VERSION ""

NS_ :

BS_:

BU_: EMS EAS

BO_ 2348941054 TC1: 8 Vector__XXX
 SG_ TrnsShftSlctorDisplayModeSwitch : 54|2@1+ (1,0) [0|3] "" Vector__XXX
 SG_ TransMode4 : 46|2@1+ (1,0) [0|3] "" Vector__XXX
 SG_ TransMode3 : 44|2@1+ (1,0) [0|3] "" Vector__XXX
 SG_ TransMode2 : 42|2@1+ (1,0) [0|3] "" Vector__XXX
 SG_ TransMode1 : 40|2@1+ (1,0) [0|3] "" Vector__XXX
 SG_ DisengageDiffLockRqCentralRear : 36|2@1+ (1,0) [0|3] "" Vector__XXX
 SG_ DisengageDiffLockRqCentralFront : 34|2@1+ (1,0) [0|3] "" Vector__XXX
 SG_ DisengageDiffLockRqCentral : 32|2@1+ (1,0) [0|3] "" Vector__XXX
 SG_ DisengageDiffLockRqRearAxle2 : 30|2@1+ (1,0) [0|3] "" Vector__XXX
 SG_ DisengageDiffLockRqRearAxle1 : 28|2@1+ (1,0) [0|3] "" Vector__XXX
 SG_ DisengageDiffLockRqFrontAxle2 : 26|2@1+ (1,0) [0|3] "" Vector__XXX
 SG_ DisengageDiffLockRqFrontAxle1 : 24|2@1+ (1,0) [0|3] "" Vector__XXX
 SG_ TransRqedGear : 16|8@1+ (1,-125) [-125|125] "" Vector__XXX
 SG_ RqedPercentClutchSlip : 8|8@1+ (0.4,0) [0|100] "%" Vector__XXX
 SG_ DisengageDrivelineRq : 4|2@1+ (1,0) [0|3] "" Vector__XXX
 SG_ TorqueConverterLockupDisableRq : 2|2@1+ (1,0) [0|3] "" Vector__XXX
 SG_ TransGearShiftInhibitRq : 0|2@1+ (1,0) [0|3] "" Vector__XXX

BO_ 2566839806 TC: 8 Vector__XXX
 SG_ EngTurboOilLevelSwitch : 30|2@1+ (1,0) [0|3] "" Vector__XXX
 SG_ EngTurbo1Speed : 8|16@1+ (4,0) [0|257020] "rpm" Vector__XXX
 SG_ EngTurboLubeOilPress1 : 0|8@1+ (4,0) [0|1000] "kPa" Vector__XXX

BO_ 2633911806 TAVG: 8 Vector__XXX
 SG_ EngTotalAverageFuelEconomy : 16|16@1+ (0.00195313,0) [0|125.5] "km/L" Vector__XXX
 SG_ EngTotalAverageFuelRate : 0|16@1+ (0.05,0) [0|3212.75] "L/h" Vector__XXX

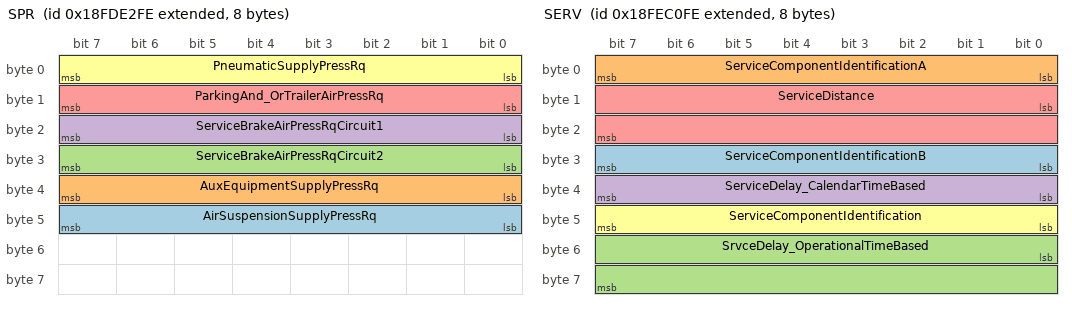
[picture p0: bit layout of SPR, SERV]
BO_ 2566775550 SPR: 8 Vector__XXX
 SG_ AirSuspensionSupplyPressRq : 40|8@1+ (8,0) [0|2000] "kPa" Vector__XXX
 SG_ AuxEquipmentSupplyPressRq : 32|8@1+ (8,0) [0|2000] "kPa" Vector__XXX
 SG_ ServiceBrakeAirPressRqCircuit2 : 24|8@1+ (8,0) [0|2000] "kPa" Vector__XXX
 SG_ ServiceBrakeAirPressRqCircuit1 : 16|8@1+ (8,0) [0|2000] "kPa" Vector__XXX
 SG_ ParkingAnd_OrTrailerAirPressRq : 8|8@1+ (8,0) [0|2000] "kPa" Vector__XXX
 SG_ PneumaticSupplyPressRq : 0|8@1+ (8,0) [0|2000] "kPa" Vector__XXX

BO_ 2566819838 SP2: 8 Vector__XXX
 SG_ EngExtlShutdownAirSupplyPress : 0|16@1+ (0.5,0) [0|32127.5] "kPa" Vector__XXX

BO_ 2566839038 SOFT: 8 Vector__XXX
 SG_ NmbrOfSftwrIdentificationFields : 0|8@1+ (1,0) [0|250] "steps" Vector__XXX

BO_ 2566841598 SHUTDOW: 8 Vector__XXX
 SG_ EngOverspeedTest : 54|2@1+ (1,0) [0|3] "" Vector__XXX
 SG_ EngAirShutoffCmdStatus : 52|2@1+ (1,0) [0|3] "" Vector__XXX
 SG_ EngAlarmOutputCmdStatus : 50|2@1+ (1,0) [0|3] "" Vector__XXX
 SG_ EngAlarmAcknowledge : 48|2@1+ (1,0) [0|3] "" Vector__XXX
 SG_ EngProtectionSystemConfig : 46|2@1+ (1,0) [0|3] "" Vector__XXX
 SG_ EngProtectionSystemTimerState : 38|2@1+ (1,0) [0|3] "" Vector__XXX
 SG_ EngPrtectionSystemTimerOverride : 36|2@1+ (1,0) [0|3] "" Vector__XXX
 SG_ EngPrtctnSystmApprchingShutdown : 34|2@1+ (1,0) [0|3] "" Vector__XXX
 SG_ EngPrtctionSystemHasShutdownEng : 32|2@1+ (1,0) [0|3] "" Vector__XXX
 SG_ EngWaitToStartLamp : 24|2@1+ (1,0) [0|3] "" Vector__XXX
 SG_ RefrigerantHighPressSwitch : 20|2@1+ (1,0) [0|3] "" Vector__XXX
 SG_ RefrigerantLowPressSwitch : 18|2@1+ (1,0) [0|3] "" Vector__XXX
 SG_ A_CHighPressFanSwitch : 16|2@1+ (1,0) [0|3] "" Vector__XXX
 SG_ EngIdleShutdownTimerFunction : 14|2@1+ (1,0) [0|3] "" Vector__XXX
 SG_ EngIdleShutdownTimerState : 6|2@1+ (1,0) [0|3] "" Vector__XXX
 SG_ EngIdleShutdownTimerOverride : 4|2@1+ (1,0) [0|3] "" Vector__XXX
 SG_ EngIdleShutdownDriverAlertMode : 2|2@1+ (1,0) [0|3] "" Vector__XXX
 SG_ EngIdleShutdownHasShutdownEng : 0|2@1+ (1,0) [0|3] "" Vector__XXX

BO_ 2566832382 SERV: 8 Vector__XXX
 SG_ ServiceComponentIdentificationB : 24|8@1+ (1,0) [0|250] "ID" Vector__XXX
 SG_ ServiceComponentIdentificationA : 0|8@1+ (1,0) [0|250] "ID" Vector__XXX
 SG_ SrvceDelay_OperationalTimeBased : 48|16@1+ (1,-31873) [-31873|32128] "hr" Vector__XXX
 SG_ ServiceDelay_CalendarTimeBased : 32|8@1+ (1,-125) [-125|125] "weeks" Vector__XXX
 SG_ ServiceDistance : 8|16@1+ (5,-159365) [-159365|160640] "km" Vector__XXX
 SG_ ServiceComponentIdentification : 40|8@1+ (1,0) [0|250] "ID" Vector__XXX

BO_ 2633928446 S2: 8 Vector__XXX
 SG_ TimeSinceLastService : 8|16@1+ (1,-31873) [-31873|32128] "hr" Vector__XXX
 SG_ ServiceComponentIdentification : 0|8@1+ (1,0) [0|250] "ID" Vector__XXX

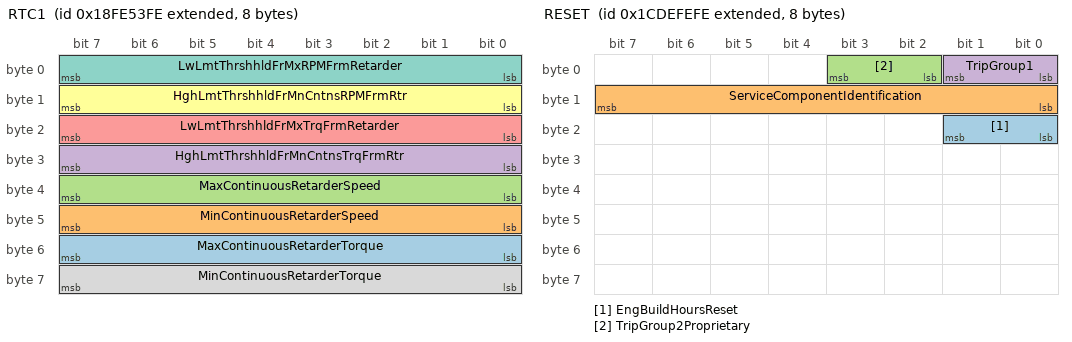
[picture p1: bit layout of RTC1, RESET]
BO_ 2566804478 RTC1: 8 Vector__XXX
 SG_ MaxContinuousRetarderTorque : 48|8@1+ (1,-125) [-125|125] "%" Vector__XXX
 SG_ MinContinuousRetarderSpeed : 40|8@1+ (32,0) [0|8000] "rpm" Vector__XXX
 SG_ MaxContinuousRetarderSpeed : 32|8@1+ (32,0) [0|8000] "rpm" Vector__XXX
 SG_ HghLmtThrshhldFrMnCntnsTrqFrmRtr : 24|8@1+ (1,-125) [-125|125] "%" Vector__XXX
 SG_ LwLmtThrshhldFrMxTrqFrmRetarder : 16|8@1+ (1,-125) [-125|125] "%" Vector__XXX
 SG_ HghLmtThrshhldFrMnCntnsRPMFrmRtr : 8|8@1+ (32,0) [0|8000] "rpm" Vector__XXX
 SG_ LwLmtThrshhldFrMxRPMFrmRetarder : 0|8@1+ (32,0) [0|8000] "rpm" Vector__XXX
 SG_ MinContinuousRetarderTorque : 56|8@1+ (1,-125) [-125|125] "%" Vector__XXX

BO_ 2566847486 RF: 8 Vector__XXX
 SG_ HydRetarderOilTemp : 8|8@1+ (1,-40) [-40|210] "deg" Vector__XXX
 SG_ HydRetarderPress : 0|8@1+ (16,0) [0|4000] "kPa" Vector__XXX

BO_ 2631859966 RESET: 8 Vector__XXX
 SG_ EngBuildHoursReset : 16|2@1+ (1,0) [0|3] "" Vector__XXX
 SG_ ServiceComponentIdentification : 8|8@1+ (1,0) [0|250] "ID" Vector__XXX
 SG_ TripGroup2Proprietary : 2|2@1+ (1,0) [0|3] "" Vector__XXX
 SG_ TripGroup1 : 0|2@1+ (1,0) [0|3] "" Vector__XXX

BO_ 2566840830 RC: 19 Vector__XXX
 SG_ PercentTorqueAtPeakTorquePoint5 : 144|8@1+ (1,-125) [-125|125] "%" Vector__XXX
 SG_ ReferenceRetarderTorque : 128|16@1+ (1,0) [0|64255] "Nm" Vector__XXX
 SG_ RetarderSpeedAtPeakTorquePoint5 : 112|16@1+ (0.125,0) [0|8031.875] "rpm" Vector__XXX
 SG_ PercentTorqueAtPoint4 : 104|8@1+ (1,-125) [-125|125] "%" Vector__XXX
 SG_ RetarderSpeedAtPoint4 : 88|16@1+ (0.125,0) [0|8031.875] "rpm" Vector__XXX
 SG_ PercentTorqueAtPoint3 : 80|8@1+ (1,-125) [-125|125] "%" Vector__XXX
 SG_ RetarderSpeedAtPoint3 : 64|16@1+ (0.125,0) [0|8031.875] "rpm" Vector__XXX
 SG_ PercentTorqueAtMaxSpeedPoint2 : 56|8@1+ (1,-125) [-125|125] "%" Vector__XXX
 SG_ MaxRetarderSpeedPoint2 : 40|16@1+ (0.125,0) [0|8031.875] "rpm" Vector__XXX
 SG_ PercentTorqueAtIdlePoint1 : 32|8@1+ (1,-125) [-125|125] "%" Vector__XXX
 SG_ RetarderSpeedAtIdlePoint1 : 16|16@1+ (0.125,0) [0|8031.875] "rpm" Vector__XXX
 SG_ RetarderCtrlMethod : 8|8@1+ (1,0) [0|250] "steps" Vector__XXX
 SG_ RetarderLocation : 4|4@1+ (1,0) [0|15] "" Vector__XXX
 SG_ RetarderType : 0|4@1+ (1,0) [0|15] "" Vector__XXX

BO_ 2633930238 RBI: 8 Vector__XXX
 SG_ EngOperationTimeSinceRebuild : 0|32@1+ (1,0) [0|4211081215] "s" Vector__XXX

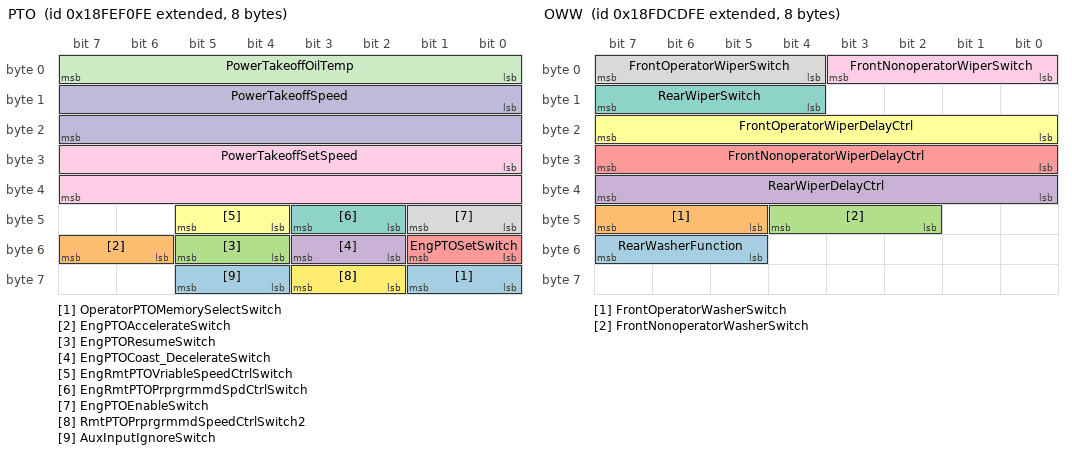
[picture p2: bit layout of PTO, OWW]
BO_ 2566844670 PTO: 8 Vector__XXX
 SG_ OperatorPTOMemorySelectSwitch : 56|2@1+ (1,0) [0|3] "" Vector__XXX
 SG_ EngPTOAccelerateSwitch : 54|2@1+ (1,0) [0|3] "" Vector__XXX
 SG_ EngPTOResumeSwitch : 52|2@1+ (1,0) [0|3] "" Vector__XXX
 SG_ EngPTOCoast_DecelerateSwitch : 50|2@1+ (1,0) [0|3] "" Vector__XXX
 SG_ EngPTOSetSwitch : 48|2@1+ (1,0) [0|3] "" Vector__XXX
 SG_ EngRmtPTOVriableSpeedCtrlSwitch : 44|2@1+ (1,0) [0|3] "" Vector__XXX
 SG_ EngRmtPTOPrprgrmmdSpdCtrlSwitch : 42|2@1+ (1,0) [0|3] "" Vector__XXX
 SG_ EngPTOEnableSwitch : 40|2@1+ (1,0) [0|3] "" Vector__XXX
 SG_ PowerTakeoffSetSpeed : 24|16@1+ (0.125,0) [0|8031.875] "rpm" Vector__XXX
 SG_ PowerTakeoffSpeed : 8|16@1+ (0.125,0) [0|8031.875] "rpm" Vector__XXX
 SG_ PowerTakeoffOilTemp : 0|8@1+ (1,-40) [-40|210] "deg" Vector__XXX
 SG_ RmtPTOPrprgrmmdSpeedCtrlSwitch2 : 58|2@1+ (1,0) [0|3] "" Vector__XXX
 SG_ AuxInputIgnoreSwitch : 60|2@1+ (1,0) [0|3] "" Vector__XXX

BO_ 2566770174 OWW: 8 Vector__XXX
 SG_ RearWasherFunction : 53|3@1+ (1,0) [0|7] "" Vector__XXX
 SG_ FrontOperatorWasherSwitch : 45|3@1+ (1,0) [0|7] "" Vector__XXX
 SG_ FrontNonoperatorWasherSwitch : 42|3@1+ (1,0) [0|7] "" Vector__XXX
 SG_ RearWiperDelayCtrl : 32|8@1+ (0.4,0) [0|100] "%" Vector__XXX
 SG_ FrontNonoperatorWiperDelayCtrl : 24|8@1+ (0.4,0) [0|100] "%" Vector__XXX
 SG_ FrontOperatorWiperDelayCtrl : 16|8@1+ (0.4,0) [0|100] "%" Vector__XXX
 SG_ RearWiperSwitch : 12|4@1+ (1,0) [0|15] "" Vector__XXX
 SG_ FrontOperatorWiperSwitch : 4|4@1+ (1,0) [0|15] "" Vector__XXX
 SG_ FrontNonoperatorWiperSwitch : 0|4@1+ (1,0) [0|15] "" Vector__XXX

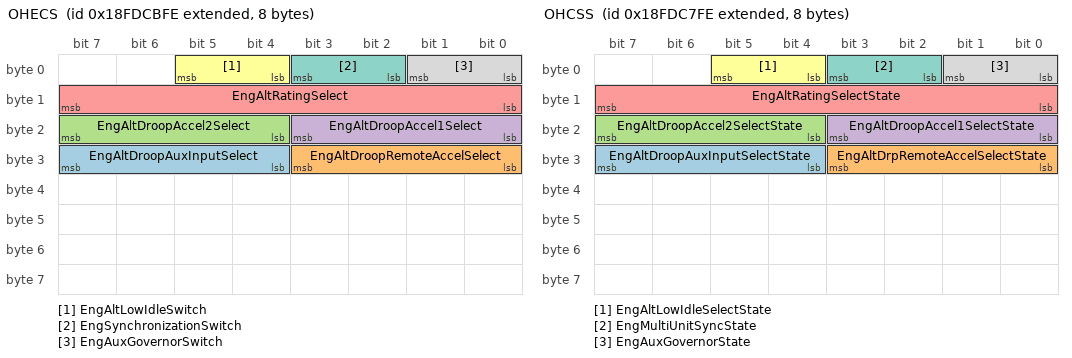
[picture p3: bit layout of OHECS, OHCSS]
BO_ 2566769662 OHECS: 8 Vector__XXX
 SG_ EngAltDroopAuxInputSelect : 28|4@1+ (1,0) [0|15] "" Vector__XXX
 SG_ EngAltDroopRemoteAccelSelect : 24|4@1+ (1,0) [0|15] "" Vector__XXX
 SG_ EngAltDroopAccel2Select : 20|4@1+ (1,0) [0|15] "" Vector__XXX
 SG_ EngAltDroopAccel1Select : 16|4@1+ (1,0) [0|15] "" Vector__XXX
 SG_ EngAltRatingSelect : 8|8@1+ (1,0) [0|255] "" Vector__XXX
 SG_ EngAltLowIdleSwitch : 4|2@1+ (1,0) [0|3] "" Vector__XXX
 SG_ EngSynchronizationSwitch : 2|2@1+ (1,0) [0|3] "" Vector__XXX
 SG_ EngAuxGovernorSwitch : 0|2@1+ (1,0) [0|3] "" Vector__XXX

BO_ 2566768638 OHCSS: 8 Vector__XXX
 SG_ EngAltDroopAuxInputSelectState : 28|4@1+ (1,0) [0|15] "" Vector__XXX
 SG_ EngAltDrpRemoteAccelSelectState : 24|4@1+ (1,0) [0|15] "" Vector__XXX
 SG_ EngAltDroopAccel2SelectState : 20|4@1+ (1,0) [0|15] "" Vector__XXX
 SG_ EngAltDroopAccel1SelectState : 16|4@1+ (1,0) [0|15] "" Vector__XXX
 SG_ EngAltRatingSelectState : 8|8@1+ (1,0) [0|255] "" Vector__XXX
 SG_ EngAltLowIdleSelectState : 4|2@1+ (1,0) [0|3] "" Vector__XXX
 SG_ EngMultiUnitSyncState : 2|2@1+ (1,0) [0|3] "" Vector__XXX
 SG_ EngAuxGovernorState : 0|2@1+ (1,0) [0|3] "" Vector__XXX

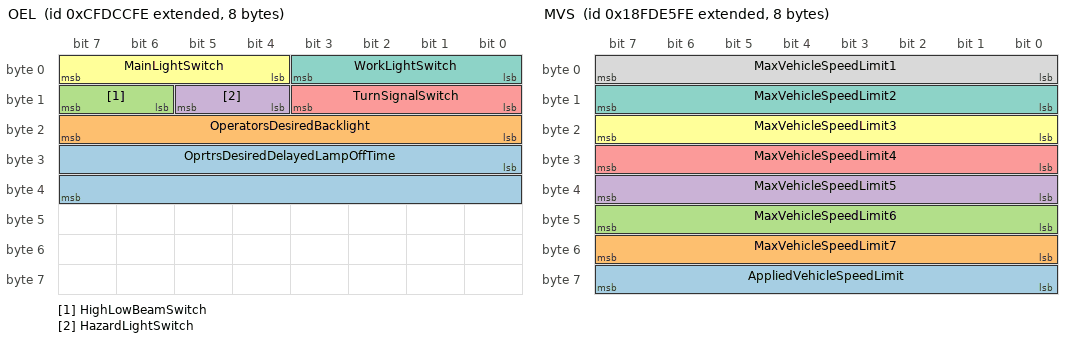
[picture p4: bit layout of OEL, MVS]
BO_ 2365443326 OEL: 8 Vector__XXX
 SG_ OprtrsDesiredDelayedLampOffTime : 24|16@1+ (1,0) [0|64255] "s" Vector__XXX
 SG_ OperatorsDesiredBacklight : 16|8@1+ (0.4,0) [0|100] "%" Vector__XXX
 SG_ HighLowBeamSwitch : 14|2@1+ (1,0) [0|3] "" Vector__XXX
 SG_ HazardLightSwitch : 12|2@1+ (1,0) [0|3] "" Vector__XXX
 SG_ TurnSignalSwitch : 8|4@1+ (1,0) [0|15] "" Vector__XXX
 SG_ MainLightSwitch : 4|4@1+ (1,0) [0|15] "" Vector__XXX
 SG_ WorkLightSwitch : 0|4@1+ (1,0) [0|15] "" Vector__XXX

BO_ 2566776318 MVS: 8 Vector__XXX
 SG_ AppliedVehicleSpeedLimit : 56|8@1+ (1,0) [0|250] "km/h" Vector__XXX
 SG_ MaxVehicleSpeedLimit7 : 48|8@1+ (1,0) [0|250] "km/h" Vector__XXX
 SG_ MaxVehicleSpeedLimit6 : 40|8@1+ (1,0) [0|250] "km/h" Vector__XXX
 SG_ MaxVehicleSpeedLimit5 : 32|8@1+ (1,0) [0|250] "km/h" Vector__XXX
 SG_ MaxVehicleSpeedLimit4 : 24|8@1+ (1,0) [0|250] "km/h" Vector__XXX
 SG_ MaxVehicleSpeedLimit3 : 16|8@1+ (1,0) [0|250] "km/h" Vector__XXX
 SG_ MaxVehicleSpeedLimit2 : 8|8@1+ (1,0) [0|250] "km/h" Vector__XXX
 SG_ MaxVehicleSpeedLimit1 : 0|8@1+ (1,0) [0|250] "km/h" Vector__XXX

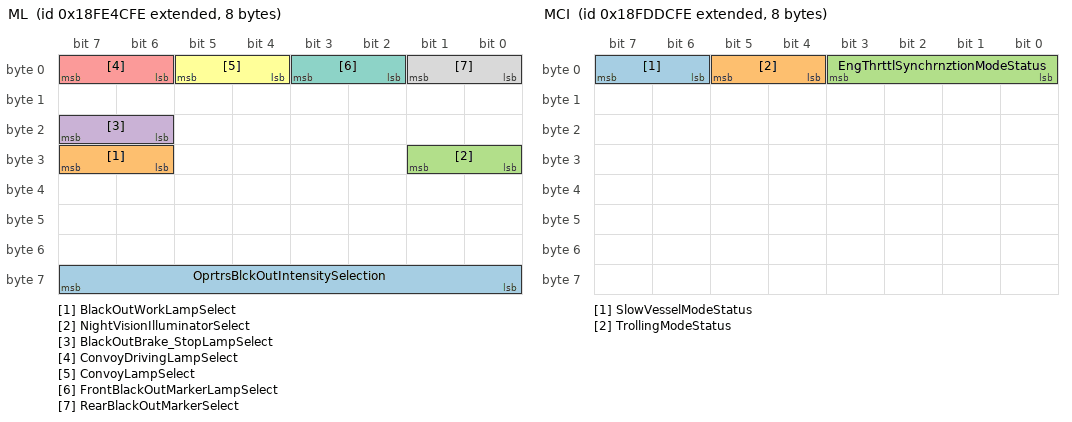
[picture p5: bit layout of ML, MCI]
BO_ 2566802686 ML: 8 Vector__XXX
 SG_ OprtrsBlckOutIntensitySelection : 56|8@1+ (0.4,0) [0|100] "%" Vector__XXX
 SG_ BlackOutWorkLampSelect : 30|2@1+ (1,0) [0|3] "" Vector__XXX
 SG_ NightVisionIlluminatorSelect : 24|2@1+ (1,0) [0|3] "" Vector__XXX
 SG_ BlackOutBrake_StopLampSelect : 22|2@1+ (1,0) [0|3] "" Vector__XXX
 SG_ ConvoyDrivingLampSelect : 6|2@1+ (1,0) [0|3] "" Vector__XXX
 SG_ ConvoyLampSelect : 4|2@1+ (1,0) [0|3] "" Vector__XXX
 SG_ FrontBlackOutMarkerLampSelect : 2|2@1+ (1,0) [0|3] "" Vector__XXX
 SG_ RearBlackOutMarkerSelect : 0|2@1+ (1,0) [0|3] "" Vector__XXX

BO_ 2566774014 MCI: 8 Vector__XXX
 SG_ SlowVesselModeStatus : 6|2@1+ (1,0) [0|3] "" Vector__XXX
 SG_ TrollingModeStatus : 4|2@1+ (1,0) [0|3] "" Vector__XXX
 SG_ EngThrttlSynchrnztionModeStatus : 0|4@1+ (1,0) [0|15] "" Vector__XXX

BO_ 2566823166 MBT3: 8 Vector__XXX
 SG_ EngMainBearing11Temp : 32|16@1+ (0.03125,-273) [-273|1735] "deg" Vector__XXX
 SG_ EngMainBearing10Temp : 16|16@1+ (0.03125,-273) [-273|1735] "deg" Vector__XXX
 SG_ EngMainBearing9Temp : 0|16@1+ (0.03125,-273) [-273|1735] "deg" Vector__XXX

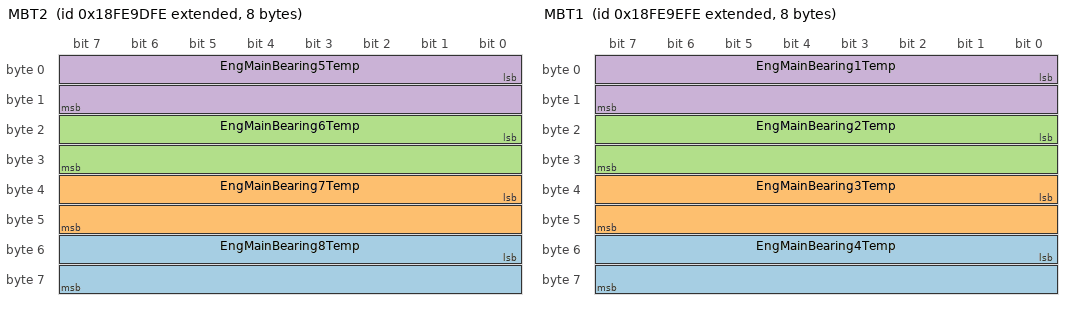
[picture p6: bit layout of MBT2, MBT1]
BO_ 2566823422 MBT2: 8 Vector__XXX
 SG_ EngMainBearing8Temp : 48|16@1+ (0.03125,-273) [-273|1735] "deg" Vector__XXX
 SG_ EngMainBearing7Temp : 32|16@1+ (0.03125,-273) [-273|1735] "deg" Vector__XXX
 SG_ EngMainBearing6Temp : 16|16@1+ (0.03125,-273) [-273|1735] "deg" Vector__XXX
 SG_ EngMainBearing5Temp : 0|16@1+ (0.03125,-273) [-273|1735] "deg" Vector__XXX

BO_ 2566823678 MBT1: 8 Vector__XXX
 SG_ EngMainBearing4Temp : 48|16@1+ (0.03125,-273) [-273|1735] "deg" Vector__XXX
 SG_ EngMainBearing3Temp : 32|16@1+ (0.03125,-273) [-273|1735] "deg" Vector__XXX
 SG_ EngMainBearing2Temp : 16|16@1+ (0.03125,-273) [-273|1735] "deg" Vector__XXX
 SG_ EngMainBearing1Temp : 0|16@1+ (0.03125,-273) [-273|1735] "deg" Vector__XXX

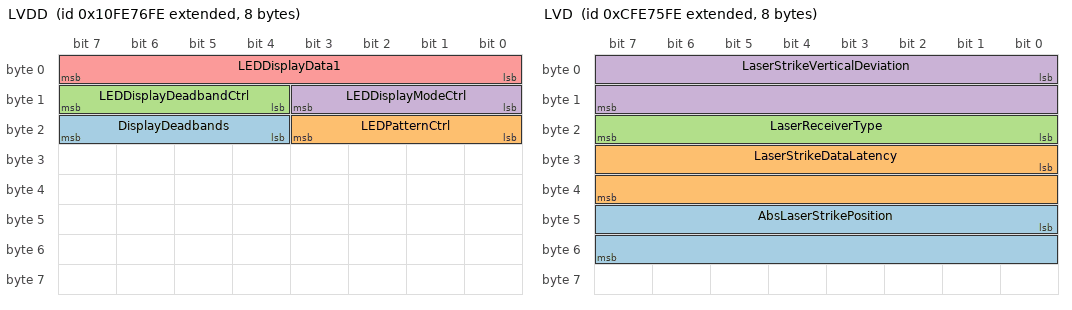
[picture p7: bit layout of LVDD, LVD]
BO_ 2432595710 LVDD: 8 Vector__XXX
 SG_ DisplayDeadbands : 20|4@1+ (1,0) [0|15] "" Vector__XXX
 SG_ LEDPatternCtrl : 16|4@1+ (1,0) [0|15] "" Vector__XXX
 SG_ LEDDisplayDeadbandCtrl : 12|4@1+ (1,0) [0|15] "" Vector__XXX
 SG_ LEDDisplayModeCtrl : 8|4@1+ (1,0) [0|15] "" Vector__XXX
 SG_ LEDDisplayData1 : 0|8@1+ (1,0) [0|255] "" Vector__XXX

BO_ 2365486590 LVD: 8 Vector__XXX
 SG_ AbsLaserStrikePosition : 40|16@1+ (0.1,0) [0|6425.5] "mm" Vector__XXX
 SG_ LaserStrikeDataLatency : 24|16@1+ (51.2,0) [0|3.289856] "s" Vector__XXX
 SG_ LaserReceiverType : 16|8@1+ (1,0) [0|250] "" Vector__XXX
 SG_ LaserStrikeVerticalDeviation : 0|16@1+ (0.1,-2800) [-2800|3225.5] "mm" Vector__XXX

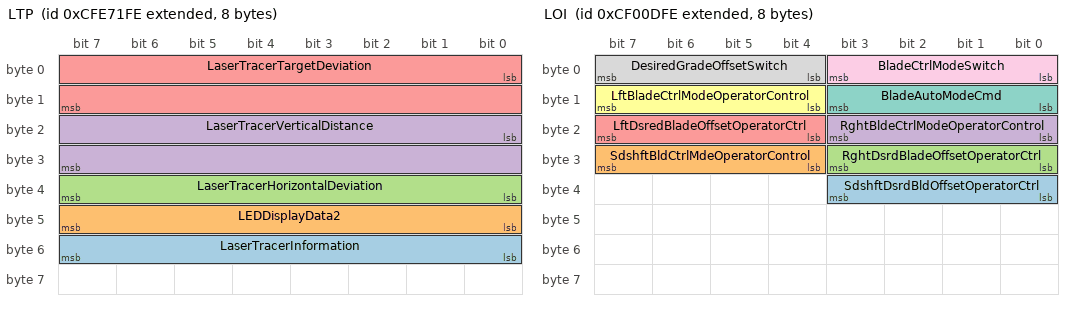
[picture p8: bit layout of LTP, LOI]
BO_ 2365485566 LTP: 8 Vector__XXX
 SG_ LaserTracerInformation : 48|8@1+ (1,0) [0|255] "" Vector__XXX
 SG_ LEDDisplayData2 : 40|8@1+ (1,0) [0|255] "" Vector__XXX
 SG_ LaserTracerHorizontalDeviation : 32|8@1+ (1,0) [0|250] "%" Vector__XXX
 SG_ LaserTracerVerticalDistance : 16|16@1+ (0.1,0) [0|6425.5] "mm" Vector__XXX
 SG_ LaserTracerTargetDeviation : 0|16@1+ (0.1,-2800) [-2800|3225.5] "mm" Vector__XXX

BO_ 2633939454 LTFI: 22 Vector__XXX
 SG_ TripDriveFuelEconomy : 160|16@1+ (0.00195313,0) [0|125.5] "km/L" Vector__XXX
 SG_ TripCruiseFuelUsed : 128|32@1+ (0.5,0) [0|2105540607.5] "kg" Vector__XXX
 SG_ TripVehicleIdleFuelUsed : 96|32@1+ (0.5,0) [0|2105540607.5] "kg" Vector__XXX
 SG_ TripPTONonmovingFuelUsed : 64|32@1+ (0.5,0) [0|2105540607.5] "kg" Vector__XXX
 SG_ TripPTOMovingFuelUsed : 32|32@1+ (0.5,0) [0|2105540607.5] "kg" Vector__XXX
 SG_ TripDriveFuelUsed : 0|32@1+ (0.5,0) [0|2105540607.5] "kg" Vector__XXX

BO_ 2365486334 LSP: 8 Vector__XXX
 SG_ BldHeightSetPointHighResolution : 16|32@1+ (0.1,-209.7152) [-209.7152|211.3929215] "m" Vector__XXX
 SG_ ModifySetPoint : 0|16@1+ (0.1,-2800) [-2800|3225.5] "mm" Vector__XXX

BO_ 2364542462 LOI: 8 Vector__XXX
 SG_ SdshftDsrdBldOffsetOperatorCtrl : 32|4@1+ (1,0) [0|15] "" Vector__XXX
 SG_ SdshftBldCtrlMdeOperatorControl : 28|4@1+ (1,0) [0|15] "" Vector__XXX
 SG_ RghtDsrdBladeOffsetOperatorCtrl : 24|4@1+ (1,0) [0|15] "" Vector__XXX
 SG_ RghtBldeCtrlModeOperatorControl : 16|4@1+ (1,0) [0|15] "" Vector__XXX
 SG_ LftDsredBladeOffsetOperatorCtrl : 20|4@1+ (1,0) [0|15] "" Vector__XXX
 SG_ LftBladeCtrlModeOperatorControl : 12|4@1+ (1,0) [0|15] "" Vector__XXX
 SG_ BladeAutoModeCmd : 8|4@1+ (1,0) [0|15] "" Vector__XXX
 SG_ DesiredGradeOffsetSwitch : 4|4@1+ (1,0) [0|15] "" Vector__XXX
 SG_ BladeCtrlModeSwitch : 0|4@1+ (1,0) [0|15] "" Vector__XXX

BO_ 2365486078 LMP: 8 Vector__XXX
 SG_ MastPos : 0|16@1+ (0.1,-2800) [-2800|3225.5] "mm" Vector__XXX

BO_ 2633937918 LFI: 8 Vector__XXX
 SG_ TripAverageFuelRate : 32|16@1+ (0.05,0) [0|3212.75] "kg/h" Vector__XXX
 SG_ TotalEngPTOFuelUsed : 0|32@1+ (0.5,0) [0|2105540607.5] "kg" Vector__XXX

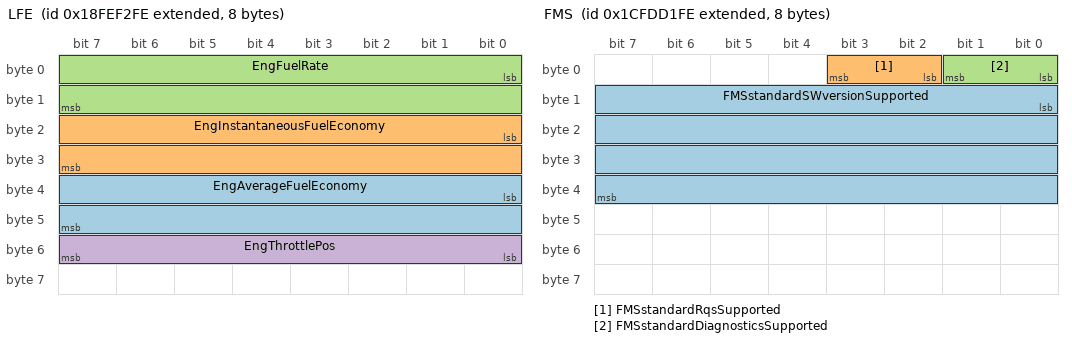
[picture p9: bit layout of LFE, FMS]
BO_ 2566845182 LFE: 8 Vector__XXX
 SG_ EngAverageFuelEconomy : 32|16@1+ (0.001953125,0) [0|125.5] "km/L" Vector__XXX
 SG_ EngInstantaneousFuelEconomy : 16|16@1+ (0.001953125,0) [0|125.5] "km/L" Vector__XXX
 SG_ EngFuelRate : 0|16@1+ (0.05,0) [0|3212.75] "L/h" Vector__XXX
 SG_ EngThrottlePos : 48|8@1+ (0.4,0) [0|100] "%" Vector__XXX

BO_ 2566842878 LFC: 8 Vector__XXX
 SG_ EngTotalFuelUsed : 32|32@1+ (0.5,0) [0|2105540607.5] "L" Vector__XXX
 SG_ EngTripFuel : 0|32@1+ (0.5,0) [0|2105540607.5] "L" Vector__XXX

BO_ 2633883646 FWD: 8 Vector__XXX
 SG_ FrontWheelDriveActuatorStatus : 0|2@1+ (1,0) [0|3] "" Vector__XXX

BO_ 2633880062 FMS: 8 Vector__XXX
 SG_ FMSstandardSWversionSupported : 8|32@1+ (1,0) [0|255] "" Vector__XXX
 SG_ FMSstandardRqsSupported : 2|2@1+ (1,0) [0|3] "" Vector__XXX
 SG_ FMSstandardDiagnosticsSupported : 0|2@1+ (1,0) [0|3] "" Vector__XXX

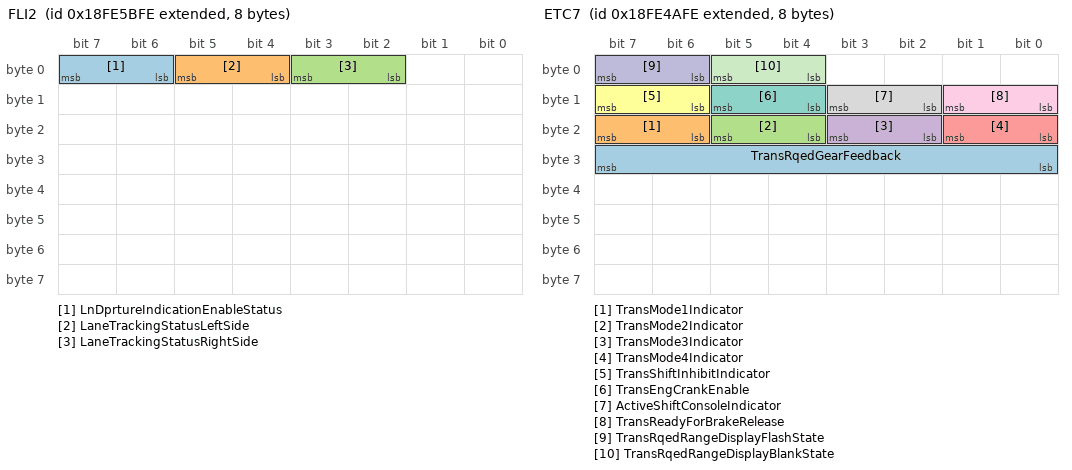
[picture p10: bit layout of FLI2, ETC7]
BO_ 2566806526 FLI2: 8 Vector__XXX
 SG_ LnDprtureIndicationEnableStatus : 6|2@1+ (1,0) [0|3] "" Vector__XXX
 SG_ LaneTrackingStatusLeftSide : 4|2@1+ (1,0) [0|3] "" Vector__XXX
 SG_ LaneTrackingStatusRightSide : 2|2@1+ (1,0) [0|3] "" Vector__XXX

BO_ 2431649790 FLI1: 8 Vector__XXX
 SG_ LaneDepartureImminentLeftSide : 6|2@1+ (1,0) [0|3] "" Vector__XXX
 SG_ LaneDepartureImminentRightSide : 4|2@1+ (1,0) [0|3] "" Vector__XXX

BO_ 2633929214 FL: 8 Vector__XXX
 SG_ EngFuelLeakage2 : 2|2@1+ (1,0) [0|3] "" Vector__XXX
 SG_ EngFuelLeakage1 : 0|2@1+ (1,0) [0|3] "" Vector__XXX

BO_ 2566831614 FD: 8 Vector__XXX
 SG_ FanSpeed : 16|16@1+ (0.125,0) [0|8031.875] "rpm" Vector__XXX
 SG_ FanDriveState : 8|4@1+ (1,0) [0|15] "" Vector__XXX
 SG_ EstPercentFanSpeed : 0|8@1+ (0.4,0) [0|100] "%" Vector__XXX

BO_ 2566820094 ETH: 33 Vector__XXX
 SG_ EngTorqueLimit6AxleInput : 248|16@1+ (2,0) [0|128510] "Nm" Vector__XXX
 SG_ EngTorqueLimit5Switch : 232|16@1+ (1,0) [0|64255] "Nm" Vector__XXX
 SG_ EngTorqueLimit4Trans : 216|16@1+ (1,0) [0|64255] "Nm" Vector__XXX
 SG_ EngTorqueLimit3Trans : 200|16@1+ (1,0) [0|64255] "Nm" Vector__XXX
 SG_ TransGearRatio3 : 184|16@1+ (0.01,0) [0|642.55] "" Vector__XXX
 SG_ EngTorqueLimit2Trans : 168|16@1+ (1,0) [0|64255] "Nm" Vector__XXX
 SG_ TransGearRatio2 : 152|16@1+ (0.01,0) [0|642.55] "" Vector__XXX
 SG_ EngTorqueLimit1Trans : 136|16@1+ (1,0) [0|64255] "Nm" Vector__XXX
 SG_ TransGearRatio1 : 120|16@1+ (0.01,0) [0|642.55] "" Vector__XXX
 SG_ EngTorqueLimitFeature : 114|3@1+ (1,0) [0|7] "" Vector__XXX
 SG_ TorqueLimitingFeatureStatus : 112|2@1+ (1,0) [0|3] "" Vector__XXX
 SG_ CalibRecordDurationTime : 80|32@1+ (0.05,0) [0|210554060.75] "hr" Vector__XXX
 SG_ CalibRecordStartYear : 72|8@1+ (1,1985) [1985|2235] "years" Vector__XXX
 SG_ CalibRecordStartDay : 64|8@1+ (0.25,0) [0|62.5] "days" Vector__XXX
 SG_ CalibRecordStartMonth : 56|8@1+ (1,0) [0|250] "months" Vector__XXX
 SG_ EngPeakTorque2 : 40|16@1+ (1,0) [0|64255] "Nm" Vector__XXX
 SG_ EngPeakTorque1 : 24|16@1+ (1,0) [0|64255] "Nm" Vector__XXX
 SG_ EngPower : 8|16@1+ (0.5,0) [0|32127.5] "kW" Vector__XXX
 SG_ NumberOfEngTorqueHistoryRecords : 0|8@1+ (1,0) [0|250] "records" Vector__XXX

BO_ 2364542206 ETC8: 8 Vector__XXX
 SG_ TransTorqueConverterRatio : 0|16@1+ (0.001,0) [0|64.255] "" Vector__XXX

BO_ 2566802174 ETC7: 8 Vector__XXX
 SG_ TransRqedGearFeedback : 24|8@1+ (1,-125) [-125|125] "" Vector__XXX
 SG_ TransMode1Indicator : 22|2@1+ (1,0) [0|3] "" Vector__XXX
 SG_ TransMode2Indicator : 20|2@1+ (1,0) [0|3] "" Vector__XXX
 SG_ TransMode3Indicator : 18|2@1+ (1,0) [0|3] "" Vector__XXX
 SG_ TransMode4Indicator : 16|2@1+ (1,0) [0|3] "" Vector__XXX
 SG_ TransShiftInhibitIndicator : 14|2@1+ (1,0) [0|3] "" Vector__XXX
 SG_ TransEngCrankEnable : 12|2@1+ (1,0) [0|3] "" Vector__XXX
 SG_ ActiveShiftConsoleIndicator : 10|2@1+ (1,0) [0|3] "" Vector__XXX
 SG_ TransReadyForBrakeRelease : 8|2@1+ (1,0) [0|3] "" Vector__XXX
 SG_ TransRqedRangeDisplayFlashState : 6|2@1+ (1,0) [0|3] "" Vector__XXX
 SG_ TransRqedRangeDisplayBlankState : 4|2@1+ (1,0) [0|3] "" Vector__XXX

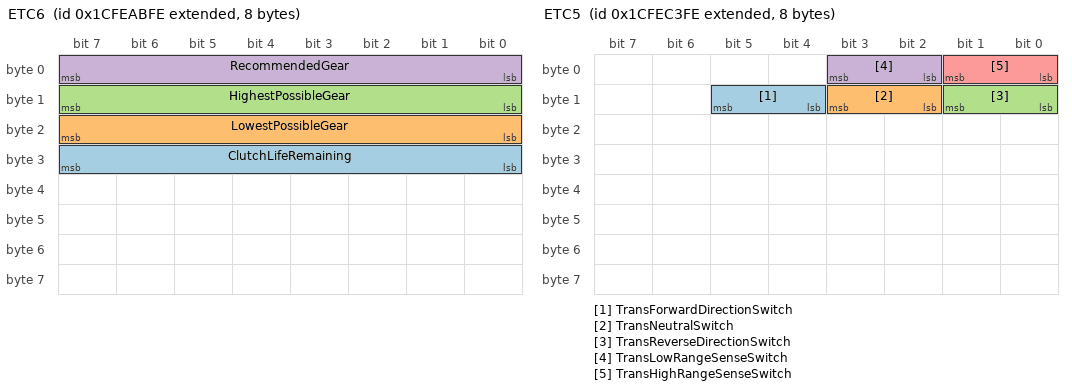
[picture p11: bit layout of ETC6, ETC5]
BO_ 2633935870 ETC6: 8 Vector__XXX
 SG_ ClutchLifeRemaining : 24|8@1+ (0.4,0) [0|100] "%" Vector__XXX
 SG_ LowestPossibleGear : 16|8@1+ (1,-125) [-125|125] "" Vector__XXX
 SG_ HighestPossibleGear : 8|8@1+ (1,-125) [-125|125] "" Vector__XXX
 SG_ RecommendedGear : 0|8@1+ (1,-125) [-125|125] "" Vector__XXX

BO_ 2633942014 ETC5: 8 Vector__XXX
 SG_ TransForwardDirectionSwitch : 12|2@1+ (1,0) [0|3] "" Vector__XXX
 SG_ TransNeutralSwitch : 10|2@1+ (1,0) [0|3] "" Vector__XXX
 SG_ TransReverseDirectionSwitch : 8|2@1+ (1,0) [0|3] "" Vector__XXX
 SG_ TransLowRangeSenseSwitch : 2|2@1+ (1,0) [0|3] "" Vector__XXX
 SG_ TransHighRangeSenseSwitch : 0|2@1+ (1,0) [0|3] "" Vector__XXX

BO_ 2633942526 ETC4: 8 Vector__XXX
 SG_ TransSynchronizerBrakeValue : 8|8@1+ (0.4,0) [0|100] "%" Vector__XXX
 SG_ TransSynchronizerClutchValue : 0|8@1+ (0.4,0) [0|100] "%" Vector__XXX

BO_ 2633943038 ETC3: 8 Vector__XXX
 SG_ TransInertiaBrakeActuator : 46|2@1+ (1,0) [0|3] "" Vector__XXX
 SG_ TransDefuelActuator : 44|2@1+ (1,0) [0|3] "" Vector__XXX
 SG_ TransLockupClutchActuator : 42|2@1+ (1,0) [0|3] "" Vector__XXX
 SG_ TransClutchActuator : 40|2@1+ (1,0) [0|3] "" Vector__XXX
 SG_ TransSplitterIndirectActuator : 38|2@1+ (1,0) [0|3] "" Vector__XXX
 SG_ TransSplitterDirectActuator : 36|2@1+ (1,0) [0|3] "" Vector__XXX
 SG_ TransRangeLowActuator : 34|2@1+ (1,0) [0|3] "" Vector__XXX
 SG_ TransRangeHighActuator : 32|2@1+ (1,0) [0|3] "" Vector__XXX
 SG_ TransShiftFingerGearActuator2 : 30|2@1+ (1,0) [0|3] "" Vector__XXX
 SG_ TransShiftFingerRailActuator2 : 28|2@1+ (1,0) [0|3] "" Vector__XXX
 SG_ TransShiftFingerGearActuator1 : 26|2@1+ (1,0) [0|3] "" Vector__XXX
 SG_ TransShiftFingerRailActuator1 : 24|2@1+ (1,0) [0|3] "" Vector__XXX
 SG_ TrnsShftFngrCenterRailIndicator : 20|2@1+ (1,0) [0|3] "" Vector__XXX
 SG_ TrnsShftFngrEngagementIndicator : 18|2@1+ (1,0) [0|3] "" Vector__XXX
 SG_ TrnsShiftFingerNeutralIndicator : 16|2@1+ (1,0) [0|3] "" Vector__XXX
 SG_ TransShiftFingerRailPos : 8|8@1+ (0.4,0) [0|100] "%" Vector__XXX
 SG_ TransShiftFingerGearPos : 0|8@1+ (0.4,0) [0|100] "%" Vector__XXX

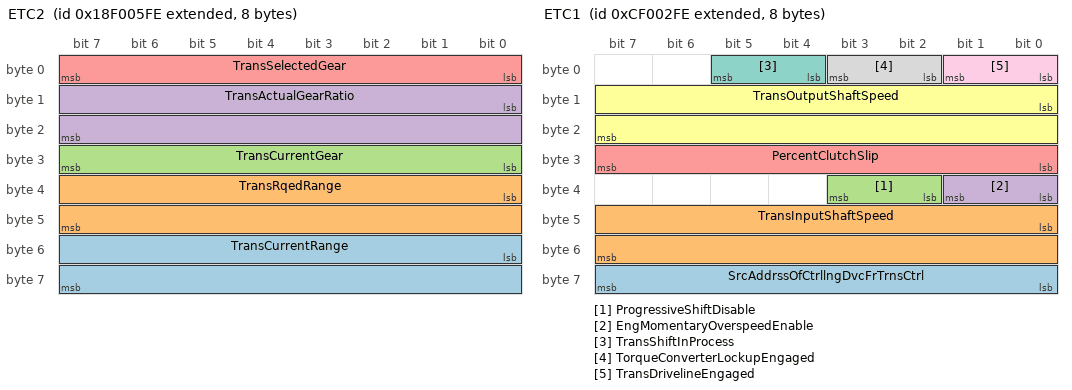
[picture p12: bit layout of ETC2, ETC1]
BO_ 2565867006 ETC2: 8 Vector__XXX
 SG_ TransCurrentRange : 48|16@1+ (1,0) [0|255] "" Vector__XXX
 SG_ TransRqedRange : 32|16@1+ (1,0) [0|255] "" Vector__XXX
 SG_ TransCurrentGear : 24|8@1+ (1,-125) [-125|125] "" Vector__XXX
 SG_ TransActualGearRatio : 8|16@1+ (0.001,0) [0|64.255] "" Vector__XXX
 SG_ TransSelectedGear : 0|8@1+ (1,-125) [-125|125] "" Vector__XXX

BO_ 2364539646 ETC1: 8 Vector__XXX
 SG_ SrcAddrssOfCtrllngDvcFrTrnsCtrl : 56|8@1+ (1,0) [0|255] "" Vector__XXX
 SG_ TransInputShaftSpeed : 40|16@1+ (0.125,0) [0|8031.875] "rpm" Vector__XXX
 SG_ ProgressiveShiftDisable : 34|2@1+ (1,0) [0|3] "" Vector__XXX
 SG_ EngMomentaryOverspeedEnable : 32|2@1+ (1,0) [0|3] "" Vector__XXX
 SG_ PercentClutchSlip : 24|8@1+ (0.4,0) [0|100] "%" Vector__XXX
 SG_ TransOutputShaftSpeed : 8|16@1+ (0.125,0) [0|8031.875] "rpm" Vector__XXX
 SG_ TransShiftInProcess : 4|2@1+ (1,0) [0|3] "" Vector__XXX
 SG_ TorqueConverterLockupEngaged : 2|2@1+ (1,0) [0|3] "" Vector__XXX
 SG_ TransDrivelineEngaged : 0|2@1+ (1,0) [0|3] "" Vector__XXX

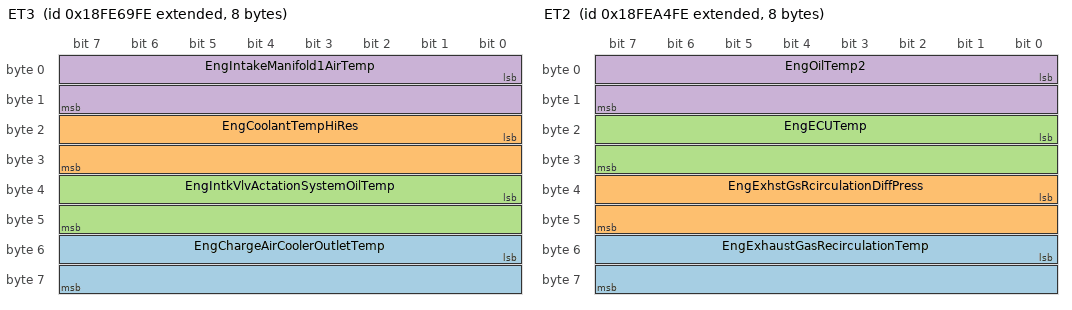
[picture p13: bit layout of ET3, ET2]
BO_ 2566810110 ET3: 8 Vector__XXX
 SG_ EngChargeAirCoolerOutletTemp : 48|16@1+ (0.03125,-273) [-273|1735] "deg" Vector__XXX
 SG_ EngCoolantTempHiRes : 16|16@1+ (0.03125,-273) [-273|1735] "deg" Vector__XXX
 SG_ EngIntkVlvActationSystemOilTemp : 32|16@1+ (0.03125,-273) [-273|1735] "deg" Vector__XXX
 SG_ EngIntakeManifold1AirTemp : 0|16@1+ (0.03125,-273) [-273|1735] "deg" Vector__XXX

BO_ 2566825214 ET2: 8 Vector__XXX
 SG_ EngExhaustGasRecirculationTemp : 48|16@1+ (0.03125,-273) [-273|1735] "deg" Vector__XXX
 SG_ EngExhstGsRcirculationDiffPress : 32|16@1+ (0.0078125,-250) [-250|251.99] "kPa" Vector__XXX
 SG_ EngECUTemp : 16|16@1+ (0.03125,-273) [-273|1735] "deg" Vector__XXX
 SG_ EngOilTemp2 : 0|16@1+ (0.03125,-273) [-273|1735] "deg" Vector__XXX

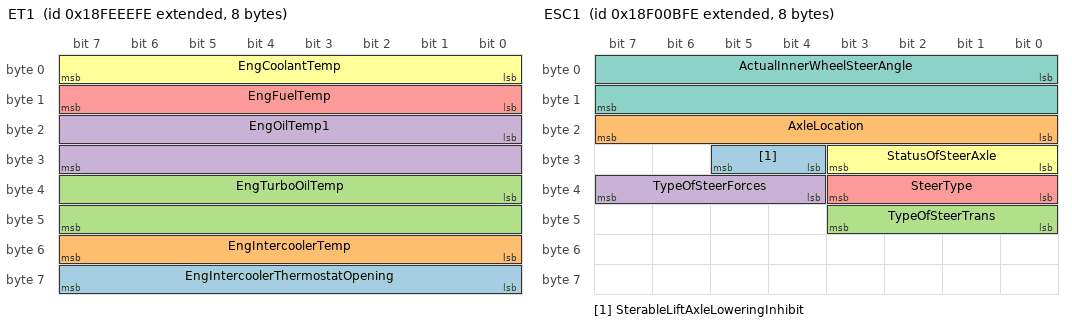
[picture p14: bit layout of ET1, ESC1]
BO_ 2566844158 ET1: 8 Vector__XXX
 SG_ EngIntercoolerThermostatOpening : 56|8@1+ (0.4,0) [0|100] "%" Vector__XXX
 SG_ EngIntercoolerTemp : 48|8@1+ (1,-40) [-40|210] "deg" Vector__XXX
 SG_ EngTurboOilTemp : 32|16@1+ (0.03125,-273) [-273|1735] "deg" Vector__XXX
 SG_ EngOilTemp1 : 16|16@1+ (0.03125,-273) [-273|1735] "deg" Vector__XXX
 SG_ EngFuelTemp : 8|8@1+ (1,-40) [-40|210] "deg" Vector__XXX
 SG_ EngCoolantTemp : 0|8@1+ (1,-40) [-40|210] "deg" Vector__XXX

BO_ 2566785022 ET: 8 Vector__XXX
 SG_ EngExhstExhstGsTempLeftManifold : 16|16@1+ (0.03125,-273) [-273|1735] "deg" Vector__XXX
 SG_ EngExhstExhstGsTmpRightManifold : 0|16@1+ (0.03125,-273) [-273|1735] "deg" Vector__XXX

BO_ 2565868542 ESC1: 8 Vector__XXX
 SG_ SterableLiftAxleLoweringInhibit : 28|2@1+ (1,0) [0|3] "" Vector__XXX
 SG_ AxleLocation : 16|8@1+ (1,0) [0|255] "" Vector__XXX
 SG_ TypeOfSteerTrans : 40|4@1+ (1,0) [0|15] "" Vector__XXX
 SG_ TypeOfSteerForces : 36|4@1+ (1,0) [0|15] "" Vector__XXX
 SG_ SteerType : 32|4@1+ (1,0) [0|15] "" Vector__XXX
 SG_ StatusOfSteerAxle : 24|4@1+ (1,0) [0|15] "" Vector__XXX
 SG_ ActualInnerWheelSteerAngle : 0|16@1+ (0.00390625,-125) [-125|125] "deg" Vector__XXX

BO_ 2633941758 ERC2: 8 Vector__XXX
 SG_ TransOutputRetarder : 0|2@1+ (1,0) [0|3] "" Vector__XXX

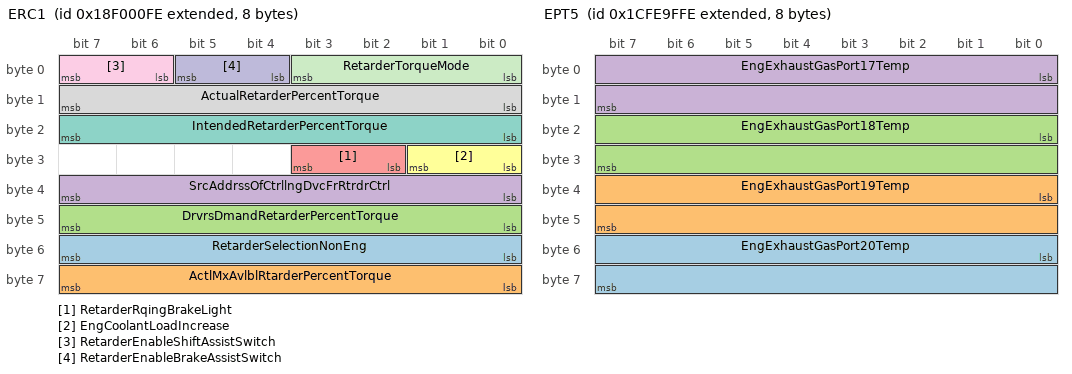
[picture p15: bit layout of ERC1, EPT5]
BO_ 2565865726 ERC1: 8 Vector__XXX
 SG_ RetarderSelectionNonEng : 48|8@1+ (0.4,0) [0|100] "%" Vector__XXX
 SG_ ActlMxAvlblRtarderPercentTorque : 56|8@1+ (1,-125) [-125|125] "%" Vector__XXX
 SG_ DrvrsDmandRetarderPercentTorque : 40|8@1+ (1,-125) [-125|125] "%" Vector__XXX
 SG_ SrcAddrssOfCtrllngDvcFrRtrdrCtrl : 32|8@1+ (1,0) [0|255] "" Vector__XXX
 SG_ RetarderRqingBrakeLight : 26|2@1+ (1,0) [0|3] "" Vector__XXX
 SG_ EngCoolantLoadIncrease : 24|2@1+ (1,0) [0|3] "" Vector__XXX
 SG_ IntendedRetarderPercentTorque : 16|8@1+ (1,-125) [-125|125] "%" Vector__XXX
 SG_ ActualRetarderPercentTorque : 8|8@1+ (1,-125) [-125|125] "%" Vector__XXX
 SG_ RetarderEnableShiftAssistSwitch : 6|2@1+ (1,0) [0|3] "" Vector__XXX
 SG_ RetarderEnableBrakeAssistSwitch : 4|2@1+ (1,0) [0|3] "" Vector__XXX
 SG_ RetarderTorqueMode : 0|4@1+ (1,0) [0|15] "" Vector__XXX

BO_ 2633932798 EPT5: 8 Vector__XXX
 SG_ EngExhaustGasPort20Temp : 48|16@1+ (0.03125,-273) [-273|1735] "deg" Vector__XXX
 SG_ EngExhaustGasPort19Temp : 32|16@1+ (0.03125,-273) [-273|1735] "deg" Vector__XXX
 SG_ EngExhaustGasPort18Temp : 16|16@1+ (0.03125,-273) [-273|1735] "deg" Vector__XXX
 SG_ EngExhaustGasPort17Temp : 0|16@1+ (0.03125,-273) [-273|1735] "deg" Vector__XXX

BO_ 2566824190 EPT4: 8 Vector__XXX
 SG_ EngExhaustGasPort16Temp : 48|16@1+ (0.03125,-273) [-273|1735] "deg" Vector__XXX
 SG_ EngExhaustGasPort15Temp : 32|16@1+ (0.03125,-273) [-273|1735] "deg" Vector__XXX
 SG_ EngExhaustGasPort14Temp : 16|16@1+ (0.03125,-273) [-273|1735] "deg" Vector__XXX
 SG_ EngExhaustGasPort13Temp : 0|16@1+ (0.03125,-273) [-273|1735] "deg" Vector__XXX

BO_ 2633933310 EPT3: 8 Vector__XXX
 SG_ EngExhaustGasPort12Temp : 48|16@1+ (0.03125,-273) [-273|1735] "deg" Vector__XXX
 SG_ EngExhaustGasPort11Temp : 32|16@1+ (0.03125,-273) [-273|1735] "deg" Vector__XXX
 SG_ EngExhaustGasPort10Temp : 16|16@1+ (0.03125,-273) [-273|1735] "deg" Vector__XXX
 SG_ EngExhaustGasPort9Temp : 0|16@1+ (0.03125,-273) [-273|1735] "deg" Vector__XXX

BO_ 2633933566 EPT2: 8 Vector__XXX
 SG_ EngExhaustGasPort8Temp : 48|16@1+ (0.03125,-273) [-273|1735] "deg" Vector__XXX
 SG_ EngExhaustGasPort7Temp : 32|16@1+ (0.03125,-273) [-273|1735] "deg" Vector__XXX
 SG_ EngExhaustGasPort6Temp : 16|16@1+ (0.03125,-273) [-273|1735] "deg" Vector__XXX
 SG_ EngExhaustGasPort5Temp : 0|16@1+ (0.03125,-273) [-273|1735] "deg" Vector__XXX

BO_ 2633933822 EPT1: 8 Vector__XXX
 SG_ EngExhaustGasPort4Temp : 48|16@1+ (0.03125,-273) [-273|1735] "deg" Vector__XXX
 SG_ EngExhaustGasPort3Temp : 32|16@1+ (0.03125,-273) [-273|1735] "deg" Vector__XXX
 SG_ EngExhaustGasPort2Temp : 16|16@1+ (0.03125,-273) [-273|1735] "deg" Vector__XXX
 SG_ EngExhaustGasPort1Temp : 0|16@1+ (0.03125,-273) [-273|1735] "deg" Vector__XXX

BO_ 2566776062 EPD: 8 Vector__XXX
 SG_ PayloadPercentage : 0|8@1+ (1,0) [0|250] "%" Vector__XXX

BO_ 2566771454 EP: 8 Vector__XXX
 SG_ DataMemoryUsage : 16|8@1+ (0.4,0) [0|100] "%" Vector__XXX
 SG_ KeepAliveBatteryConsumption : 0|16@1+ (1,0) [0|64255] "mAhr" Vector__XXX

BO_ 2566775806 EOAC: 8 Vector__XXX
 SG_ TravelVelocityCtrlPos : 0|8@1+ (1,-125) [-125|125] "%" Vector__XXX

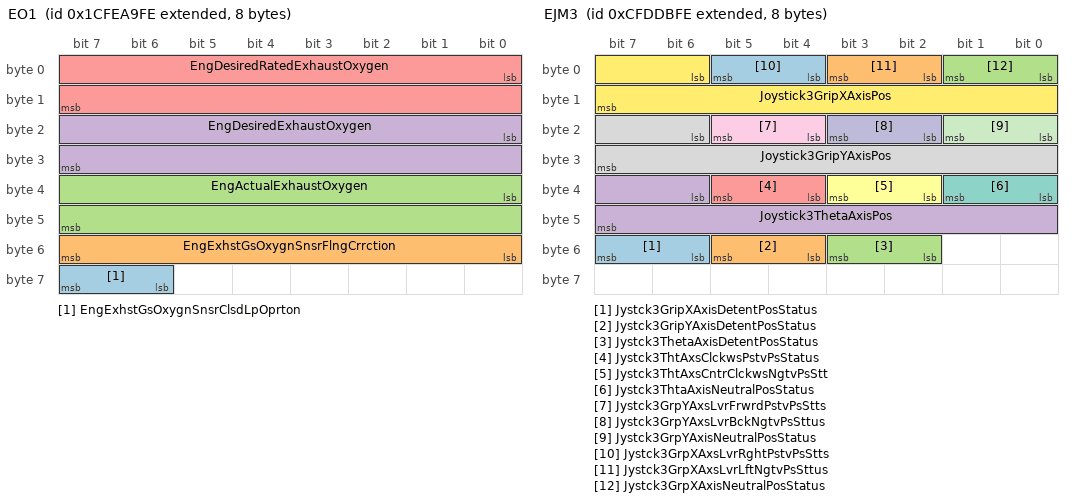
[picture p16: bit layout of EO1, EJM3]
BO_ 2633935358 EO1: 8 Vector__XXX
 SG_ EngExhstGsOxygnSnsrClsdLpOprton : 62|2@1+ (1,0) [0|3] "" Vector__XXX
 SG_ EngExhstGsOxygnSnsrFlngCrrction : 48|8@1+ (1,-125) [-125|125] "%" Vector__XXX
 SG_ EngActualExhaustOxygen : 32|16@1+ (0.0025,0) [0|160.6375] "%" Vector__XXX
 SG_ EngDesiredExhaustOxygen : 16|16@1+ (0.0025,0) [0|160.6375] "%" Vector__XXX
 SG_ EngDesiredRatedExhaustOxygen : 0|16@1+ (0.0025,0) [0|160.6375] "%" Vector__XXX

BO_ 2365447166 EJM3: 8 Vector__XXX
 SG_ Jystck3GripXAxisDetentPosStatus : 54|2@1+ (1,0) [0|3] "" Vector__XXX
 SG_ Jystck3GripYAxisDetentPosStatus : 52|2@1+ (1,0) [0|3] "" Vector__XXX
 SG_ Jystck3ThetaAxisDetentPosStatus : 50|2@1+ (1,0) [0|3] "" Vector__XXX
 SG_ Joystick3ThetaAxisPos : 38|10@1+ (0.1,0) [0|102] "%" Vector__XXX
 SG_ Jystck3ThtAxsClckwsPstvPsStatus : 36|2@1+ (1,0) [0|3] "" Vector__XXX
 SG_ Jystck3ThtAxsCntrClckwsNgtvPsStt : 34|2@1+ (1,0) [0|3] "" Vector__XXX
 SG_ Jystck3ThtaAxisNeutralPosStatus : 32|2@1+ (1,0) [0|3] "" Vector__XXX
 SG_ Joystick3GripYAxisPos : 22|10@1+ (0.1,0) [0|102] "%" Vector__XXX
 SG_ Jystck3GrpYAxsLvrFrwrdPstvPsStts : 20|2@1+ (1,0) [0|3] "" Vector__XXX
 SG_ Jystck3GrpYAxsLvrBckNgtvPsSttus : 18|2@1+ (1,0) [0|3] "" Vector__XXX
 SG_ Jystck3GrpYAxisNeutralPosStatus : 16|2@1+ (1,0) [0|3] "" Vector__XXX
 SG_ Joystick3GripXAxisPos : 6|10@1+ (0.1,0) [0|102] "%" Vector__XXX
 SG_ Jystck3GrpXAxsLvrRghtPstvPsStts : 4|2@1+ (1,0) [0|3] "" Vector__XXX
 SG_ Jystck3GrpXAxsLvrLftNgtvPsSttus : 2|2@1+ (1,0) [0|3] "" Vector__XXX
 SG_ Jystck3GrpXAxisNeutralPosStatus : 0|2@1+ (1,0) [0|3] "" Vector__XXX

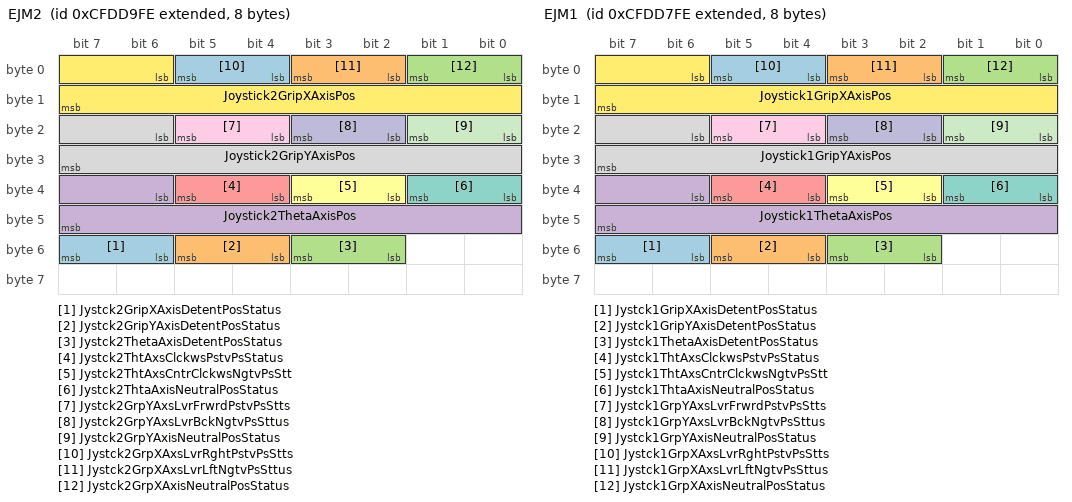
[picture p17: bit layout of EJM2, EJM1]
BO_ 2365446654 EJM2: 8 Vector__XXX
 SG_ Jystck2GripXAxisDetentPosStatus : 54|2@1+ (1,0) [0|3] "" Vector__XXX
 SG_ Jystck2GripYAxisDetentPosStatus : 52|2@1+ (1,0) [0|3] "" Vector__XXX
 SG_ Jystck2ThetaAxisDetentPosStatus : 50|2@1+ (1,0) [0|3] "" Vector__XXX
 SG_ Joystick2ThetaAxisPos : 38|10@1+ (0.1,0) [0|102] "%" Vector__XXX
 SG_ Jystck2ThtAxsClckwsPstvPsStatus : 36|2@1+ (1,0) [0|3] "" Vector__XXX
 SG_ Jystck2ThtAxsCntrClckwsNgtvPsStt : 34|2@1+ (1,0) [0|3] "" Vector__XXX
 SG_ Jystck2ThtaAxisNeutralPosStatus : 32|2@1+ (1,0) [0|3] "" Vector__XXX
 SG_ Joystick2GripYAxisPos : 22|10@1+ (0.1,0) [0|102] "%" Vector__XXX
 SG_ Jystck2GrpYAxsLvrFrwrdPstvPsStts : 20|2@1+ (1,0) [0|3] "" Vector__XXX
 SG_ Jystck2GrpYAxsLvrBckNgtvPsSttus : 18|2@1+ (1,0) [0|3] "" Vector__XXX
 SG_ Jystck2GrpYAxisNeutralPosStatus : 16|2@1+ (1,0) [0|3] "" Vector__XXX
 SG_ Joystick2GripXAxisPos : 6|10@1+ (0.1,0) [0|102] "%" Vector__XXX
 SG_ Jystck2GrpXAxsLvrRghtPstvPsStts : 4|2@1+ (1,0) [0|3] "" Vector__XXX
 SG_ Jystck2GrpXAxsLvrLftNgtvPsSttus : 2|2@1+ (1,0) [0|3] "" Vector__XXX
 SG_ Jystck2GrpXAxisNeutralPosStatus : 0|2@1+ (1,0) [0|3] "" Vector__XXX

BO_ 2365446142 EJM1: 8 Vector__XXX
 SG_ Jystck1GripXAxisDetentPosStatus : 54|2@1+ (1,0) [0|3] "" Vector__XXX
 SG_ Jystck1GripYAxisDetentPosStatus : 52|2@1+ (1,0) [0|3] "" Vector__XXX
 SG_ Jystck1ThetaAxisDetentPosStatus : 50|2@1+ (1,0) [0|3] "" Vector__XXX
 SG_ Joystick1ThetaAxisPos : 38|10@1+ (0.1,0) [0|102] "%" Vector__XXX
 SG_ Jystck1ThtAxsClckwsPstvPsStatus : 36|2@1+ (1,0) [0|3] "" Vector__XXX
 SG_ Jystck1ThtAxsCntrClckwsNgtvPsStt : 34|2@1+ (1,0) [0|3] "" Vector__XXX
 SG_ Jystck1ThtaAxisNeutralPosStatus : 32|2@1+ (1,0) [0|3] "" Vector__XXX
 SG_ Joystick1GripYAxisPos : 22|10@1+ (0.1,0) [0|102] "%" Vector__XXX
 SG_ Jystck1GrpYAxsLvrFrwrdPstvPsStts : 20|2@1+ (1,0) [0|3] "" Vector__XXX
 SG_ Jystck1GrpYAxsLvrBckNgtvPsSttus : 18|2@1+ (1,0) [0|3] "" Vector__XXX
 SG_ Jystck1GrpYAxisNeutralPosStatus : 16|2@1+ (1,0) [0|3] "" Vector__XXX
 SG_ Joystick1GripXAxisPos : 6|10@1+ (0.1,0) [0|102] "%" Vector__XXX
 SG_ Jystck1GrpXAxsLvrRghtPstvPsStts : 4|2@1+ (1,0) [0|3] "" Vector__XXX
 SG_ Jystck1GrpXAxsLvrLftNgtvPsSttus : 2|2@1+ (1,0) [0|3] "" Vector__XXX
 SG_ Jystck1GrpXAxisNeutralPosStatus : 0|2@1+ (1,0) [0|3] "" Vector__XXX

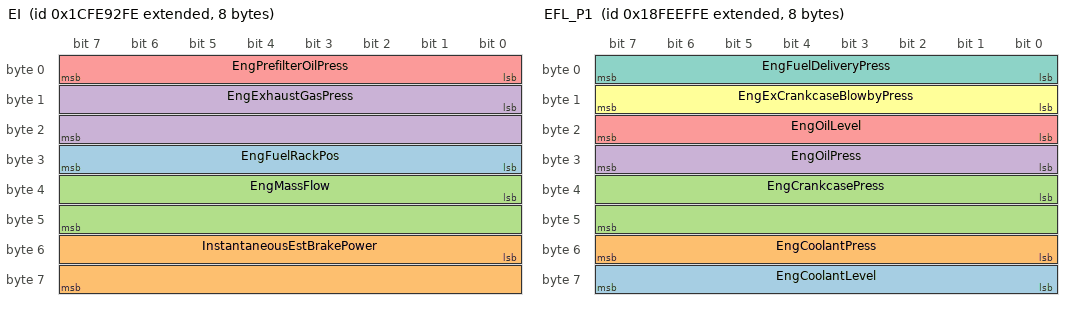
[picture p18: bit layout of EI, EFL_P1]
BO_ 2633929470 EI: 8 Vector__XXX
 SG_ EngFuelRackPos : 24|8@1+ (0.4,0) [0|100] "%" Vector__XXX
 SG_ InstantaneousEstBrakePower : 48|16@1+ (0.5,0) [0|32127.5] "kW" Vector__XXX
 SG_ EngMassFlow : 32|16@1+ (0.05,0) [0|3212.75] "kg/h" Vector__XXX
 SG_ EngExhaustGasPress : 8|16@1+ (0.0078125,-250) [-250|251.99] "kPa" Vector__XXX
 SG_ EngPrefilterOilPress : 0|8@1+ (4,0) [0|1000] "kPa" Vector__XXX

BO_ 2633937406 EH: 8 Vector__XXX
 SG_ TotalECURunTime : 32|32@1+ (0.05,0) [0|210554060.75] "hr" Vector__XXX
 SG_ TotalECUDistance : 0|32@1+ (0.125,0) [0|526385151.9] "km" Vector__XXX

BO_ 2364541694 EGF1: 8 Vector__XXX
 SG_ EngInletAirMassFlowRate : 16|16@1+ (0.05,0) [0|3212.75] "kg/h" Vector__XXX
 SG_ EngExhstGsRcrcltionMassFlowRate : 0|16@1+ (0.05,0) [0|3212.75] "kg/h" Vector__XXX

BO_ 2566810366 EFS: 8 Vector__XXX
 SG_ EngFuelFilterSucSideDiffPress : 16|8@1+ (2,0) [0|500] "kPa" Vector__XXX
 SG_ EngFuelSupplyPumpInletPress : 8|8@1+ (2,0) [0|500] "kPa" Vector__XXX
 SG_ EngOilLevelRemoteReservoir : 0|8@1+ (0.4,0) [0|100] "%" Vector__XXX

BO_ 2566767102 EFL_P3: 8 Vector__XXX
 SG_ EngExhstGsRcrculationInletPress : 16|8@1+ (2,0) [0|500] "kPa" Vector__XXX
 SG_ EngIntkVlvActtionSystemOilPress : 0|16@1+ (0.00390625,0) [0|251] "Mpa" Vector__XXX

BO_ 2566839294 EFL_P2: 8 Vector__XXX
 SG_ EngInjectorMeteringRail2Press : 48|16@1+ (0.00390625,0) [0|251] "MPa" Vector__XXX
 SG_ EngInjectorTimingRail1Press : 32|16@1+ (0.00390625,0) [0|251] "Mpa" Vector__XXX
 SG_ EngInjectorMeteringRail1Press : 16|16@1+ (0.00390625,0) [0|251] "MPa" Vector__XXX
 SG_ EngInjectionCtrlPress : 0|16@1+ (0.00390625,0) [0|251] "MPa" Vector__XXX

BO_ 2566844414 EFL_P1: 8 Vector__XXX
 SG_ EngCoolantLevel : 56|8@1+ (0.4,0) [0|100] "%" Vector__XXX
 SG_ EngCoolantPress : 48|8@1+ (2,0) [0|500] "kPa" Vector__XXX
 SG_ EngCrankcasePress : 32|16@1+ (0.0078125,-250) [-250|251.99] "kPa" Vector__XXX
 SG_ EngOilPress : 24|8@1+ (4,0) [0|1000] "kPa" Vector__XXX
 SG_ EngOilLevel : 16|8@1+ (0.4,0) [0|100] "%" Vector__XXX
 SG_ EngExCrankcaseBlowbyPress : 8|8@1+ (0.05,0) [0|12.5] "kPa" Vector__XXX
 SG_ EngFuelDeliveryPress : 0|8@1+ (4,0) [0|1000] "kPa" Vector__XXX

BO_ 2633929726 EES: 8 Vector__XXX
 SG_ TurningGearEngaged : 18|2@1+ (1,0) [0|3] "" Vector__XXX
 SG_ SafetyWireStatus : 16|2@1+ (1,0) [0|3] "" Vector__XXX
 SG_ ElectricalLoad : 0|16@1+ (0.5,0) [0|32127.5] "kW" Vector__XXX

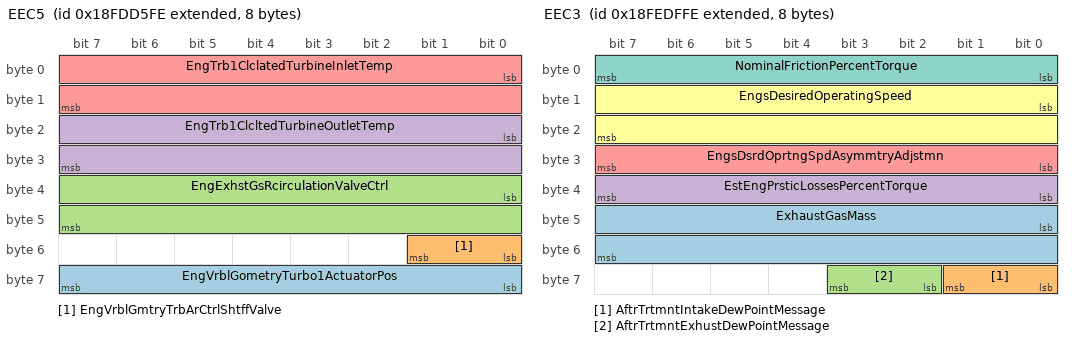
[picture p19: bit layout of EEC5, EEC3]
BO_ 2566772222 EEC5: 8 Vector__XXX
 SG_ EngVrblGometryTurbo1ActuatorPos : 56|8@1+ (0.4,0) [0|100] "%" Vector__XXX
 SG_ EngVrblGmtryTrbArCtrlShtffValve : 48|2@1+ (1,0) [0|3] "" Vector__XXX
 SG_ EngExhstGsRcirculationValveCtrl : 32|16@1+ (0.0025,0) [0|160.6375] "%" Vector__XXX
 SG_ EngTrb1ClcltedTurbineOutletTemp : 16|16@1+ (0.03125,-273) [-273|1735] "deg" Vector__XXX
 SG_ EngTrb1ClclatedTurbineInletTemp : 0|16@1+ (0.03125,-273) [-273|1735] "deg" Vector__XXX

BO_ 2633940734 EEC4: 8 Vector__XXX
 SG_ EngRatedSpeed : 16|16@1+ (0.125,0) [0|8031.875] "rpm" Vector__XXX
 SG_ EngRatedPower : 0|16@1+ (0.5,0) [0|32127.5] "kW" Vector__XXX

BO_ 2566840318 EEC3: 8 Vector__XXX
 SG_ ExhaustGasMass : 40|16@1+ (2,0) [0|128510] "kg" Vector__XXX
 SG_ AftrTrtmntIntakeDewPointMessage : 56|2@1+ (1,0) [0|3] "" Vector__XXX
 SG_ AftrTrtmntExhustDewPointMessage : 58|2@1+ (1,0) [0|3] "" Vector__XXX
 SG_ EstEngPrsticLossesPercentTorque : 32|8@1+ (1,-125) [-125|125] "%" Vector__XXX
 SG_ EngsDsrdOprtngSpdAsymmtryAdjstmn : 24|8@1+ (1,0) [0|250] "" Vector__XXX
 SG_ EngsDesiredOperatingSpeed : 8|16@1+ (0.125,0) [0|8031.875] "rpm" Vector__XXX
 SG_ NominalFrictionPercentTorque : 0|8@1+ (1,-125) [-125|125] "%" Vector__XXX

CM_ BO_ 2348941054 "Transmission Control 1";
CM_ SG_ 2348941054 TrnsShftSlctorDisplayModeSwitch "Status of the operator’s switch used to ‘toggle’ through multiple display modes of a shift selector display.";
CM_ SG_ 2348941054 TransMode4 "Indicates whether transmission mode 4 is enabled.";
CM_ SG_ 2348941054 TransMode3 "Indicates whether transmission mode 3 is enabled.";
CM_ SG_ 2348941054 TransMode2 "Indicates whether transmission mode 2 is enabled.";
CM_ SG_ 2348941054 TransMode1 "Indicates whether transmission mode 1 is enabled.";
CM_ SG_ 2348941054 DisengageDiffLockRqCentralRear "Command signal used to disengage the various differential locks, e.";
CM_ SG_ 2348941054 DisengageDiffLockRqCentralFront "Command signal used to disengage the various differential locks, e.";
CM_ SG_ 2348941054 DisengageDiffLockRqCentral "Command signal used to disengage the various differential locks, e.";
CM_ SG_ 2348941054 DisengageDiffLockRqRearAxle2 "Command signal used to disengage the various differential locks, e.";
CM_ SG_ 2348941054 DisengageDiffLockRqRearAxle1 "Command signal used to disengage the various differential locks, e.";
CM_ SG_ 2348941054 DisengageDiffLockRqFrontAxle2 "Command signal used to disengage the various differential locks, e.";
CM_ SG_ 2348941054 DisengageDiffLockRqFrontAxle1 "Command signal used to disengage the various differential locks, e.";
CM_ SG_ 2348941054 TransRqedGear "Gear requested by the operator, ABS, or engine.";
CM_ SG_ 2348941054 RqedPercentClutchSlip "Parameter which represents the percent clutch slip requested by a device.";
CM_ SG_ 2348941054 DisengageDrivelineRq "Command signal used to simply disengage the driveline, e.";
CM_ SG_ 2348941054 TorqueConverterLockupDisableRq "Command signal to prevent torque converter lockup, which may cause problems in certain circumstances for ASR.";
CM_ SG_ 2348941054 TransGearShiftInhibitRq "Command signal to inhibit gear shifts.";
CM_ BO_ 2566839806 "Turbocharger";
CM_ SG_ 2566839806 EngTurbo1Speed "Rotational velocity of rotor in the turbocharger.";
CM_ SG_ 2566839806 EngTurboLubeOilPress1 "Gage pressure of oil in turbocharger lubrication system.";
CM_ BO_ 2633911806 "Total Averaged Information";
CM_ BO_ 2566775550 "Supply Pressure Demand";
CM_ SG_ 2566775550 AirSuspensionSupplyPressRq "Command signal to influence the pneumatic pressure in the circuit for the electronically controlled air suspension system.";
CM_ SG_ 2566775550 AuxEquipmentSupplyPressRq "Command signal to influence the pneumatic pressure in the auxiliary circuit.";
CM_ SG_ 2566775550 ServiceBrakeAirPressRqCircuit2 "Command signal to influence the pneumatic pressure in the service brake circuit or reservoir #2.";
CM_ SG_ 2566775550 ServiceBrakeAirPressRqCircuit1 "Command signal to influence the pneumatic pressure in the service brake circuit or reservoir #1.";
CM_ SG_ 2566775550 ParkingAnd_OrTrailerAirPressRq "Command signal to influence the pneumatic pressure in the circuit or reservoir for the parking brake and/or the trailer supply.";
CM_ SG_ 2566775550 PneumaticSupplyPressRq "Command signal to influence the pneumatic pressure in the main reservoir.";
CM_ BO_ 2566819838 "Supply Pressure 2";
CM_ SG_ 2566819838 EngExtlShutdownAirSupplyPress "Pressure of the air used to shut off the fuel supply to the engine.";
CM_ BO_ 2566839038 "Software Identification";
CM_ SG_ 2566839038 NmbrOfSftwrIdentificationFields "Number of software identification designators represented in the software identification parameter group.";
CM_ BO_ 2566841598 "Shutdown";
CM_ SG_ 2566841598 EngOverspeedTest "The engine overspeed test signal as measured by the reporting ECM.";
CM_ SG_ 2566841598 EngAirShutoffCmdStatus "State signal which indicates when the Air Shutoff driver output is being driven.";
CM_ SG_ 2566841598 EngAlarmOutputCmdStatus "State signal which indicates when the Alarm driver output is being driven.";
CM_ SG_ 2566841598 EngAlarmAcknowledge "The Engine Alarm Acknowledge Input signal as measured by the reporting ECM.";
CM_ SG_ 2566841598 EngProtectionSystemConfig "Parameter which indicates the configuration of the engine shutdown system.";
CM_ SG_ 2566841598 EngProtectionSystemTimerState "Status signal which indicates the current mode of the engine protection system timer system.";
CM_ SG_ 2566841598 EngPrtectionSystemTimerOverride "Status signal which indicates the status of the override feature of the engine protection system timer.";
CM_ SG_ 2566841598 EngPrtctnSystmApprchingShutdown "Status signal which indicates that engine shutdown is imminent.";
CM_ SG_ 2566841598 EngPrtctionSystemHasShutdownEng "Status signal which indicates whether or not the engine protection system has shutdown the engine.";
CM_ SG_ 2566841598 RefrigerantHighPressSwitch "Switch signal which indicates the position of the high pressure switch in the coolant circuit of an air conditioning system.";
CM_ SG_ 2566841598 RefrigerantLowPressSwitch "Switch signal which indicates the position of the low pressure switch in the coolant circuit of an air conditioning system.";
CM_ SG_ 2566841598 EngIdleShutdownTimerFunction "Parameter which indicates the configuration of the idle shutdown timer system.";
CM_ SG_ 2566841598 EngIdleShutdownTimerState "Status signal which indicates the current mode of operation of the idle shutdown timer system.";
CM_ SG_ 2566841598 EngIdleShutdownTimerOverride "Status signal which indicates the status of the override feature of the idle shutdown timer system.";
CM_ SG_ 2566841598 EngIdleShutdownDriverAlertMode "Status signal which indicates the status of the driver alert mode of the idle shutdown timer system.";
CM_ SG_ 2566841598 EngIdleShutdownHasShutdownEng "Status signal which identifies whether or not the engine has been shutdown by the idle shutdown timer system.";
CM_ BO_ 2566832382 "Service Information";
CM_ SG_ 2566832382 ServiceComponentIdentificationB "Identification of component needing service.";
CM_ SG_ 2566832382 ServiceComponentIdentificationA "Identification of component needing service.";
CM_ SG_ 2566832382 SrvceDelay_OperationalTimeBased "The time in vehicle operational time until the next vehicle service inspection is required.";
CM_ SG_ 2566832382 ServiceDelay_CalendarTimeBased "The time in weeks until the next vehicle service inspection is required.";
CM_ SG_ 2566832382 ServiceDistance "The distance which can be traveled by the vehicle before the next service inspection is required.";
CM_ SG_ 2566832382 ServiceComponentIdentification "Identification of component needing service.";
CM_ BO_ 2633928446 "Service 2";
CM_ SG_ 2633928446 TimeSinceLastService "The vehicle operation time since the last service was performed.";
CM_ SG_ 2633928446 ServiceComponentIdentification "Identification of component needing service.";
CM_ BO_ 2566804478 "Retarder Continuous Torque & Speed Limit";
CM_ SG_ 2566804478 MaxContinuousRetarderTorque "Applied limit for maximum continuous retarder torque.";
CM_ SG_ 2566804478 HghLmtThrshhldFrMnCntnsTrqFrmRtr "Maximum allowable value for minimum continuous retarder torque.";
CM_ SG_ 2566804478 LwLmtThrshhldFrMxTrqFrmRetarder "Minimum allowable value for maximum continuous retarder torque.";
CM_ BO_ 2566847486 "Retarder fluids";
CM_ SG_ 2566847486 HydRetarderOilTemp "Temperature of oil found in a hydraulic retarder.";
CM_ SG_ 2566847486 HydRetarderPress "Gage pressure of oil in hydraulic retarder system.";
CM_ BO_ 2631859966 "Reset";
CM_ SG_ 2631859966 EngBuildHoursReset "Command signal used to reset the engine rebuild hours.";
CM_ SG_ 2631859966 ServiceComponentIdentification "Identification of component needing service.";
CM_ SG_ 2631859966 TripGroup2Proprietary "Command signal used to reset proprietary parameters associated with a trip but not defined within this document.";
CM_ SG_ 2631859966 TripGroup1 "Command signal used to reset the PGNs and parameters as defined in Table SPN988_A.";
CM_ BO_ 2566840830 "Retarder Configuration";
CM_ SG_ 2566840830 ReferenceRetarderTorque "This parameter is the 100% reference value for all defined indicated retarder torque parameters.";
CM_ SG_ 2566840830 RetarderSpeedAtPoint4 "Retarder speed of point 4 of the engine retarder torque map.";
CM_ SG_ 2566840830 RetarderSpeedAtPoint3 "Retarder speed of point 3 of the engine retarder torque map.";
CM_ SG_ 2566840830 PercentTorqueAtMaxSpeedPoint2 "The torque limit that indicates the available retarder torque which can be provided by the retarder at its maximum speed.";
CM_ SG_ 2566840830 MaxRetarderSpeedPoint2 "Maximum speed of retarder (Please reference PGN 65249).";
CM_ SG_ 2566840830 PercentTorqueAtIdlePoint1 "The torque limit that indicates the available retarder torque which can be provided by the retarder at idle speed.";
CM_ SG_ 2566840830 RetarderCtrlMethod "This parameter identifies the number of steps used by the retarder.";
CM_ SG_ 2566840830 RetarderType "A vehicle retarder is a supplementary device to the wheel brakes for the driver to better control the vehicle.";
CM_ BO_ 2633930238 "Rebuild Information";
CM_ SG_ 2633930238 EngOperationTimeSinceRebuild "The time in engine operation since the last engine rebuild.";
CM_ BO_ 2566844670 "Power Takeoff Information";
CM_ SG_ 2566844670 OperatorPTOMemorySelectSwitch "Measured state of the operator PTO memory select switch.";
CM_ SG_ 2566844670 EngPTOAccelerateSwitch "Switch signal of the PTO control activator which indicates that the activator is in the position \"accelerate\".";
CM_ SG_ 2566844670 EngPTOResumeSwitch "Switch signal of the PTO control activator which indicates that the activator is in the position \"resume\".";
CM_ SG_ 2566844670 EngPTOCoast_DecelerateSwitch "Switch signal of the PTO control activator which indicates that the activator is in the position \"coast/decelerate\".";
CM_ SG_ 2566844670 EngPTOSetSwitch "Switch signal of the PTO control activator which indicates that the activator is in the position \"set\".";
CM_ SG_ 2566844670 EngRmtPTOVriableSpeedCtrlSwitch "Switch signal which indicates that the remote PTO toggle switch is in the enabled (ON) position.";
CM_ SG_ 2566844670 EngRmtPTOPrprgrmmdSpdCtrlSwitch "Switch signal which indicates that the remote PTO toggle switch is in the enabled (ON) position.";
CM_ SG_ 2566844670 PowerTakeoffSetSpeed "Rotational velocity selected by operator for device used to transmit engine power to auxiliary equipment.";
CM_ SG_ 2566844670 PowerTakeoffSpeed "Rotational velocity of device used to transmit engine power to auxiliary equipment.";
CM_ SG_ 2566844670 PowerTakeoffOilTemp "Temperature of lubricant in device used to transmit engine power to auxiliary equipment.";
CM_ SG_ 2566844670 RmtPTOPrprgrmmdSpeedCtrlSwitch2 "Switch signal which indicates that the remote PTO toggle switch #2 is in the enabled (ON) position.";
CM_ SG_ 2566844670 AuxInputIgnoreSwitch "Switch signal which overrides other switch input's ability to kick out of an engine's operating condition.";
CM_ BO_ 2566770174 "Operator Wiper and Washer Controls Message";
CM_ SG_ 2566770174 RearWasherFunction "State of operation selected by operator switch for the rear washer.";
CM_ SG_ 2566770174 FrontOperatorWasherSwitch "State of operation selected by operator switch for the washer in front of the operator position.";
CM_ SG_ 2566770174 FrontNonoperatorWasherSwitch "State of operation selected by operator switch for the front washer not in front of the operator position.";
CM_ SG_ 2566770174 RearWiperDelayCtrl "Time between cycles of the rear wiper (i.";
CM_ SG_ 2566770174 FrontNonoperatorWiperDelayCtrl "Time between cycles of the front non-operator side wiper (i.";
CM_ SG_ 2566770174 FrontOperatorWiperDelayCtrl "Time between cycles of the front operator side wiper (i.";
CM_ SG_ 2566770174 RearWiperSwitch "State of operation selected by operator switch for the rear wiper.";
CM_ SG_ 2566770174 FrontOperatorWiperSwitch "State of operation selected by operator switch for the Wiper in front of the operator position.";
CM_ SG_ 2566770174 FrontNonoperatorWiperSwitch "State of operation selected by operator switch for the front wiper not in front of the operator position.";
CM_ BO_ 2566769662 "Off-Highway Engine Control Selection";
CM_ SG_ 2566769662 EngAltRatingSelect "In some off-highway applications it may be desirable to have multiple engine ratings available for selection by the operator.";
CM_ SG_ 2566769662 EngAltLowIdleSwitch "Operator switch which selects between two low idle speeds, default and alternate.";
CM_ SG_ 2566769662 EngSynchronizationSwitch "This is the On/Off operation of the Multiple Unit Synchronization functionality.";
CM_ SG_ 2566769662 EngAuxGovernorSwitch "This is the On/Off operation of the Auxiliary Governor feature switch.";
CM_ BO_ 2566768638 "Off-Highway Engine Control Selection States";
CM_ SG_ 2566768638 EngAltRatingSelectState "In some off-highway applications it may be desirable to have multiple engine ratings available for selection by the operator.";
CM_ SG_ 2566768638 EngAltLowIdleSelectState "In many applications, it is desirable that an alternate low idle speed setting be made available via switch input.";
CM_ SG_ 2566768638 EngMultiUnitSyncState "This feature is widely used in Industry to operate multiple engines from a single command source.";
CM_ SG_ 2566768638 EngAuxGovernorState "This is the Engine Auxiliary Governor feature.";
CM_ BO_ 2365443326 "Operators External Light Controls Message";
CM_ SG_ 2365443326 OprtrsDesiredDelayedLampOffTime "A 16 bit parameter to be associated with Delayed Off position (1000 binary) of the Main Light Switch.";
CM_ SG_ 2365443326 OperatorsDesiredBacklight "A 8 bit parameter to indicate the level of back lighting the operator has selected for displays.";
CM_ SG_ 2365443326 HighLowBeamSwitch "A 2 bit parameter to indicate the selected position of the operator's high/low beam select switch.";
CM_ SG_ 2365443326 HazardLightSwitch "A 2 bit parameter to indicate the selected position of the operator's hazard light switch.";
CM_ SG_ 2365443326 TurnSignalSwitch "A 4 bit parameter to indicate the selected position of the operator's turn signal switch.";
CM_ SG_ 2365443326 MainLightSwitch "A 4 bit parameter to indicate the selected position of the operator's main light switch.";
CM_ SG_ 2365443326 WorkLightSwitch "A 4 bit parameter to indicate the selected position of the operator's work light switch.";
CM_ BO_ 2566776318 "Maximum Vehicle Speed Limit Status";
CM_ SG_ 2566776318 AppliedVehicleSpeedLimit "The vehicle speed limit in effect.";
CM_ SG_ 2566776318 MaxVehicleSpeedLimit1 "The lowest Maximum Vehicle Speed Limit.";
CM_ BO_ 2566802686 "Military Lighting Command";
CM_ SG_ 2566802686 OprtrsBlckOutIntensitySelection "Operators Selection of lamp intensity in black out mode.";
CM_ BO_ 2566774014 "Marine Control Information";
CM_ SG_ 2566774014 SlowVesselModeStatus "The status of the Slow Vessel Mode.";
CM_ SG_ 2566774014 TrollingModeStatus "The status of the Trolling Mode.";
CM_ SG_ 2566774014 EngThrttlSynchrnztionModeStatus "The status of the Throttle Synchronization Mode.";
CM_ BO_ 2566823166 "Main Bearing Temperature 3";
CM_ SG_ 2566823166 EngMainBearing11Temp "Temperature of the main bearing which supports the crankshaft of the engine.";
CM_ SG_ 2566823166 EngMainBearing10Temp "Temperature of the main bearing which supports the crankshaft of the engine.";
CM_ SG_ 2566823166 EngMainBearing9Temp "Temperature of the main bearing which supports the crankshaft of the engine.";
CM_ BO_ 2566823422 "Main Bearing Temperature 2";
CM_ SG_ 2566823422 EngMainBearing8Temp "Temperature of the main bearing which supports the crankshaft of the engine.";
CM_ SG_ 2566823422 EngMainBearing7Temp "Temperature of the main bearing which supports the crankshaft of the engine.";
CM_ SG_ 2566823422 EngMainBearing6Temp "Temperature of the main bearing which supports the crankshaft of the engine.";
CM_ SG_ 2566823422 EngMainBearing5Temp "Temperature of the main bearing which supports the crankshaft of the engine.";
CM_ BO_ 2566823678 "Main Bearing Temperature 1";
CM_ SG_ 2566823678 EngMainBearing4Temp "Temperature of the main bearing which supports the crankshaft of the engine.";
CM_ SG_ 2566823678 EngMainBearing3Temp "Temperature of the main bearing which supports the crankshaft of the engine.";
CM_ SG_ 2566823678 EngMainBearing2Temp "Temperature of the main bearing which supports the crankshaft of the engine.";
CM_ SG_ 2566823678 EngMainBearing1Temp "Temperature of the main bearing which supports the crankshaft of the engine.";
CM_ BO_ 2432595710 "Laser Leveling System Vertical Position Display Data";
CM_ SG_ 2432595710 DisplayDeadbands "Sets Display Deadbands mode.";
CM_ SG_ 2432595710 LEDPatternCtrl "Sets LED Pattern control mode on laser leveling systems.";
CM_ SG_ 2432595710 LEDDisplayDeadbandCtrl "This parameter informs the system what the selected Display deadband will be.";
CM_ SG_ 2432595710 LEDDisplayModeCtrl "This parameter informs the system what the selected Display mode will be.";
CM_ SG_ 2432595710 LEDDisplayData1 "Informs display devices how to display the current vertical position.";
CM_ BO_ 2365486590 "Laser Leveling System Vertical Deviation";
CM_ SG_ 2365486590 AbsLaserStrikePosition "Laser Strike location on the survey type laser receiver.";
CM_ SG_ 2365486590 LaserStrikeDataLatency "Time from laser strike to CAN message transmission.";
CM_ SG_ 2365486590 LaserReceiverType "Identifies which type of Laser Receiver transmitted the message.";
CM_ SG_ 2365486590 LaserStrikeVerticalDeviation "The calculated distance from the laser strike position to the current land leveling system reference point.";
CM_ BO_ 2365485566 "Laser Tracer Position";
CM_ SG_ 2365485566 LaserTracerInformation "Provides the status of the laser tracer to the operator.";
CM_ SG_ 2365485566 LEDDisplayData2 "Informs display devices how to display the current position of the laser tracer.";
CM_ SG_ 2365485566 LaserTracerHorizontalDeviation "The calculated percent deviation between the target distance and the center of the laser tracer.";
CM_ SG_ 2365485566 LaserTracerVerticalDistance "The elevation of the laser tracer sensor in a laser leveling system.";
CM_ SG_ 2365485566 LaserTracerTargetDeviation "The calculated distance for the laser target to the current laser tracer reference point.";
CM_ BO_ 2633939454 "Trip Fuel Information (Liquid)";
CM_ SG_ 2633939454 TripCruiseFuelUsed "Total fuel consumed while the engine is in the cruise hold state since the last trip reset.";
CM_ BO_ 2365486334 "Modify Leveling System Control Set Point";
CM_ SG_ 2365486334 BldHeightSetPointHighResolution "High resolution for the laser guided blade set point.";
CM_ SG_ 2365486334 ModifySetPoint "Used to control and coordinate the set point for the leveling system.";
CM_ BO_ 2364542462 "Land Leveling System Operational Information";
CM_ SG_ 2364542462 SdshftDsrdBldOffsetOperatorCtrl "This parameter indicates the side-shift blade control mode operator control state the user has set for the land leveling system.";
CM_ SG_ 2364542462 SdshftBldCtrlMdeOperatorControl "This parameter indicates the side-shift blade control mode operator control state the user has set for the land leveling system.";
CM_ SG_ 2364542462 RghtDsrdBladeOffsetOperatorCtrl "This parameter indicates the right blade offset operator control state the user has set for the land leveling system.";
CM_ SG_ 2364542462 RghtBldeCtrlModeOperatorControl "This parameter indicates the right blade control mode operator control state the user has set for the land leveling system.";
CM_ SG_ 2364542462 LftDsredBladeOffsetOperatorCtrl "This parameter indicates the left blade offset operator control state the user has set for the land leveling system.";
CM_ SG_ 2364542462 LftBladeCtrlModeOperatorControl "This parameter indicates the left blade control mode operator control state the user has set for the land leveling system.";
CM_ SG_ 2364542462 DesiredGradeOffsetSwitch "This parameter indicates the grade offset switch state the user has set for the land leveling system.";
CM_ SG_ 2364542462 BladeCtrlModeSwitch "This parameter indicates the blade control mode switch state the user has set for the land leveling system.";
CM_ BO_ 2365486078 "Laser Receiver Mast Position";
CM_ SG_ 2365486078 MastPos "Used to monitor the position of the sensor attached to the land leveling mast.";
CM_ BO_ 2633937918 "Fuel Information (Liquid)";
CM_ SG_ 2633937918 TripAverageFuelRate "Average fuel rate, equal to trip fuel divided by trip time while the engine speed is above zero, since the last trip reset.";
CM_ SG_ 2633937918 TotalEngPTOFuelUsed "Total fuel used while the PTO or remote PTO is in the hold state and engine speed is above zero, over the life of the engine.";
CM_ BO_ 2566845182 "Fuel Economy (Liquid)";
CM_ SG_ 2566845182 EngAverageFuelEconomy "Average of instantaneous fuel economy for that segment of vehicle operation of interest.";
CM_ SG_ 2566845182 EngInstantaneousFuelEconomy "Current fuel economy at current vehicle velocity.";
CM_ SG_ 2566845182 EngFuelRate "Amount of fuel consumed by engine per unit of time.";
CM_ SG_ 2566845182 EngThrottlePos "The position of the valve used to regulate the supply of a fluid, usually air or fuel/air mixture, to an engine.";
CM_ BO_ 2566842878 "Fuel Consumption (Liquid)";
CM_ SG_ 2566842878 EngTotalFuelUsed "Accumulated amount of fuel used during vehicle operation.";
CM_ SG_ 2566842878 EngTripFuel "Fuel consumed during all or part of a journey.";
CM_ BO_ 2633883646 "Front Wheel Drive Status";
CM_ SG_ 2633883646 FrontWheelDriveActuatorStatus "Feedback on the front wheel drive actuator.";
CM_ BO_ 2633880062 "FMS-standard Interface Identity/Capabilities";
CM_ SG_ 2633880062 FMSstandardSWversionSupported "Information that identifies which issue level of the FMS-standard document the software included in the FMS gateway supports.";
CM_ BO_ 2566806526 "Forward Lane Image";
CM_ SG_ 2566806526 LnDprtureIndicationEnableStatus "Indicates whether lane departure indication is active.";
CM_ SG_ 2566806526 LaneTrackingStatusLeftSide "Indicates whether the left side is tracking lane.";
CM_ SG_ 2566806526 LaneTrackingStatusRightSide "Indicates whether right side is tracking lane.";
CM_ BO_ 2431649790 "Forward Lane Image urgent msg";
CM_ SG_ 2431649790 LaneDepartureImminentLeftSide "Indicates departure imminent on left side of lane.";
CM_ SG_ 2431649790 LaneDepartureImminentRightSide "Indicates departure imminent on right side of lane.";
CM_ BO_ 2633929214 "Fuel Leakage";
CM_ SG_ 2633929214 EngFuelLeakage2 "Status signal which indicates fuel leakage in the fuel rail of the engine.";
CM_ SG_ 2633929214 EngFuelLeakage1 "Status signal which indicates fuel leakage in the fuel rail of the engine.";
CM_ BO_ 2566831614 "Fan Drive";
CM_ SG_ 2566831614 FanSpeed "The speed of the fan associated with engine coolant system.";
CM_ SG_ 2566831614 FanDriveState "This parameter is used to indicate the current state or mode of operation by the fan drive.";
CM_ SG_ 2566831614 EstPercentFanSpeed "Estimated fan speed as a ratio of the fan drive (current speed) to the fully engaged fan drive (maximum fan speed).";
CM_ BO_ 2566820094 "Engine Torque History";
CM_ SG_ 2566820094 EngTorqueLimit6AxleInput "Limit applied to the engine output torque based on the maximum allowable axle input torque.";
CM_ SG_ 2566820094 EngTorqueLimit5Switch "Limit applied to the engine output torque based on activation of an ECU switch input.";
CM_ SG_ 2566820094 EngTorqueLimitFeature "Torque limit rating described in the current record.";
CM_ SG_ 2566820094 TorqueLimitingFeatureStatus "Status of an ECU feature which limits the torque output of the engine.";
CM_ SG_ 2566820094 CalibRecordDurationTime "Duration in hours for which the engine operated in the conditions captured in the current record.";
CM_ SG_ 2566820094 CalibRecordStartYear "Calendar year timestamp when an ECU record was established.";
CM_ SG_ 2566820094 CalibRecordStartDay "Calendar day timestamp when an ECU record was established.";
CM_ SG_ 2566820094 CalibRecordStartMonth "Calendar month timestamp when an ECU record was established.";
CM_ SG_ 2566820094 EngPeakTorque2 "Maximum torque output of the current ECU calibration when the engine operates on torque curve 2.";
CM_ SG_ 2566820094 EngPeakTorque1 "Maximum torque output of the current ECU calibration when the engine operates on torque curve 1.";
CM_ SG_ 2566820094 EngPower "Advertised engine power capability.";
CM_ SG_ 2566820094 NumberOfEngTorqueHistoryRecords "Number of torque history records contained in the engine torque history PGN.";
CM_ BO_ 2364542206 "Electronic Transmission Controller #8";
CM_ SG_ 2364542206 TransTorqueConverterRatio "Ratio of the transmissions torque converter output torque to torque converter input torque at current speed.";
CM_ BO_ 2566802174 "Electronic Transmission Controller 7";
CM_ SG_ 2566802174 TransShiftInhibitIndicator "State signal indicating a transmission request for the Shift Inhibit Indicator to be active or inactive.";
CM_ SG_ 2566802174 TransEngCrankEnable "State signal from the transmission indicating if the transmission’s status is such that engine cranking is allowed (i.";
CM_ BO_ 2633935870 "Electronic Transmission Controller 6";
CM_ SG_ 2633935870 ClutchLifeRemaining "Signal which indicates the actual clutch life remaining in percent.";
CM_ SG_ 2633935870 LowestPossibleGear "The transmission calculates this gear continuously.";
CM_ SG_ 2633935870 HighestPossibleGear "The transmission calculates this gear continuously.";
CM_ SG_ 2633935870 RecommendedGear "The transmission calculates this gear continuously.";
CM_ BO_ 2633942014 "Electronic Transmission Controller 5";
CM_ SG_ 2633942014 TransForwardDirectionSwitch "Identifies the status of the switch that indicates forward direction.";
CM_ SG_ 2633942014 TransNeutralSwitch "Identifies the status of the switch that indicates neutral.";
CM_ SG_ 2633942014 TransReverseDirectionSwitch "Identifies the status of the switch that indicates reverse direction.";
CM_ SG_ 2633942014 TransLowRangeSenseSwitch "Identifies the status of the switch that represents low range.";
CM_ SG_ 2633942014 TransHighRangeSenseSwitch "Identifies the status of the switch that represents high range.";
CM_ BO_ 2633942526 "Electronic Transmission Controller 4";
CM_ SG_ 2633942526 TransSynchronizerBrakeValue "The current modulated value for the air supply to the synchronizer brake.";
CM_ SG_ 2633942526 TransSynchronizerClutchValue "The current modulated value for the air supply to the synchronizer clutch.";
CM_ BO_ 2633943038 "Electronic Transmission Controller 3";
CM_ SG_ 2633943038 TransInertiaBrakeActuator "Identifies the status of the actuator that controls the inertia brake.";
CM_ SG_ 2633943038 TransDefuelActuator "Identifies the status of the actuator that controls the engine defuel mechanism.";
CM_ SG_ 2633943038 TransLockupClutchActuator "Identifies the status of the actuator that controls the lockup clutch.";
CM_ SG_ 2633943038 TransClutchActuator "Identifies the status of the actuator that controls the clutch.";
CM_ SG_ 2633943038 TransSplitterIndirectActuator "Identifies the status of the splitter indirect actuator in the auxiliary unit.";
CM_ SG_ 2633943038 TransSplitterDirectActuator "Identifies the status of the splitter direct actuator in the auxiliary unit.";
CM_ SG_ 2633943038 TransRangeLowActuator "Identifies the status of the range low actuator in the auxiliary unit.";
CM_ SG_ 2633943038 TransRangeHighActuator "Identifies the status of the range high actuator in the auxiliary unit.";
CM_ SG_ 2633943038 TransShiftFingerGearActuator2 "Identifies the status of the actuator that moves the shift finger identified as gear actuator #2.";
CM_ SG_ 2633943038 TransShiftFingerRailActuator2 "Identifies the status of the actuator that moves the shift finger identified as rail actuator #2.";
CM_ SG_ 2633943038 TransShiftFingerGearActuator1 "Identifies the status of the actuator that moves the shift finger identified as gear actuator #1.";
CM_ SG_ 2633943038 TransShiftFingerRailActuator1 "Identifies the status of the actuator that moves the shift finger identified as rail actuator #1.";
CM_ SG_ 2633943038 TrnsShftFngrCenterRailIndicator "Identifies the status of the shift finger in the center rail position.";
CM_ SG_ 2633943038 TrnsShftFngrEngagementIndicator "Identifies the status of the shift finger in the engagement position.";
CM_ SG_ 2633943038 TrnsShiftFingerNeutralIndicator "Indicates the status of the shift finger in the neutral position.";
CM_ SG_ 2633943038 TransShiftFingerRailPos "The current position of the shift finger in the rail direction.";
CM_ SG_ 2633943038 TransShiftFingerGearPos "The current position of the shift finger in the gear direction.";
CM_ BO_ 2565867006 "Electronic Transmission Controller 2";
CM_ SG_ 2565867006 TransCurrentRange "Range currently being commanded by the transmission control system.";
CM_ SG_ 2565867006 TransRqedRange "Range selected by the operator.";
CM_ SG_ 2565867006 TransActualGearRatio "Actual ratio of input shaft speed to output shaft speed.";
CM_ BO_ 2364539646 "Electronic Transmission Controller 1";
CM_ SG_ 2364539646 SrcAddrssOfCtrllngDvcFrTrnsCtrl "The source address of the SAE J1939 device currently controlling the transmission.";
CM_ SG_ 2364539646 TransInputShaftSpeed "Rotational velocity of the primary shaft transferring power into the transmission.";
CM_ SG_ 2364539646 ProgressiveShiftDisable "Command signal used to indicate that progressive shifting by the engine should be disallowed.";
CM_ SG_ 2364539646 PercentClutchSlip "Parameter which represents the ratio of input shaft speed to current engine speed (in percent).";
CM_ SG_ 2364539646 TransOutputShaftSpeed "Calculated speed of the transmission output shaft.";
CM_ SG_ 2364539646 TransShiftInProcess "Indicates that the transmission is in process of shifting from the current gear to the selected gear.";
CM_ SG_ 2364539646 TorqueConverterLockupEngaged "State signal which indicates whether the torque converter lockup is engaged.";
CM_ BO_ 2566810110 "Engine Temperature 3";
CM_ SG_ 2566810110 EngChargeAirCoolerOutletTemp "Temperature of combustion air after it exits from the Charge Air Cooler but before any mixing of Recirculated Exhaust Gas.";
CM_ SG_ 2566810110 EngCoolantTempHiRes "Temperature of liquid found in engine cooling system.";
CM_ SG_ 2566810110 EngIntkVlvActationSystemOilTemp "The temperature of the oil in the hydraulic system that powers the intake valve actuation system.";
CM_ SG_ 2566810110 EngIntakeManifold1AirTemp "Temperature of pre-combustion air found in intake manifold of engine air supply system.";
CM_ BO_ 2566825214 "Engine Temperature 2";
CM_ SG_ 2566825214 EngECUTemp "Temperature of the engine electronic control unit.";
CM_ SG_ 2566825214 EngOilTemp2 "Temperature of the engine lubricant.";
CM_ BO_ 2566844158 "Engine Temperature 1";
CM_ SG_ 2566844158 EngIntercoolerThermostatOpening "The current position of the thermostat used to regulate the temperature of the engine intercooler.";
CM_ SG_ 2566844158 EngIntercoolerTemp "Temperature of liquid found in the intercooler located after the turbocharger.";
CM_ SG_ 2566844158 EngTurboOilTemp "Temperature of the turbocharger lubricant.";
CM_ SG_ 2566844158 EngOilTemp1 "Temperature of the engine lubricant.";
CM_ SG_ 2566844158 EngFuelTemp "Temperature of fuel entering injectors.";
CM_ SG_ 2566844158 EngCoolantTemp "Temperature of liquid found in engine cooling system.";
CM_ BO_ 2566785022 "Exhaust Temperature";
CM_ SG_ 2566785022 EngExhstExhstGsTempLeftManifold "Temperature of combustion byproducts within the left engine exhaust manifold.";
CM_ SG_ 2566785022 EngExhstExhstGsTmpRightManifold "Temperature of combustion byproducts within the right engine exhaust manifold.";
CM_ BO_ 2565868542 "Electronic Steering Control";
CM_ SG_ 2565868542 SterableLiftAxleLoweringInhibit "A signal which indicates if lowering of lifted axle is allowed or inhibited.";
CM_ SG_ 2565868542 AxleLocation "To identify to which of several similar devices (such as tires or fuel tanks) the information applies.";
CM_ SG_ 2565868542 TypeOfSteerTrans "Type of Steering Transmission (Ref.";
CM_ SG_ 2565868542 TypeOfSteerForces "Type of Steering Forces (Ref.";
CM_ SG_ 2565868542 SteerType "Indicates the different types of steering systems (ref.";
CM_ SG_ 2565868542 ActualInnerWheelSteerAngle "Signal which indicates the actual inner wheel steering angle.";
CM_ BO_ 2633941758 "Electronic Retarder Controller 2";
CM_ SG_ 2633941758 TransOutputRetarder "Identifies the status of the transmission output retarder.";
CM_ BO_ 2565865726 "Electronic Retarder Controller 1";
CM_ SG_ 2565865726 ActlMxAvlblRtarderPercentTorque "This is the maximum amount of torque that the retarder can immediately deliver.";
CM_ SG_ 2565865726 SrcAddrssOfCtrllngDvcFrRtrdrCtrl "The source address of the SAE J1939 device currently controlling the retarder.";
CM_ SG_ 2565865726 EngCoolantLoadIncrease "Status of an event, external to the engine, that may increase the nominal temperature of the engine coolant liquid.";
CM_ SG_ 2565865726 IntendedRetarderPercentTorque "Braking torque of retarder that the retarder is currently trying to achieve.";
CM_ SG_ 2565865726 ActualRetarderPercentTorque "Actual braking torque of the retarder as a percent of retarder configuration reference torque SPN 556.";
CM_ SG_ 2565865726 RetarderEnableShiftAssistSwitch "Switch signal which indicates whether the operator wishes the retarder to be enabled for transmission shift assist.";
CM_ SG_ 2565865726 RetarderEnableBrakeAssistSwitch "Switch signal which indicates whether the operator wishes the retarder to be enabled for vehicle braking assist.";
CM_ SG_ 2565865726 RetarderTorqueMode "State signal which indicates which retarder torque mode is currently generating, limiting, or controlling the torque.";
CM_ BO_ 2633932798 "Exhaust Port Temperature 5";
CM_ SG_ 2633932798 EngExhaustGasPort20Temp "Temperature at the cylinder exhaust port of the engine.";
CM_ SG_ 2633932798 EngExhaustGasPort19Temp "Temperature at the cylinder exhaust port of the engine.";
CM_ SG_ 2633932798 EngExhaustGasPort18Temp "Temperature at the cylinder exhaust port of the engine.";
CM_ SG_ 2633932798 EngExhaustGasPort17Temp "Temperature at the cylinder exhaust port of the engine.";
CM_ BO_ 2566824190 "Exhaust Port Temperature 4";
CM_ SG_ 2566824190 EngExhaustGasPort16Temp "Temperature at the cylinder exhaust port of the engine.";
CM_ SG_ 2566824190 EngExhaustGasPort15Temp "Temperature at the cylinder exhaust port of the engine.";
CM_ SG_ 2566824190 EngExhaustGasPort14Temp "Temperature at the cylinder exhaust port of the engine.";
CM_ SG_ 2566824190 EngExhaustGasPort13Temp "Temperature at the cylinder exhaust port of the engine.";
CM_ BO_ 2633933310 "Exhaust Port Temperature 3";
CM_ SG_ 2633933310 EngExhaustGasPort12Temp "Temperature at the cylinder exhaust port of the engine.";
CM_ SG_ 2633933310 EngExhaustGasPort11Temp "Temperature at the cylinder exhaust port of the engine.";
CM_ SG_ 2633933310 EngExhaustGasPort10Temp "Temperature at the cylinder exhaust port of the engine.";
CM_ SG_ 2633933310 EngExhaustGasPort9Temp "Temperature at the cylinder exhaust port of the engine.";
CM_ BO_ 2633933566 "Exhaust Port Temperature 2";
CM_ SG_ 2633933566 EngExhaustGasPort8Temp "Temperature at the cylinder exhaust port of the engine.";
CM_ SG_ 2633933566 EngExhaustGasPort7Temp "Temperature at the cylinder exhaust port of the engine.";
CM_ SG_ 2633933566 EngExhaustGasPort6Temp "Temperature at the cylinder exhaust port of the engine.";
CM_ SG_ 2633933566 EngExhaustGasPort5Temp "Temperature at the cylinder exhaust port of the engine.";
CM_ BO_ 2633933822 "Exhaust Port Temperature 1";
CM_ SG_ 2633933822 EngExhaustGasPort4Temp "Temperature at the cylinder exhaust port of the engine.";
CM_ SG_ 2633933822 EngExhaustGasPort3Temp "Temperature at the cylinder exhaust port of the engine.";
CM_ SG_ 2633933822 EngExhaustGasPort2Temp "Temperature at the cylinder exhaust port of the engine.";
CM_ SG_ 2633933822 EngExhaustGasPort1Temp "Temperature at the cylinder exhaust port of the engine.";
CM_ BO_ 2566776062 "Equipment Performance Data";
CM_ SG_ 2566776062 PayloadPercentage "The current payload of the equipment, reported as a percentage of the equipment's rated payload limit.";
CM_ BO_ 2566771454 "ECU Performance";
CM_ SG_ 2566771454 DataMemoryUsage "The used storage capacity of the data buffer memory internal to an ECU, such as a data logger.";
CM_ SG_ 2566771454 KeepAliveBatteryConsumption "The capacity consumed from the direct battery connection since the key was last turned off.";
CM_ BO_ 2566775806 "Equipment Operation and Control";
CM_ BO_ 2633935358 "Exhaust Oxygen 1";
CM_ SG_ 2633935358 EngExhstGsOxygnSnsrClsdLpOprton "Indicates whether the engine is using the Exhaust Gas Oxygen sensor to control the air/fuel ratio.";
CM_ BO_ 2365447166 "Extended Joystick Message 3";
CM_ SG_ 2365447166 Jystck3GripXAxisDetentPosStatus "Reports when the current joystick grip position is in the detent position for that axis of travel.";
CM_ SG_ 2365447166 Jystck3GripYAxisDetentPosStatus "Reports when the current joystick grip position is in the detent position for that axis of travel.";
CM_ SG_ 2365447166 Jystck3ThetaAxisDetentPosStatus "Reports when the current joystick position is in the detent position for that axis of travel.";
CM_ SG_ 2365447166 Joystick3ThetaAxisPos "The position of the joystick in the relative motion of travel from the neutral position.";
CM_ SG_ 2365447166 Jystck3ThtaAxisNeutralPosStatus "Reports when the current joystick position is in the neutral position for that axis of travel.";
CM_ SG_ 2365447166 Joystick3GripYAxisPos "The position of the joystick grip in the relative motion of travel from the neutral position.";
CM_ SG_ 2365447166 Jystck3GrpYAxisNeutralPosStatus "Reports when the current joystick grip position is in the neutral position for that axis of travel.";
CM_ SG_ 2365447166 Joystick3GripXAxisPos "The position of the joystick grip in the relative motion of travel from the neutral position.";
CM_ SG_ 2365447166 Jystck3GrpXAxisNeutralPosStatus "Reports when the current joystick grip position is in the neutral position for that axis of travel.";
CM_ BO_ 2365446654 "Extended Joystick Message 2";
CM_ SG_ 2365446654 Jystck2GripXAxisDetentPosStatus "Reports when the current joystick grip position is in the detent position for that axis of travel.";
CM_ SG_ 2365446654 Jystck2GripYAxisDetentPosStatus "Reports when the current joystick grip position is in the detent position for that axis of travel.";
CM_ SG_ 2365446654 Jystck2ThetaAxisDetentPosStatus "Reports when the current joystick position is in the detent position for that axis of travel.";
CM_ SG_ 2365446654 Joystick2ThetaAxisPos "The position of the joystick in the relative motion of travel from the neutral position.";
CM_ SG_ 2365446654 Jystck2ThtaAxisNeutralPosStatus "Reports when the current joystick position is in the neutral position for that axis of travel.";
CM_ SG_ 2365446654 Joystick2GripYAxisPos "The position of the joystick grip in the relative motion of travel from the neutral position.";
CM_ SG_ 2365446654 Jystck2GrpYAxisNeutralPosStatus "Reports when the current joystick grip position is in the neutral position for that axis of travel.";
CM_ SG_ 2365446654 Joystick2GripXAxisPos "The position of the joystick grip in the relative motion of travel from the neutral position.";
CM_ SG_ 2365446654 Jystck2GrpXAxisNeutralPosStatus "Reports when the current joystick grip position is in the neutral position for that axis of travel.";
CM_ BO_ 2365446142 "Extended Joystick Message 1";
CM_ SG_ 2365446142 Jystck1GripXAxisDetentPosStatus "Reports when the current joystick grip position is in the detent position for that axis of travel.";
CM_ SG_ 2365446142 Jystck1GripYAxisDetentPosStatus "Reports when the current joystick grip position is in the detent position for that axis of travel.";
CM_ SG_ 2365446142 Jystck1ThetaAxisDetentPosStatus "Reports when the current joystick position is in the detent position for that axis of travel.";
CM_ SG_ 2365446142 Joystick1ThetaAxisPos "The position of the joystick in the relative motion of travel from the neutral position.";
CM_ SG_ 2365446142 Jystck1ThtaAxisNeutralPosStatus "Reports when the current joystick position is in the neutral position for that axis of travel.";
CM_ SG_ 2365446142 Joystick1GripYAxisPos "The position of the joystick grip in the relative motion of travel from the neutral position.";
CM_ SG_ 2365446142 Jystck1GrpYAxisNeutralPosStatus "Reports when the current joystick grip position is in the neutral position for that axis of travel.";
CM_ SG_ 2365446142 Joystick1GripXAxisPos "The position of the joystick grip in the relative motion of travel from the neutral position.";
CM_ SG_ 2365446142 Jystck1GrpXAxisNeutralPosStatus "Reports when the current joystick grip position is in the neutral position for that axis of travel.";
CM_ BO_ 2633929470 "Engine Information";
CM_ SG_ 2633929470 EngFuelRackPos "Measured position of the engine fuel rack.";
CM_ SG_ 2633929470 InstantaneousEstBrakePower "Estimate of the power developed by the engine.";
CM_ SG_ 2633929470 EngMassFlow "Mass flow of natural gas to the engine.";
CM_ SG_ 2633929470 EngExhaustGasPress "Gage pressure of the exhaust gasses as measured at the turbine inlet of the turbocharger.";
CM_ SG_ 2633929470 EngPrefilterOilPress "Gage pressure of the engine oil before the oil reaches the oil filter.";
CM_ BO_ 2633937406 "ECU History";
CM_ SG_ 2633937406 TotalECURunTime "Total time accumulated over the life of the ECU, from ignition switch ON to ignition switch OFF.";
CM_ SG_ 2633937406 TotalECUDistance "Total distance accumulated over the life of the ECU.";
CM_ BO_ 2364541694 "Engine Gas Flow Rate";
CM_ SG_ 2364541694 EngInletAirMassFlowRate "Mass flow rate of fresh air entering the engine air intake, before any EGR mixer, if used.";
CM_ SG_ 2364541694 EngExhstGsRcrcltionMassFlowRate "Flow rate of gas through the EGR system.";
CM_ BO_ 2566810366 "Engine Fuel/lube systems";
CM_ SG_ 2566810366 EngFuelFilterSucSideDiffPress "Differential pressure measured across the fuel filter located between the fuel tank and the supply pump.";
CM_ SG_ 2566810366 EngFuelSupplyPumpInletPress "Absolute pressure of fuel at the fuel supply pump inlet.";
CM_ SG_ 2566810366 EngOilLevelRemoteReservoir "Ratio of current volume of engine oil in a remote reservoir to the maximum required volume.";
CM_ BO_ 2566767102 "Engine Fluid Level/Pressure 3";
CM_ SG_ 2566767102 EngExhstGsRcrculationInletPress "EGR inlet gage pressure is measured after the EGR cooler and before the EGR valve.";
CM_ BO_ 2566839294 "Engine Fluid Level/Pressure 2";
CM_ SG_ 2566839294 EngInjectorMeteringRail2Press "The gage pressure of fuel in the metering rail #2 as delivered from the supply pump to the injector metering inlet.";
CM_ SG_ 2566839294 EngInjectorTimingRail1Press "The gage pressure of fuel in the timing rail delivered from the supply pump to the injector timing inlet.";
CM_ SG_ 2566839294 EngInjectorMeteringRail1Press "The gage pressure of fuel in the primary, or first, metering rail as delivered from the supply pump to the injector metering inlet.";
CM_ SG_ 2566839294 EngInjectionCtrlPress "The gage pressure of the engine oil in the hydraulic accumulator that powers an intensifier used for fuel injection.";
CM_ BO_ 2566844414 "Engine Fluid Level/Pressure 1";
CM_ SG_ 2566844414 EngCoolantLevel "Ratio of volume of liquid found in engine cooling system to total cooling system volume.";
CM_ SG_ 2566844414 EngCoolantPress "Gage pressure of liquid found in engine cooling system.";
CM_ SG_ 2566844414 EngCrankcasePress "Gage pressure inside engine crankcase.";
CM_ SG_ 2566844414 EngOilPress "Gage pressure of oil in engine lubrication system as provided by oil pump.";
CM_ SG_ 2566844414 EngOilLevel "Ratio of current volume of engine sump oil to maximum required volume.";
CM_ SG_ 2566844414 EngExCrankcaseBlowbyPress "Differential crankcase blow-by pressure as measured through a tube with a venturi.";
CM_ SG_ 2566844414 EngFuelDeliveryPress "Gage pressure of fuel in system as delivered from supply pump to the injection pump.";
CM_ BO_ 2633929726 "Engine Electrical System/Module Information";
CM_ SG_ 2633929726 TurningGearEngaged "Status signal which indicates that the turning gear is engaged.";
CM_ SG_ 2633929726 SafetyWireStatus "Status signal which indicates that the safety wire has been activated.";
CM_ SG_ 2633929726 ElectricalLoad "Electrical power delivered by the engine to the electrical system connected to the generator.";
CM_ BO_ 2566772222 "Electronic Engine Controller 5";
CM_ SG_ 2566772222 EngVrblGometryTurbo1ActuatorPos "Sensor that measures the position of the variable geometry turbocharger actuator.";
CM_ SG_ 2566772222 EngVrblGmtryTrbArCtrlShtffValve "Isolates vehicle brake air from the Variable Geometry Turbocharger (VGT) system when engine is not running.";
CM_ SG_ 2566772222 EngExhstGsRcirculationValveCtrl "Desired percentage of maximum Exhaust Gas Recirculation (EGR) valve opening.";
CM_ SG_ 2566772222 EngTrb1ClcltedTurbineOutletTemp "Calculated value of turbocharger compressor outlet air temperature.";
CM_ BO_ 2633940734 "Electronic Engine Controller 4";
CM_ SG_ 2633940734 EngRatedSpeed "The maximum governed rotational velocity of the engine crankshaft under full load conditions.";
CM_ SG_ 2633940734 EngRatedPower "Net brake power that the engine will deliver continuously, specified for a given application at a rated speed.";
CM_ BO_ 2566840318 "Electronic Engine Controller 3";
CM_ SG_ 2566840318 ExhaustGasMass "Measured/calculated exhaust gas mass upstream of the after-treatment system.";
CM_ SG_ 2566840318 EngsDesiredOperatingSpeed "An indication by the engine of the optimal operating speed of the engine for the current existing conditions.";
BA_DEF_ BO_  "FrameFormat" ENUM  "StandardCAN","ExtendedCAN","reserved","J1939PG";
BA_DEF_ SG_  "SigType" STRING ;
BA_DEF_ SG_  "SPN" INT 0 524287;
BA_DEF_ BO_  "GenMsgRequestable" INT 0 1;
BA_DEF_ BO_  "GenMsgSendType" ENUM  "cyclic","spontan","cyclicIfActive","spontanWithDelay","cyclicAndSpontan","cyclicAndSpontanWithDelay","spontanWithRepetition","cyclicIfActiveAndSpontanWD","noMsgSendType";
BA_DEF_ BO_  "VFrameFormat" ENUM  "StandardCAN","ExtendedCAN","reserved","J1939PG";
BA_DEF_ BO_  "GenMsgCycleTime" INT 0 3600000;
BA_DEF_DEF_  "FrameFormat" "J1939PG";
BA_DEF_DEF_  "SigType" "";
BA_DEF_DEF_  "SPN" 0;
BA_DEF_DEF_  "GenMsgRequestable" 1;
BA_DEF_DEF_  "GenMsgSendType" "noMsgSendType";
BA_DEF_DEF_  "VFrameFormat" "J1939PG";
BA_DEF_DEF_  "GenMsgCycleTime" 0;
BA_ "GenMsgSendType" BO_ 2566839806 0;
BA_ "GenMsgCycleTime" BO_ 2566839806 1000;
BA_ "GenMsgSendType" BO_ 2566775550 2;
BA_ "GenMsgCycleTime" BO_ 2566775550 1000;
BA_ "GenMsgSendType" BO_ 2566819838 0;
BA_ "GenMsgCycleTime" BO_ 2566819838 1000;
BA_ "GenMsgSendType" BO_ 2566841598 0;
BA_ "GenMsgCycleTime" BO_ 2566841598 1000;
BA_ "GenMsgSendType" BO_ 2566804478 0;
BA_ "GenMsgCycleTime" BO_ 2566804478 5000;
BA_ "GenMsgSendType" BO_ 2566847486 0;
BA_ "GenMsgCycleTime" BO_ 2566847486 1000;
BA_ "GenMsgSendType" BO_ 2566844670 0;
BA_ "GenMsgCycleTime" BO_ 2566844670 100;
BA_ "GenMsgSendType" BO_ 2566770174 0;
BA_ "GenMsgCycleTime" BO_ 2566770174 200;
BA_ "GenMsgSendType" BO_ 2566769662 0;
BA_ "GenMsgCycleTime" BO_ 2566769662 500;
BA_ "GenMsgSendType" BO_ 2566768638 0;
BA_ "GenMsgCycleTime" BO_ 2566768638 500;
BA_ "GenMsgSendType" BO_ 2566776318 0;
BA_ "GenMsgCycleTime" BO_ 2566776318 1000;
BA_ "GenMsgSendType" BO_ 2566802686 0;
BA_ "GenMsgCycleTime" BO_ 2566802686 500;
BA_ "GenMsgSendType" BO_ 2566774014 0;
BA_ "GenMsgCycleTime" BO_ 2566774014 1000;
BA_ "GenMsgSendType" BO_ 2566823166 0;
BA_ "GenMsgCycleTime" BO_ 2566823166 1000;
BA_ "GenMsgSendType" BO_ 2566823422 0;
BA_ "GenMsgCycleTime" BO_ 2566823422 1000;
BA_ "GenMsgSendType" BO_ 2566823678 0;
BA_ "GenMsgCycleTime" BO_ 2566823678 1000;
BA_ "GenMsgSendType" BO_ 2432595710 0;
BA_ "GenMsgCycleTime" BO_ 2432595710 100;
BA_ "GenMsgSendType" BO_ 2365486590 0;
BA_ "GenMsgCycleTime" BO_ 2365486590 50;
BA_ "GenMsgSendType" BO_ 2365485566 0;
BA_ "GenMsgCycleTime" BO_ 2365485566 50;
BA_ "GenMsgSendType" BO_ 2365486334 0;
BA_ "GenMsgCycleTime" BO_ 2365486334 50;
BA_ "GenMsgSendType" BO_ 2364542462 0;
BA_ "GenMsgCycleTime" BO_ 2364542462 100;
BA_ "GenMsgSendType" BO_ 2365486078 0;
BA_ "GenMsgCycleTime" BO_ 2365486078 50;
BA_ "GenMsgSendType" BO_ 2566845182 0;
BA_ "GenMsgCycleTime" BO_ 2566845182 100;
BA_ "GenMsgSendType" BO_ 2633883646 0;
BA_ "GenMsgCycleTime" BO_ 2633883646 500;
BA_ "GenMsgSendType" BO_ 2633880062 0;
BA_ "GenMsgCycleTime" BO_ 2633880062 10000;
BA_ "GenMsgSendType" BO_ 2566806526 0;
BA_ "GenMsgCycleTime" BO_ 2566806526 100;
BA_ "GenMsgSendType" BO_ 2431649790 2;
BA_ "GenMsgCycleTime" BO_ 2431649790 50;
BA_ "GenMsgSendType" BO_ 2633929214 0;
BA_ "GenMsgCycleTime" BO_ 2633929214 1000;
BA_ "GenMsgSendType" BO_ 2566831614 0;
BA_ "GenMsgCycleTime" BO_ 2566831614 1000;
BA_ "GenMsgSendType" BO_ 2364542206 0;
BA_ "GenMsgCycleTime" BO_ 2364542206 20;
BA_ "GenMsgSendType" BO_ 2566802174 0;
BA_ "GenMsgCycleTime" BO_ 2566802174 100;
BA_ "GenMsgSendType" BO_ 2565867006 0;
BA_ "GenMsgCycleTime" BO_ 2565867006 100;
BA_ "GenMsgSendType" BO_ 2364539646 0;
BA_ "GenMsgCycleTime" BO_ 2364539646 10;
BA_ "GenMsgSendType" BO_ 2566810110 0;
BA_ "GenMsgCycleTime" BO_ 2566810110 1000;
BA_ "GenMsgSendType" BO_ 2566825214 0;
BA_ "GenMsgCycleTime" BO_ 2566825214 1000;
BA_ "GenMsgSendType" BO_ 2566844158 0;
BA_ "GenMsgCycleTime" BO_ 2566844158 1000;
BA_ "GenMsgSendType" BO_ 2566785022 0;
BA_ "GenMsgCycleTime" BO_ 2566785022 500;
BA_ "GenMsgSendType" BO_ 2565868542 0;
BA_ "GenMsgCycleTime" BO_ 2565868542 20;
BA_ "GenMsgSendType" BO_ 2633941758 2;
BA_ "GenMsgCycleTime" BO_ 2633941758 1000;
BA_ "GenMsgSendType" BO_ 2565865726 0;
BA_ "GenMsgCycleTime" BO_ 2565865726 100;
BA_ "GenMsgSendType" BO_ 2633932798 0;
BA_ "GenMsgCycleTime" BO_ 2633932798 1000;
BA_ "GenMsgSendType" BO_ 2566824190 0;
BA_ "GenMsgCycleTime" BO_ 2566824190 1000;
BA_ "GenMsgSendType" BO_ 2633933310 0;
BA_ "GenMsgCycleTime" BO_ 2633933310 1000;
BA_ "GenMsgSendType" BO_ 2633933566 0;
BA_ "GenMsgCycleTime" BO_ 2633933566 1000;
BA_ "GenMsgSendType" BO_ 2633933822 0;
BA_ "GenMsgCycleTime" BO_ 2633933822 1000;
BA_ "GenMsgSendType" BO_ 2566776062 0;
BA_ "GenMsgCycleTime" BO_ 2566776062 500;
BA_ "GenMsgSendType" BO_ 2566775806 0;
BA_ "GenMsgCycleTime" BO_ 2566775806 250;
BA_ "GenMsgSendType" BO_ 2365447166 0;
BA_ "GenMsgCycleTime" BO_ 2365447166 100;
BA_ "GenMsgSendType" BO_ 2365446654 0;
BA_ "GenMsgCycleTime" BO_ 2365446654 100;
BA_ "GenMsgSendType" BO_ 2365446142 0;
BA_ "GenMsgCycleTime" BO_ 2365446142 100;
BA_ "GenMsgSendType" BO_ 2633929470 0;
BA_ "GenMsgCycleTime" BO_ 2633929470 100;
BA_ "GenMsgSendType" BO_ 2364541694 0;
BA_ "GenMsgCycleTime" BO_ 2364541694 50;
BA_ "GenMsgSendType" BO_ 2566810366 0;
BA_ "GenMsgCycleTime" BO_ 2566810366 500;
BA_ "GenMsgSendType" BO_ 2566767102 0;
BA_ "GenMsgCycleTime" BO_ 2566767102 500;
BA_ "GenMsgSendType" BO_ 2566839294 0;
BA_ "GenMsgCycleTime" BO_ 2566839294 500;
BA_ "GenMsgSendType" BO_ 2566844414 0;
BA_ "GenMsgCycleTime" BO_ 2566844414 500;
BA_ "GenMsgSendType" BO_ 2633929726 0;
BA_ "GenMsgCycleTime" BO_ 2633929726 100;
BA_ "GenMsgSendType" BO_ 2566840318 0;
BA_ "GenMsgCycleTime" BO_ 2566840318 250;
BA_ "SigType" SG_ 2348941054 TrnsShftSlctorDisplayModeSwitch "DISCRETE";
BA_ "SPN" SG_ 2348941054 TrnsShftSlctorDisplayModeSwitch 2985;
BA_ "SigType" SG_ 2348941054 TransMode4 "DISCRETE";
BA_ "SPN" SG_ 2348941054 TransMode4 1855;
BA_ "SigType" SG_ 2348941054 TransMode3 "DISCRETE";
BA_ "SPN" SG_ 2348941054 TransMode3 1854;
BA_ "SigType" SG_ 2348941054 TransMode2 "DISCRETE";
BA_ "SPN" SG_ 2348941054 TransMode2 1853;
BA_ "SigType" SG_ 2348941054 TransMode1 "DISCRETE";
BA_ "SPN" SG_ 2348941054 TransMode1 1852;
BA_ "SigType" SG_ 2348941054 DisengageDiffLockRqCentralRear "DISCRETE";
BA_ "SPN" SG_ 2348941054 DisengageDiffLockRqCentralRear 691;
BA_ "SigType" SG_ 2348941054 DisengageDiffLockRqCentralFront "DISCRETE";
BA_ "SPN" SG_ 2348941054 DisengageDiffLockRqCentralFront 690;
BA_ "SigType" SG_ 2348941054 DisengageDiffLockRqCentral "DISCRETE";
BA_ "SPN" SG_ 2348941054 DisengageDiffLockRqCentral 689;
BA_ "SigType" SG_ 2348941054 DisengageDiffLockRqRearAxle2 "DISCRETE";
BA_ "SPN" SG_ 2348941054 DisengageDiffLockRqRearAxle2 688;
BA_ "SigType" SG_ 2348941054 DisengageDiffLockRqRearAxle1 "DISCRETE";
BA_ "SPN" SG_ 2348941054 DisengageDiffLockRqRearAxle1 687;
BA_ "SigType" SG_ 2348941054 DisengageDiffLockRqFrontAxle2 "DISCRETE";
BA_ "SPN" SG_ 2348941054 DisengageDiffLockRqFrontAxle2 686;
BA_ "SigType" SG_ 2348941054 DisengageDiffLockRqFrontAxle1 "DISCRETE";
BA_ "SPN" SG_ 2348941054 DisengageDiffLockRqFrontAxle1 685;
BA_ "SigType" SG_ 2348941054 TransRqedGear "RANGE";
BA_ "SPN" SG_ 2348941054 TransRqedGear 525;
BA_ "SigType" SG_ 2348941054 RqedPercentClutchSlip "RANGE";
BA_ "SPN" SG_ 2348941054 RqedPercentClutchSlip 684;
BA_ "SigType" SG_ 2348941054 DisengageDrivelineRq "DISCRETE";
BA_ "SPN" SG_ 2348941054 DisengageDrivelineRq 683;
BA_ "SigType" SG_ 2348941054 TorqueConverterLockupDisableRq "DISCRETE";
BA_ "SPN" SG_ 2348941054 TorqueConverterLockupDisableRq 682;
BA_ "SigType" SG_ 2348941054 TransGearShiftInhibitRq "DISCRETE";
BA_ "SPN" SG_ 2348941054 TransGearShiftInhibitRq 681;
BA_ "SigType" SG_ 2566839806 EngTurboOilLevelSwitch "DISCRETE";
BA_ "SPN" SG_ 2566839806 EngTurboOilLevelSwitch 1665;
BA_ "SigType" SG_ 2566839806 EngTurbo1Speed "RANGE";
BA_ "SPN" SG_ 2566839806 EngTurbo1Speed 103;
BA_ "SigType" SG_ 2566839806 EngTurboLubeOilPress1 "RANGE";
BA_ "SPN" SG_ 2566839806 EngTurboLubeOilPress1 104;
BA_ "SigType" SG_ 2633911806 EngTotalAverageFuelEconomy "RANGE";
BA_ "SPN" SG_ 2633911806 EngTotalAverageFuelEconomy 1835;
BA_ "SigType" SG_ 2633911806 EngTotalAverageFuelRate "RANGE";
BA_ "SPN" SG_ 2633911806 EngTotalAverageFuelRate 1834;
BA_ "SigType" SG_ 2566775550 AirSuspensionSupplyPressRq "RANGE";
BA_ "SPN" SG_ 2566775550 AirSuspensionSupplyPressRq 2608;
BA_ "SigType" SG_ 2566775550 AuxEquipmentSupplyPressRq "RANGE";
BA_ "SPN" SG_ 2566775550 AuxEquipmentSupplyPressRq 2607;
BA_ "SigType" SG_ 2566775550 ServiceBrakeAirPressRqCircuit2 "RANGE";
BA_ "SPN" SG_ 2566775550 ServiceBrakeAirPressRqCircuit2 2606;
BA_ "SigType" SG_ 2566775550 ServiceBrakeAirPressRqCircuit1 "RANGE";
BA_ "SPN" SG_ 2566775550 ServiceBrakeAirPressRqCircuit1 2605;
BA_ "SigType" SG_ 2566775550 ParkingAnd_OrTrailerAirPressRq "RANGE";
BA_ "SPN" SG_ 2566775550 ParkingAnd_OrTrailerAirPressRq 2604;
BA_ "SigType" SG_ 2566775550 PneumaticSupplyPressRq "RANGE";
BA_ "SPN" SG_ 2566775550 PneumaticSupplyPressRq 2603;
BA_ "SigType" SG_ 2566819838 EngExtlShutdownAirSupplyPress "RANGE";
BA_ "SPN" SG_ 2566819838 EngExtlShutdownAirSupplyPress 1320;
BA_ "SigType" SG_ 2566839038 NmbrOfSftwrIdentificationFields "RANGE";
BA_ "SPN" SG_ 2566839038 NmbrOfSftwrIdentificationFields 965;
BA_ "SigType" SG_ 2566841598 EngOverspeedTest "DISCRETE";
BA_ "SPN" SG_ 2566841598 EngOverspeedTest 2812;
BA_ "SigType" SG_ 2566841598 EngAirShutoffCmdStatus "DISCRETE";
BA_ "SPN" SG_ 2566841598 EngAirShutoffCmdStatus 2813;
BA_ "SigType" SG_ 2566841598 EngAlarmOutputCmdStatus "DISCRETE";
BA_ "SPN" SG_ 2566841598 EngAlarmOutputCmdStatus 2814;
BA_ "SigType" SG_ 2566841598 EngAlarmAcknowledge "DISCRETE";
BA_ "SPN" SG_ 2566841598 EngAlarmAcknowledge 2815;
BA_ "SigType" SG_ 2566841598 EngProtectionSystemConfig "DISCRETE";
BA_ "SPN" SG_ 2566841598 EngProtectionSystemConfig 1111;
BA_ "SigType" SG_ 2566841598 EngProtectionSystemTimerState "DISCRETE";
BA_ "SPN" SG_ 2566841598 EngProtectionSystemTimerState 1107;
BA_ "SigType" SG_ 2566841598 EngPrtectionSystemTimerOverride "DISCRETE";
BA_ "SPN" SG_ 2566841598 EngPrtectionSystemTimerOverride 1108;
BA_ "SigType" SG_ 2566841598 EngPrtctnSystmApprchingShutdown "DISCRETE";
BA_ "SPN" SG_ 2566841598 EngPrtctnSystmApprchingShutdown 1109;
BA_ "SigType" SG_ 2566841598 EngPrtctionSystemHasShutdownEng "DISCRETE";
BA_ "SPN" SG_ 2566841598 EngPrtctionSystemHasShutdownEng 1110;
BA_ "SigType" SG_ 2566841598 EngWaitToStartLamp "DISCRETE";
BA_ "SPN" SG_ 2566841598 EngWaitToStartLamp 1081;
BA_ "SigType" SG_ 2566841598 RefrigerantHighPressSwitch "DISCRETE";
BA_ "SPN" SG_ 2566841598 RefrigerantHighPressSwitch 605;
BA_ "SigType" SG_ 2566841598 RefrigerantLowPressSwitch "DISCRETE";
BA_ "SPN" SG_ 2566841598 RefrigerantLowPressSwitch 875;
BA_ "SigType" SG_ 2566841598 A_CHighPressFanSwitch "DISCRETE";
BA_ "SPN" SG_ 2566841598 A_CHighPressFanSwitch 985;
BA_ "SigType" SG_ 2566841598 EngIdleShutdownTimerFunction "DISCRETE";
BA_ "SPN" SG_ 2566841598 EngIdleShutdownTimerFunction 591;
BA_ "SigType" SG_ 2566841598 EngIdleShutdownTimerState "DISCRETE";
BA_ "SPN" SG_ 2566841598 EngIdleShutdownTimerState 590;
BA_ "SigType" SG_ 2566841598 EngIdleShutdownTimerOverride "DISCRETE";
BA_ "SPN" SG_ 2566841598 EngIdleShutdownTimerOverride 592;
BA_ "SigType" SG_ 2566841598 EngIdleShutdownDriverAlertMode "DISCRETE";
BA_ "SPN" SG_ 2566841598 EngIdleShutdownDriverAlertMode 594;
BA_ "SigType" SG_ 2566841598 EngIdleShutdownHasShutdownEng "DISCRETE";
BA_ "SPN" SG_ 2566841598 EngIdleShutdownHasShutdownEng 593;
BA_ "SigType" SG_ 2566832382 ServiceComponentIdentificationB "RANGE";
BA_ "SPN" SG_ 2566832382 ServiceComponentIdentificationB 912;
BA_ "SigType" SG_ 2566832382 ServiceComponentIdentificationA "RANGE";
BA_ "SPN" SG_ 2566832382 ServiceComponentIdentificationA 911;
BA_ "SigType" SG_ 2566832382 SrvceDelay_OperationalTimeBased "RANGE";
BA_ "SPN" SG_ 2566832382 SrvceDelay_OperationalTimeBased 916;
BA_ "SigType" SG_ 2566832382 ServiceDelay_CalendarTimeBased "RANGE";
BA_ "SPN" SG_ 2566832382 ServiceDelay_CalendarTimeBased 915;
BA_ "SigType" SG_ 2566832382 ServiceDistance "RANGE";
BA_ "SPN" SG_ 2566832382 ServiceDistance 914;
BA_ "SigType" SG_ 2566832382 ServiceComponentIdentification "RANGE";
BA_ "SPN" SG_ 2566832382 ServiceComponentIdentification 1584;
BA_ "SigType" SG_ 2633928446 TimeSinceLastService "RANGE";
BA_ "SPN" SG_ 2633928446 TimeSinceLastService 1350;
BA_ "SigType" SG_ 2633928446 ServiceComponentIdentification "RANGE";
BA_ "SPN" SG_ 2633928446 ServiceComponentIdentification 1584;
BA_ "SigType" SG_ 2566804478 MaxContinuousRetarderTorque "RANGE";
BA_ "SPN" SG_ 2566804478 MaxContinuousRetarderTorque 1782;
BA_ "SigType" SG_ 2566804478 MinContinuousRetarderSpeed "RANGE";
BA_ "SPN" SG_ 2566804478 MinContinuousRetarderSpeed 1781;
BA_ "SigType" SG_ 2566804478 MaxContinuousRetarderSpeed "RANGE";
BA_ "SPN" SG_ 2566804478 MaxContinuousRetarderSpeed 1780;
BA_ "SigType" SG_ 2566804478 HghLmtThrshhldFrMnCntnsTrqFrmRtr "RANGE";
BA_ "SPN" SG_ 2566804478 HghLmtThrshhldFrMnCntnsTrqFrmRtr 1779;
BA_ "SigType" SG_ 2566804478 LwLmtThrshhldFrMxTrqFrmRetarder "RANGE";
BA_ "SPN" SG_ 2566804478 LwLmtThrshhldFrMxTrqFrmRetarder 1778;
BA_ "SigType" SG_ 2566804478 HghLmtThrshhldFrMnCntnsRPMFrmRtr "RANGE";
BA_ "SPN" SG_ 2566804478 HghLmtThrshhldFrMnCntnsRPMFrmRtr 1777;
BA_ "SigType" SG_ 2566804478 LwLmtThrshhldFrMxRPMFrmRetarder "RANGE";
BA_ "SPN" SG_ 2566804478 LwLmtThrshhldFrMxRPMFrmRetarder 1776;
BA_ "SigType" SG_ 2566804478 MinContinuousRetarderTorque "RANGE";
BA_ "SPN" SG_ 2566804478 MinContinuousRetarderTorque 1783;
BA_ "SigType" SG_ 2566847486 HydRetarderOilTemp "RANGE";
BA_ "SPN" SG_ 2566847486 HydRetarderOilTemp 120;
BA_ "SigType" SG_ 2566847486 HydRetarderPress "RANGE";
BA_ "SPN" SG_ 2566847486 HydRetarderPress 119;
BA_ "SigType" SG_ 2631859966 EngBuildHoursReset "DISCRETE";
BA_ "SPN" SG_ 2631859966 EngBuildHoursReset 1211;
BA_ "SigType" SG_ 2631859966 ServiceComponentIdentification "RANGE";
BA_ "SPN" SG_ 2631859966 ServiceComponentIdentification 1584;
BA_ "SigType" SG_ 2631859966 TripGroup2Proprietary "DISCRETE";
BA_ "SPN" SG_ 2631859966 TripGroup2Proprietary 989;
BA_ "SigType" SG_ 2631859966 TripGroup1 "DISCRETE";
BA_ "SPN" SG_ 2631859966 TripGroup1 988;
BA_ "SigType" SG_ 2566840830 PercentTorqueAtPeakTorquePoint5 "RANGE";
BA_ "SPN" SG_ 2566840830 PercentTorqueAtPeakTorquePoint5 555;
BA_ "SigType" SG_ 2566840830 ReferenceRetarderTorque "RANGE";
BA_ "SPN" SG_ 2566840830 ReferenceRetarderTorque 556;
BA_ "SigType" SG_ 2566840830 RetarderSpeedAtPeakTorquePoint5 "RANGE";
BA_ "SPN" SG_ 2566840830 RetarderSpeedAtPeakTorquePoint5 547;
BA_ "SigType" SG_ 2566840830 PercentTorqueAtPoint4 "RANGE";
BA_ "SPN" SG_ 2566840830 PercentTorqueAtPoint4 554;
BA_ "SigType" SG_ 2566840830 RetarderSpeedAtPoint4 "RANGE";
BA_ "SPN" SG_ 2566840830 RetarderSpeedAtPoint4 550;
BA_ "SigType" SG_ 2566840830 PercentTorqueAtPoint3 "RANGE";
BA_ "SPN" SG_ 2566840830 PercentTorqueAtPoint3 553;
BA_ "SigType" SG_ 2566840830 RetarderSpeedAtPoint3 "RANGE";
BA_ "SPN" SG_ 2566840830 RetarderSpeedAtPoint3 549;
BA_ "SigType" SG_ 2566840830 PercentTorqueAtMaxSpeedPoint2 "RANGE";
BA_ "SPN" SG_ 2566840830 PercentTorqueAtMaxSpeedPoint2 552;
BA_ "SigType" SG_ 2566840830 MaxRetarderSpeedPoint2 "RANGE";
BA_ "SPN" SG_ 2566840830 MaxRetarderSpeedPoint2 548;
BA_ "SigType" SG_ 2566840830 PercentTorqueAtIdlePoint1 "RANGE";
BA_ "SPN" SG_ 2566840830 PercentTorqueAtIdlePoint1 551;
BA_ "SigType" SG_ 2566840830 RetarderSpeedAtIdlePoint1 "RANGE";
BA_ "SPN" SG_ 2566840830 RetarderSpeedAtIdlePoint1 546;
BA_ "SigType" SG_ 2566840830 RetarderCtrlMethod "RANGE";
BA_ "SPN" SG_ 2566840830 RetarderCtrlMethod 557;
BA_ "SigType" SG_ 2566840830 RetarderLocation "DISCRETE";
BA_ "SPN" SG_ 2566840830 RetarderLocation 902;
BA_ "SigType" SG_ 2566840830 RetarderType "DISCRETE";
BA_ "SPN" SG_ 2566840830 RetarderType 901;
BA_ "SigType" SG_ 2633930238 EngOperationTimeSinceRebuild "RANGE";
BA_ "SPN" SG_ 2633930238 EngOperationTimeSinceRebuild 1193;
BA_ "SigType" SG_ 2566844670 OperatorPTOMemorySelectSwitch "DISCRETE";
BA_ "SPN" SG_ 2566844670 OperatorPTOMemorySelectSwitch 2897;
BA_ "SigType" SG_ 2566844670 EngPTOAccelerateSwitch "DISCRETE";
BA_ "SPN" SG_ 2566844670 EngPTOAccelerateSwitch 981;
BA_ "SigType" SG_ 2566844670 EngPTOResumeSwitch "DISCRETE";
BA_ "SPN" SG_ 2566844670 EngPTOResumeSwitch 982;
BA_ "SigType" SG_ 2566844670 EngPTOCoast_DecelerateSwitch "DISCRETE";
BA_ "SPN" SG_ 2566844670 EngPTOCoast_DecelerateSwitch 983;
BA_ "SigType" SG_ 2566844670 EngPTOSetSwitch "DISCRETE";
BA_ "SPN" SG_ 2566844670 EngPTOSetSwitch 984;
BA_ "SigType" SG_ 2566844670 EngRmtPTOVriableSpeedCtrlSwitch "DISCRETE";
BA_ "SPN" SG_ 2566844670 EngRmtPTOVriableSpeedCtrlSwitch 978;
BA_ "SigType" SG_ 2566844670 EngRmtPTOPrprgrmmdSpdCtrlSwitch "DISCRETE";
BA_ "SPN" SG_ 2566844670 EngRmtPTOPrprgrmmdSpdCtrlSwitch 979;
BA_ "SigType" SG_ 2566844670 EngPTOEnableSwitch "DISCRETE";
BA_ "SPN" SG_ 2566844670 EngPTOEnableSwitch 980;
BA_ "SigType" SG_ 2566844670 PowerTakeoffSetSpeed "RANGE";
BA_ "SPN" SG_ 2566844670 PowerTakeoffSetSpeed 187;
BA_ "SigType" SG_ 2566844670 PowerTakeoffSpeed "RANGE";
BA_ "SPN" SG_ 2566844670 PowerTakeoffSpeed 186;
BA_ "SigType" SG_ 2566844670 PowerTakeoffOilTemp "RANGE";
BA_ "SPN" SG_ 2566844670 PowerTakeoffOilTemp 90;
BA_ "SigType" SG_ 2566844670 RmtPTOPrprgrmmdSpeedCtrlSwitch2 "DISCRETE";
BA_ "SPN" SG_ 2566844670 RmtPTOPrprgrmmdSpeedCtrlSwitch2 3447;
BA_ "SigType" SG_ 2566844670 AuxInputIgnoreSwitch "DISCRETE";
BA_ "SPN" SG_ 2566844670 AuxInputIgnoreSwitch 3448;
BA_ "SigType" SG_ 2566770174 RearWasherFunction "DISCRETE";
BA_ "SPN" SG_ 2566770174 RearWasherFunction 2868;
BA_ "SigType" SG_ 2566770174 FrontOperatorWasherSwitch "DISCRETE";
BA_ "SPN" SG_ 2566770174 FrontOperatorWasherSwitch 2866;
BA_ "SigType" SG_ 2566770174 FrontNonoperatorWasherSwitch "DISCRETE";
BA_ "SPN" SG_ 2566770174 FrontNonoperatorWasherSwitch 2867;
BA_ "SigType" SG_ 2566770174 RearWiperDelayCtrl "RANGE";
BA_ "SPN" SG_ 2566770174 RearWiperDelayCtrl 2871;
BA_ "SigType" SG_ 2566770174 FrontNonoperatorWiperDelayCtrl "RANGE";
BA_ "SPN" SG_ 2566770174 FrontNonoperatorWiperDelayCtrl 2870;
BA_ "SigType" SG_ 2566770174 FrontOperatorWiperDelayCtrl "RANGE";
BA_ "SPN" SG_ 2566770174 FrontOperatorWiperDelayCtrl 2869;
BA_ "SigType" SG_ 2566770174 RearWiperSwitch "DISCRETE";
BA_ "SPN" SG_ 2566770174 RearWiperSwitch 2865;
BA_ "SigType" SG_ 2566770174 FrontOperatorWiperSwitch "DISCRETE";
BA_ "SPN" SG_ 2566770174 FrontOperatorWiperSwitch 2863;
BA_ "SigType" SG_ 2566770174 FrontNonoperatorWiperSwitch "DISCRETE";
BA_ "SPN" SG_ 2566770174 FrontNonoperatorWiperSwitch 2864;
BA_ "SigType" SG_ 2566769662 EngAltDroopAuxInputSelect "DISCRETE";
BA_ "SPN" SG_ 2566769662 EngAltDroopAuxInputSelect 2885;
BA_ "SigType" SG_ 2566769662 EngAltDroopRemoteAccelSelect "DISCRETE";
BA_ "SPN" SG_ 2566769662 EngAltDroopRemoteAccelSelect 2886;
BA_ "SigType" SG_ 2566769662 EngAltDroopAccel2Select "DISCRETE";
BA_ "SPN" SG_ 2566769662 EngAltDroopAccel2Select 2879;
BA_ "SigType" SG_ 2566769662 EngAltDroopAccel1Select "DISCRETE";
BA_ "SPN" SG_ 2566769662 EngAltDroopAccel1Select 2881;
BA_ "SigType" SG_ 2566769662 EngAltRatingSelect "RANGE";
BA_ "SPN" SG_ 2566769662 EngAltRatingSelect 2882;
BA_ "SigType" SG_ 2566769662 EngAltLowIdleSwitch "DISCRETE";
BA_ "SPN" SG_ 2566769662 EngAltLowIdleSwitch 2883;
BA_ "SigType" SG_ 2566769662 EngSynchronizationSwitch "DISCRETE";
BA_ "SPN" SG_ 2566769662 EngSynchronizationSwitch 1377;
BA_ "SigType" SG_ 2566769662 EngAuxGovernorSwitch "DISCRETE";
BA_ "SPN" SG_ 2566769662 EngAuxGovernorSwitch 2884;
BA_ "SigType" SG_ 2566768638 EngAltDroopAuxInputSelectState "DISCRETE";
BA_ "SPN" SG_ 2566768638 EngAltDroopAuxInputSelectState 2895;
BA_ "SigType" SG_ 2566768638 EngAltDrpRemoteAccelSelectState "DISCRETE";
BA_ "SPN" SG_ 2566768638 EngAltDrpRemoteAccelSelectState 2894;
BA_ "SigType" SG_ 2566768638 EngAltDroopAccel2SelectState "DISCRETE";
BA_ "SPN" SG_ 2566768638 EngAltDroopAccel2SelectState 2893;
BA_ "SigType" SG_ 2566768638 EngAltDroopAccel1SelectState "DISCRETE";
BA_ "SPN" SG_ 2566768638 EngAltDroopAccel1SelectState 2889;
BA_ "SigType" SG_ 2566768638 EngAltRatingSelectState "RANGE";
BA_ "SPN" SG_ 2566768638 EngAltRatingSelectState 2888;
BA_ "SigType" SG_ 2566768638 EngAltLowIdleSelectState "DISCRETE";
BA_ "SPN" SG_ 2566768638 EngAltLowIdleSelectState 2891;
BA_ "SigType" SG_ 2566768638 EngMultiUnitSyncState "DISCRETE";
BA_ "SPN" SG_ 2566768638 EngMultiUnitSyncState 2890;
BA_ "SigType" SG_ 2566768638 EngAuxGovernorState "DISCRETE";
BA_ "SPN" SG_ 2566768638 EngAuxGovernorState 2896;
BA_ "SigType" SG_ 2365443326 OprtrsDesiredDelayedLampOffTime "RANGE";
BA_ "SPN" SG_ 2365443326 OprtrsDesiredDelayedLampOffTime 2877;
BA_ "SigType" SG_ 2365443326 OperatorsDesiredBacklight "RANGE";
BA_ "SPN" SG_ 2365443326 OperatorsDesiredBacklight 2878;
BA_ "SigType" SG_ 2365443326 HighLowBeamSwitch "DISCRETE";
BA_ "SPN" SG_ 2365443326 HighLowBeamSwitch 2874;
BA_ "SigType" SG_ 2365443326 HazardLightSwitch "DISCRETE";
BA_ "SPN" SG_ 2365443326 HazardLightSwitch 2875;
BA_ "SigType" SG_ 2365443326 TurnSignalSwitch "DISCRETE";
BA_ "SPN" SG_ 2365443326 TurnSignalSwitch 2876;
BA_ "SigType" SG_ 2365443326 MainLightSwitch "DISCRETE";
BA_ "SPN" SG_ 2365443326 MainLightSwitch 2872;
BA_ "SigType" SG_ 2365443326 WorkLightSwitch "DISCRETE";
BA_ "SPN" SG_ 2365443326 WorkLightSwitch 2873;
BA_ "SigType" SG_ 2566776318 AppliedVehicleSpeedLimit "RANGE";
BA_ "SPN" SG_ 2566776318 AppliedVehicleSpeedLimit 2595;
BA_ "SigType" SG_ 2566776318 MaxVehicleSpeedLimit7 "RANGE";
BA_ "SPN" SG_ 2566776318 MaxVehicleSpeedLimit7 2594;
BA_ "SigType" SG_ 2566776318 MaxVehicleSpeedLimit6 "RANGE";
BA_ "SPN" SG_ 2566776318 MaxVehicleSpeedLimit6 2593;
BA_ "SigType" SG_ 2566776318 MaxVehicleSpeedLimit5 "RANGE";
BA_ "SPN" SG_ 2566776318 MaxVehicleSpeedLimit5 2592;
BA_ "SigType" SG_ 2566776318 MaxVehicleSpeedLimit4 "RANGE";
BA_ "SPN" SG_ 2566776318 MaxVehicleSpeedLimit4 2591;
BA_ "SigType" SG_ 2566776318 MaxVehicleSpeedLimit3 "RANGE";
BA_ "SPN" SG_ 2566776318 MaxVehicleSpeedLimit3 2590;
BA_ "SigType" SG_ 2566776318 MaxVehicleSpeedLimit2 "RANGE";
BA_ "SPN" SG_ 2566776318 MaxVehicleSpeedLimit2 2589;
BA_ "SigType" SG_ 2566776318 MaxVehicleSpeedLimit1 "RANGE";
BA_ "SPN" SG_ 2566776318 MaxVehicleSpeedLimit1 2588;
BA_ "SigType" SG_ 2566802686 OprtrsBlckOutIntensitySelection "RANGE";
BA_ "SPN" SG_ 2566802686 OprtrsBlckOutIntensitySelection 1844;
BA_ "SigType" SG_ 2566802686 BlackOutWorkLampSelect "DISCRETE";
BA_ "SPN" SG_ 2566802686 BlackOutWorkLampSelect 1842;
BA_ "SigType" SG_ 2566802686 NightVisionIlluminatorSelect "DISCRETE";
BA_ "SPN" SG_ 2566802686 NightVisionIlluminatorSelect 1843;
BA_ "SigType" SG_ 2566802686 BlackOutBrake_StopLampSelect "DISCRETE";
BA_ "SPN" SG_ 2566802686 BlackOutBrake_StopLampSelect 1841;
BA_ "SigType" SG_ 2566802686 ConvoyDrivingLampSelect "DISCRETE";
BA_ "SPN" SG_ 2566802686 ConvoyDrivingLampSelect 1837;
BA_ "SigType" SG_ 2566802686 ConvoyLampSelect "DISCRETE";
BA_ "SPN" SG_ 2566802686 ConvoyLampSelect 1838;
BA_ "SigType" SG_ 2566802686 FrontBlackOutMarkerLampSelect "DISCRETE";
BA_ "SPN" SG_ 2566802686 FrontBlackOutMarkerLampSelect 1839;
BA_ "SigType" SG_ 2566802686 RearBlackOutMarkerSelect "DISCRETE";
BA_ "SPN" SG_ 2566802686 RearBlackOutMarkerSelect 1840;
BA_ "SigType" SG_ 2566774014 SlowVesselModeStatus "DISCRETE";
BA_ "SPN" SG_ 2566774014 SlowVesselModeStatus 2617;
BA_ "SigType" SG_ 2566774014 TrollingModeStatus "DISCRETE";
BA_ "SPN" SG_ 2566774014 TrollingModeStatus 2616;
BA_ "SigType" SG_ 2566774014 EngThrttlSynchrnztionModeStatus "DISCRETE";
BA_ "SPN" SG_ 2566774014 EngThrttlSynchrnztionModeStatus 2615;
BA_ "SigType" SG_ 2566823166 EngMainBearing11Temp "RANGE";
BA_ "SPN" SG_ 2566823166 EngMainBearing11Temp 1167;
BA_ "SigType" SG_ 2566823166 EngMainBearing10Temp "RANGE";
BA_ "SPN" SG_ 2566823166 EngMainBearing10Temp 1166;
BA_ "SigType" SG_ 2566823166 EngMainBearing9Temp "RANGE";
BA_ "SPN" SG_ 2566823166 EngMainBearing9Temp 1165;
BA_ "SigType" SG_ 2566823422 EngMainBearing8Temp "RANGE";
BA_ "SPN" SG_ 2566823422 EngMainBearing8Temp 1164;
BA_ "SigType" SG_ 2566823422 EngMainBearing7Temp "RANGE";
BA_ "SPN" SG_ 2566823422 EngMainBearing7Temp 1163;
BA_ "SigType" SG_ 2566823422 EngMainBearing6Temp "RANGE";
BA_ "SPN" SG_ 2566823422 EngMainBearing6Temp 1162;
BA_ "SigType" SG_ 2566823422 EngMainBearing5Temp "RANGE";
BA_ "SPN" SG_ 2566823422 EngMainBearing5Temp 1161;
BA_ "SigType" SG_ 2566823678 EngMainBearing4Temp "RANGE";
BA_ "SPN" SG_ 2566823678 EngMainBearing4Temp 1160;
BA_ "SigType" SG_ 2566823678 EngMainBearing3Temp "RANGE";
BA_ "SPN" SG_ 2566823678 EngMainBearing3Temp 1159;
BA_ "SigType" SG_ 2566823678 EngMainBearing2Temp "RANGE";
BA_ "SPN" SG_ 2566823678 EngMainBearing2Temp 1158;
BA_ "SigType" SG_ 2566823678 EngMainBearing1Temp "RANGE";
BA_ "SPN" SG_ 2566823678 EngMainBearing1Temp 1157;
BA_ "SigType" SG_ 2432595710 DisplayDeadbands "DISCRETE";
BA_ "SPN" SG_ 2432595710 DisplayDeadbands 2577;
BA_ "SigType" SG_ 2432595710 LEDPatternCtrl "DISCRETE";
BA_ "SPN" SG_ 2432595710 LEDPatternCtrl 2578;
BA_ "SigType" SG_ 2432595710 LEDDisplayDeadbandCtrl "DISCRETE";
BA_ "SPN" SG_ 2432595710 LEDDisplayDeadbandCtrl 1806;
BA_ "SigType" SG_ 2432595710 LEDDisplayModeCtrl "DISCRETE";
BA_ "SPN" SG_ 2432595710 LEDDisplayModeCtrl 1805;
BA_ "SigType" SG_ 2432595710 LEDDisplayData1 "RANGE";
BA_ "SPN" SG_ 2432595710 LEDDisplayData1 1573;
BA_ "SigType" SG_ 2365486590 AbsLaserStrikePosition "RANGE";
BA_ "SPN" SG_ 2365486590 AbsLaserStrikePosition 2794;
BA_ "SigType" SG_ 2365486590 LaserStrikeDataLatency "RANGE";
BA_ "SPN" SG_ 2365486590 LaserStrikeDataLatency 2793;
BA_ "SigType" SG_ 2365486590 LaserReceiverType "RANGE";
BA_ "SPN" SG_ 2365486590 LaserReceiverType 2576;
BA_ "SigType" SG_ 2365486590 LaserStrikeVerticalDeviation "RANGE";
BA_ "SPN" SG_ 2365486590 LaserStrikeVerticalDeviation 1574;
BA_ "SigType" SG_ 2365485566 LaserTracerInformation "RANGE";
BA_ "SPN" SG_ 2365485566 LaserTracerInformation 1583;
BA_ "SigType" SG_ 2365485566 LEDDisplayData2 "RANGE";
BA_ "SPN" SG_ 2365485566 LEDDisplayData2 1582;
BA_ "SigType" SG_ 2365485566 LaserTracerHorizontalDeviation "RANGE";
BA_ "SPN" SG_ 2365485566 LaserTracerHorizontalDeviation 1581;
BA_ "SigType" SG_ 2365485566 LaserTracerVerticalDistance "RANGE";
BA_ "SPN" SG_ 2365485566 LaserTracerVerticalDistance 1580;
BA_ "SigType" SG_ 2365485566 LaserTracerTargetDeviation "RANGE";
BA_ "SPN" SG_ 2365485566 LaserTracerTargetDeviation 1579;
BA_ "SigType" SG_ 2633939454 TripDriveFuelEconomy "RANGE";
BA_ "SPN" SG_ 2633939454 TripDriveFuelEconomy 1006;
BA_ "SigType" SG_ 2633939454 TripCruiseFuelUsed "RANGE";
BA_ "SPN" SG_ 2633939454 TripCruiseFuelUsed 1011;
BA_ "SigType" SG_ 2633939454 TripVehicleIdleFuelUsed "RANGE";
BA_ "SPN" SG_ 2633939454 TripVehicleIdleFuelUsed 1010;
BA_ "SigType" SG_ 2633939454 TripPTONonmovingFuelUsed "RANGE";
BA_ "SPN" SG_ 2633939454 TripPTONonmovingFuelUsed 1009;
BA_ "SigType" SG_ 2633939454 TripPTOMovingFuelUsed "RANGE";
BA_ "SPN" SG_ 2633939454 TripPTOMovingFuelUsed 1008;
BA_ "SigType" SG_ 2633939454 TripDriveFuelUsed "RANGE";
BA_ "SPN" SG_ 2633939454 TripDriveFuelUsed 1007;
BA_ "SigType" SG_ 2365486334 BldHeightSetPointHighResolution "RANGE";
BA_ "SPN" SG_ 2365486334 BldHeightSetPointHighResolution 1759;
BA_ "SigType" SG_ 2365486334 ModifySetPoint "RANGE";
BA_ "SPN" SG_ 2365486334 ModifySetPoint 1575;
BA_ "SigType" SG_ 2364542462 SdshftDsrdBldOffsetOperatorCtrl "DISCRETE";
BA_ "SPN" SG_ 2364542462 SdshftDsrdBldOffsetOperatorCtrl 3339;
BA_ "SigType" SG_ 2364542462 SdshftBldCtrlMdeOperatorControl "DISCRETE";
BA_ "SPN" SG_ 2364542462 SdshftBldCtrlMdeOperatorControl 3338;
BA_ "SigType" SG_ 2364542462 RghtDsrdBladeOffsetOperatorCtrl "DISCRETE";
BA_ "SPN" SG_ 2364542462 RghtDsrdBladeOffsetOperatorCtrl 3337;
BA_ "SigType" SG_ 2364542462 RghtBldeCtrlModeOperatorControl "DISCRETE";
BA_ "SPN" SG_ 2364542462 RghtBldeCtrlModeOperatorControl 3335;
BA_ "SigType" SG_ 2364542462 LftDsredBladeOffsetOperatorCtrl "DISCRETE";
BA_ "SPN" SG_ 2364542462 LftDsredBladeOffsetOperatorCtrl 3336;
BA_ "SigType" SG_ 2364542462 LftBladeCtrlModeOperatorControl "DISCRETE";
BA_ "SPN" SG_ 2364542462 LftBladeCtrlModeOperatorControl 3334;
BA_ "SigType" SG_ 2364542462 BladeAutoModeCmd "DISCRETE";
BA_ "SPN" SG_ 2364542462 BladeAutoModeCmd 3158;
BA_ "SigType" SG_ 2364542462 DesiredGradeOffsetSwitch "DISCRETE";
BA_ "SPN" SG_ 2364542462 DesiredGradeOffsetSwitch 3157;
BA_ "SigType" SG_ 2364542462 BladeCtrlModeSwitch "DISCRETE";
BA_ "SPN" SG_ 2364542462 BladeCtrlModeSwitch 3156;
BA_ "SigType" SG_ 2365486078 MastPos "RANGE";
BA_ "SPN" SG_ 2365486078 MastPos 1576;
BA_ "SigType" SG_ 2633937918 TripAverageFuelRate "RANGE";
BA_ "SPN" SG_ 2633937918 TripAverageFuelRate 1031;
BA_ "SigType" SG_ 2633937918 TotalEngPTOFuelUsed "RANGE";
BA_ "SPN" SG_ 2633937918 TotalEngPTOFuelUsed 1030;
BA_ "SigType" SG_ 2566845182 EngAverageFuelEconomy "RANGE";
BA_ "SPN" SG_ 2566845182 EngAverageFuelEconomy 185;
BA_ "SigType" SG_ 2566845182 EngInstantaneousFuelEconomy "RANGE";
BA_ "SPN" SG_ 2566845182 EngInstantaneousFuelEconomy 184;
BA_ "SigType" SG_ 2566845182 EngFuelRate "RANGE";
BA_ "SPN" SG_ 2566845182 EngFuelRate 183;
BA_ "SigType" SG_ 2566845182 EngThrottlePos "RANGE";
BA_ "SPN" SG_ 2566845182 EngThrottlePos 51;
BA_ "SigType" SG_ 2566842878 EngTotalFuelUsed "RANGE";
BA_ "SPN" SG_ 2566842878 EngTotalFuelUsed 250;
BA_ "SigType" SG_ 2566842878 EngTripFuel "RANGE";
BA_ "SPN" SG_ 2566842878 EngTripFuel 182;
BA_ "SigType" SG_ 2633883646 FrontWheelDriveActuatorStatus "DISCRETE";
BA_ "SPN" SG_ 2633883646 FrontWheelDriveActuatorStatus 2612;
BA_ "SigType" SG_ 2633880062 FMSstandardSWversionSupported "RANGE";
BA_ "SPN" SG_ 2633880062 FMSstandardSWversionSupported 2806;
BA_ "SigType" SG_ 2633880062 FMSstandardRqsSupported "DISCRETE";
BA_ "SPN" SG_ 2633880062 FMSstandardRqsSupported 2805;
BA_ "SigType" SG_ 2633880062 FMSstandardDiagnosticsSupported "DISCRETE";
BA_ "SPN" SG_ 2633880062 FMSstandardDiagnosticsSupported 2804;
BA_ "SigType" SG_ 2566806526 LnDprtureIndicationEnableStatus "DISCRETE";
BA_ "SPN" SG_ 2566806526 LnDprtureIndicationEnableStatus 1702;
BA_ "SigType" SG_ 2566806526 LaneTrackingStatusLeftSide "DISCRETE";
BA_ "SPN" SG_ 2566806526 LaneTrackingStatusLeftSide 1710;
BA_ "SigType" SG_ 2566806526 LaneTrackingStatusRightSide "DISCRETE";
BA_ "SPN" SG_ 2566806526 LaneTrackingStatusRightSide 1711;
BA_ "SigType" SG_ 2431649790 LaneDepartureImminentLeftSide "DISCRETE";
BA_ "SPN" SG_ 2431649790 LaneDepartureImminentLeftSide 1700;
BA_ "SigType" SG_ 2431649790 LaneDepartureImminentRightSide "DISCRETE";
BA_ "SPN" SG_ 2431649790 LaneDepartureImminentRightSide 1701;
BA_ "SigType" SG_ 2633929214 EngFuelLeakage2 "DISCRETE";
BA_ "SPN" SG_ 2633929214 EngFuelLeakage2 1240;
BA_ "SigType" SG_ 2633929214 EngFuelLeakage1 "DISCRETE";
BA_ "SPN" SG_ 2633929214 EngFuelLeakage1 1239;
BA_ "SigType" SG_ 2566831614 FanSpeed "RANGE";
BA_ "SPN" SG_ 2566831614 FanSpeed 1639;
BA_ "SigType" SG_ 2566831614 FanDriveState "DISCRETE";
BA_ "SPN" SG_ 2566831614 FanDriveState 977;
BA_ "SigType" SG_ 2566831614 EstPercentFanSpeed "RANGE";
BA_ "SPN" SG_ 2566831614 EstPercentFanSpeed 975;
BA_ "SigType" SG_ 2566820094 EngTorqueLimit6AxleInput "RANGE";
BA_ "SPN" SG_ 2566820094 EngTorqueLimit6AxleInput 1263;
BA_ "SigType" SG_ 2566820094 EngTorqueLimit5Switch "RANGE";
BA_ "SPN" SG_ 2566820094 EngTorqueLimit5Switch 1262;
BA_ "SigType" SG_ 2566820094 EngTorqueLimit4Trans "RANGE";
BA_ "SPN" SG_ 2566820094 EngTorqueLimit4Trans 1261;
BA_ "SigType" SG_ 2566820094 EngTorqueLimit3Trans "RANGE";
BA_ "SPN" SG_ 2566820094 EngTorqueLimit3Trans 1260;
BA_ "SigType" SG_ 2566820094 TransGearRatio3 "RANGE";
BA_ "SPN" SG_ 2566820094 TransGearRatio3 1259;
BA_ "SigType" SG_ 2566820094 EngTorqueLimit2Trans "RANGE";
BA_ "SPN" SG_ 2566820094 EngTorqueLimit2Trans 1258;
BA_ "SigType" SG_ 2566820094 TransGearRatio2 "RANGE";
BA_ "SPN" SG_ 2566820094 TransGearRatio2 1257;
BA_ "SigType" SG_ 2566820094 EngTorqueLimit1Trans "RANGE";
BA_ "SPN" SG_ 2566820094 EngTorqueLimit1Trans 1256;
BA_ "SigType" SG_ 2566820094 TransGearRatio1 "RANGE";
BA_ "SPN" SG_ 2566820094 TransGearRatio1 1255;
BA_ "SigType" SG_ 2566820094 EngTorqueLimitFeature "DISCRETE";
BA_ "SPN" SG_ 2566820094 EngTorqueLimitFeature 1632;
BA_ "SigType" SG_ 2566820094 TorqueLimitingFeatureStatus "DISCRETE";
BA_ "SPN" SG_ 2566820094 TorqueLimitingFeatureStatus 1254;
BA_ "SigType" SG_ 2566820094 CalibRecordDurationTime "RANGE";
BA_ "SPN" SG_ 2566820094 CalibRecordDurationTime 1253;
BA_ "SigType" SG_ 2566820094 CalibRecordStartYear "RANGE";
BA_ "SPN" SG_ 2566820094 CalibRecordStartYear 1252;
BA_ "SigType" SG_ 2566820094 CalibRecordStartDay "RANGE";
BA_ "SPN" SG_ 2566820094 CalibRecordStartDay 1251;
BA_ "SigType" SG_ 2566820094 CalibRecordStartMonth "RANGE";
BA_ "SPN" SG_ 2566820094 CalibRecordStartMonth 1250;
BA_ "SigType" SG_ 2566820094 EngPeakTorque2 "RANGE";
BA_ "SPN" SG_ 2566820094 EngPeakTorque2 1249;
BA_ "SigType" SG_ 2566820094 EngPeakTorque1 "RANGE";
BA_ "SPN" SG_ 2566820094 EngPeakTorque1 1248;
BA_ "SigType" SG_ 2566820094 EngPower "RANGE";
BA_ "SPN" SG_ 2566820094 EngPower 1247;
BA_ "SigType" SG_ 2566820094 NumberOfEngTorqueHistoryRecords "RANGE";
BA_ "SPN" SG_ 2566820094 NumberOfEngTorqueHistoryRecords 1246;
BA_ "SigType" SG_ 2364542206 TransTorqueConverterRatio "RANGE";
BA_ "SPN" SG_ 2364542206 TransTorqueConverterRatio 3030;
BA_ "SigType" SG_ 2566802174 TransRqedGearFeedback "RANGE";
BA_ "SPN" SG_ 2566802174 TransRqedGearFeedback 3289;
BA_ "SigType" SG_ 2566802174 TransMode1Indicator "DISCRETE";
BA_ "SPN" SG_ 2566802174 TransMode1Indicator 2536;
BA_ "SigType" SG_ 2566802174 TransMode2Indicator "DISCRETE";
BA_ "SPN" SG_ 2566802174 TransMode2Indicator 2537;
BA_ "SigType" SG_ 2566802174 TransMode3Indicator "DISCRETE";
BA_ "SPN" SG_ 2566802174 TransMode3Indicator 2538;
BA_ "SigType" SG_ 2566802174 TransMode4Indicator "DISCRETE";
BA_ "SPN" SG_ 2566802174 TransMode4Indicator 2539;
BA_ "SigType" SG_ 2566802174 TransShiftInhibitIndicator "DISCRETE";
BA_ "SPN" SG_ 2566802174 TransShiftInhibitIndicator 1851;
BA_ "SigType" SG_ 2566802174 TransEngCrankEnable "DISCRETE";
BA_ "SPN" SG_ 2566802174 TransEngCrankEnable 2900;
BA_ "SigType" SG_ 2566802174 ActiveShiftConsoleIndicator "DISCRETE";
BA_ "SPN" SG_ 2566802174 ActiveShiftConsoleIndicator 2945;
BA_ "SigType" SG_ 2566802174 TransReadyForBrakeRelease "DISCRETE";
BA_ "SPN" SG_ 2566802174 TransReadyForBrakeRelease 3086;
BA_ "SigType" SG_ 2566802174 TransRqedRangeDisplayFlashState "DISCRETE";
BA_ "SPN" SG_ 2566802174 TransRqedRangeDisplayFlashState 1849;
BA_ "SigType" SG_ 2566802174 TransRqedRangeDisplayBlankState "DISCRETE";
BA_ "SPN" SG_ 2566802174 TransRqedRangeDisplayBlankState 1850;
BA_ "SigType" SG_ 2633935870 ClutchLifeRemaining "RANGE";
BA_ "SPN" SG_ 2633935870 ClutchLifeRemaining 2983;
BA_ "SigType" SG_ 2633935870 LowestPossibleGear "RANGE";
BA_ "SPN" SG_ 2633935870 LowestPossibleGear 1114;
BA_ "SigType" SG_ 2633935870 HighestPossibleGear "RANGE";
BA_ "SPN" SG_ 2633935870 HighestPossibleGear 1115;
BA_ "SigType" SG_ 2633935870 RecommendedGear "RANGE";
BA_ "SPN" SG_ 2633935870 RecommendedGear 1113;
BA_ "SigType" SG_ 2633942014 TransForwardDirectionSwitch "DISCRETE";
BA_ "SPN" SG_ 2633942014 TransForwardDirectionSwitch 903;
BA_ "SigType" SG_ 2633942014 TransNeutralSwitch "DISCRETE";
BA_ "SPN" SG_ 2633942014 TransNeutralSwitch 604;
BA_ "SigType" SG_ 2633942014 TransReverseDirectionSwitch "DISCRETE";
BA_ "SPN" SG_ 2633942014 TransReverseDirectionSwitch 767;
BA_ "SigType" SG_ 2633942014 TransLowRangeSenseSwitch "DISCRETE";
BA_ "SPN" SG_ 2633942014 TransLowRangeSenseSwitch 779;
BA_ "SigType" SG_ 2633942014 TransHighRangeSenseSwitch "DISCRETE";
BA_ "SPN" SG_ 2633942014 TransHighRangeSenseSwitch 778;
BA_ "SigType" SG_ 2633942526 TransSynchronizerBrakeValue "RANGE";
BA_ "SPN" SG_ 2633942526 TransSynchronizerBrakeValue 54;
BA_ "SigType" SG_ 2633942526 TransSynchronizerClutchValue "RANGE";
BA_ "SPN" SG_ 2633942526 TransSynchronizerClutchValue 53;
BA_ "SigType" SG_ 2633943038 TransInertiaBrakeActuator "DISCRETE";
BA_ "SPN" SG_ 2633943038 TransInertiaBrakeActuator 787;
BA_ "SigType" SG_ 2633943038 TransDefuelActuator "DISCRETE";
BA_ "SPN" SG_ 2633943038 TransDefuelActuator 786;
BA_ "SigType" SG_ 2633943038 TransLockupClutchActuator "DISCRETE";
BA_ "SPN" SG_ 2633943038 TransLockupClutchActuator 740;
BA_ "SigType" SG_ 2633943038 TransClutchActuator "DISCRETE";
BA_ "SPN" SG_ 2633943038 TransClutchActuator 788;
BA_ "SigType" SG_ 2633943038 TransSplitterIndirectActuator "DISCRETE";
BA_ "SPN" SG_ 2633943038 TransSplitterIndirectActuator 771;
BA_ "SigType" SG_ 2633943038 TransSplitterDirectActuator "DISCRETE";
BA_ "SPN" SG_ 2633943038 TransSplitterDirectActuator 770;
BA_ "SigType" SG_ 2633943038 TransRangeLowActuator "DISCRETE";
BA_ "SPN" SG_ 2633943038 TransRangeLowActuator 769;
BA_ "SigType" SG_ 2633943038 TransRangeHighActuator "DISCRETE";
BA_ "SPN" SG_ 2633943038 TransRangeHighActuator 768;
BA_ "SigType" SG_ 2633943038 TransShiftFingerGearActuator2 "DISCRETE";
BA_ "SPN" SG_ 2633943038 TransShiftFingerGearActuator2 784;
BA_ "SigType" SG_ 2633943038 TransShiftFingerRailActuator2 "DISCRETE";
BA_ "SPN" SG_ 2633943038 TransShiftFingerRailActuator2 783;
BA_ "SigType" SG_ 2633943038 TransShiftFingerGearActuator1 "DISCRETE";
BA_ "SPN" SG_ 2633943038 TransShiftFingerGearActuator1 773;
BA_ "SigType" SG_ 2633943038 TransShiftFingerRailActuator1 "DISCRETE";
BA_ "SPN" SG_ 2633943038 TransShiftFingerRailActuator1 772;
BA_ "SigType" SG_ 2633943038 TrnsShftFngrCenterRailIndicator "DISCRETE";
BA_ "SPN" SG_ 2633943038 TrnsShftFngrCenterRailIndicator 782;
BA_ "SigType" SG_ 2633943038 TrnsShftFngrEngagementIndicator "DISCRETE";
BA_ "SPN" SG_ 2633943038 TrnsShftFngrEngagementIndicator 781;
BA_ "SigType" SG_ 2633943038 TrnsShiftFingerNeutralIndicator "DISCRETE";
BA_ "SPN" SG_ 2633943038 TrnsShiftFingerNeutralIndicator 780;
BA_ "SigType" SG_ 2633943038 TransShiftFingerRailPos "RANGE";
BA_ "SPN" SG_ 2633943038 TransShiftFingerRailPos 60;
BA_ "SigType" SG_ 2633943038 TransShiftFingerGearPos "RANGE";
BA_ "SPN" SG_ 2633943038 TransShiftFingerGearPos 59;
BA_ "SigType" SG_ 2565867006 TransCurrentRange "RANGE";
BA_ "SPN" SG_ 2565867006 TransCurrentRange 163;
BA_ "SigType" SG_ 2565867006 TransRqedRange "RANGE";
BA_ "SPN" SG_ 2565867006 TransRqedRange 162;
BA_ "SigType" SG_ 2565867006 TransCurrentGear "RANGE";
BA_ "SPN" SG_ 2565867006 TransCurrentGear 523;
BA_ "SigType" SG_ 2565867006 TransActualGearRatio "RANGE";
BA_ "SPN" SG_ 2565867006 TransActualGearRatio 526;
BA_ "SigType" SG_ 2565867006 TransSelectedGear "RANGE";
BA_ "SPN" SG_ 2565867006 TransSelectedGear 524;
BA_ "SigType" SG_ 2364539646 SrcAddrssOfCtrllngDvcFrTrnsCtrl "RANGE";
BA_ "SPN" SG_ 2364539646 SrcAddrssOfCtrllngDvcFrTrnsCtrl 1482;
BA_ "SigType" SG_ 2364539646 TransInputShaftSpeed "RANGE";
BA_ "SPN" SG_ 2364539646 TransInputShaftSpeed 161;
BA_ "SigType" SG_ 2364539646 ProgressiveShiftDisable "DISCRETE";
BA_ "SPN" SG_ 2364539646 ProgressiveShiftDisable 607;
BA_ "SigType" SG_ 2364539646 EngMomentaryOverspeedEnable "DISCRETE";
BA_ "SPN" SG_ 2364539646 EngMomentaryOverspeedEnable 606;
BA_ "SigType" SG_ 2364539646 PercentClutchSlip "RANGE";
BA_ "SPN" SG_ 2364539646 PercentClutchSlip 522;
BA_ "SigType" SG_ 2364539646 TransOutputShaftSpeed "RANGE";
BA_ "SPN" SG_ 2364539646 TransOutputShaftSpeed 191;
BA_ "SigType" SG_ 2364539646 TransShiftInProcess "DISCRETE";
BA_ "SPN" SG_ 2364539646 TransShiftInProcess 574;
BA_ "SigType" SG_ 2364539646 TorqueConverterLockupEngaged "DISCRETE";
BA_ "SPN" SG_ 2364539646 TorqueConverterLockupEngaged 573;
BA_ "SigType" SG_ 2364539646 TransDrivelineEngaged "DISCRETE";
BA_ "SPN" SG_ 2364539646 TransDrivelineEngaged 560;
BA_ "SigType" SG_ 2566810110 EngChargeAirCoolerOutletTemp "RANGE";
BA_ "SPN" SG_ 2566810110 EngChargeAirCoolerOutletTemp 2630;
BA_ "SigType" SG_ 2566810110 EngCoolantTempHiRes "RANGE";
BA_ "SPN" SG_ 2566810110 EngCoolantTempHiRes 1637;
BA_ "SigType" SG_ 2566810110 EngIntkVlvActationSystemOilTemp "RANGE";
BA_ "SPN" SG_ 2566810110 EngIntkVlvActationSystemOilTemp 2986;
BA_ "SigType" SG_ 2566810110 EngIntakeManifold1AirTemp "RANGE";
BA_ "SPN" SG_ 2566810110 EngIntakeManifold1AirTemp 1636;
BA_ "SigType" SG_ 2566825214 EngExhaustGasRecirculationTemp "RANGE";
BA_ "SPN" SG_ 2566825214 EngExhaustGasRecirculationTemp 412;
BA_ "SigType" SG_ 2566825214 EngExhstGsRcirculationDiffPress "RANGE";
BA_ "SPN" SG_ 2566825214 EngExhstGsRcirculationDiffPress 411;
BA_ "SigType" SG_ 2566825214 EngECUTemp "RANGE";
BA_ "SPN" SG_ 2566825214 EngECUTemp 1136;
BA_ "SigType" SG_ 2566825214 EngOilTemp2 "RANGE";
BA_ "SPN" SG_ 2566825214 EngOilTemp2 1135;
BA_ "SigType" SG_ 2566844158 EngIntercoolerThermostatOpening "RANGE";
BA_ "SPN" SG_ 2566844158 EngIntercoolerThermostatOpening 1134;
BA_ "SigType" SG_ 2566844158 EngIntercoolerTemp "RANGE";
BA_ "SPN" SG_ 2566844158 EngIntercoolerTemp 52;
BA_ "SigType" SG_ 2566844158 EngTurboOilTemp "RANGE";
BA_ "SPN" SG_ 2566844158 EngTurboOilTemp 176;
BA_ "SigType" SG_ 2566844158 EngOilTemp1 "RANGE";
BA_ "SPN" SG_ 2566844158 EngOilTemp1 175;
BA_ "SigType" SG_ 2566844158 EngFuelTemp "RANGE";
BA_ "SPN" SG_ 2566844158 EngFuelTemp 174;
BA_ "SigType" SG_ 2566844158 EngCoolantTemp "RANGE";
BA_ "SPN" SG_ 2566844158 EngCoolantTemp 110;
BA_ "SigType" SG_ 2566785022 EngExhstExhstGsTempLeftManifold "RANGE";
BA_ "SPN" SG_ 2566785022 EngExhstExhstGsTempLeftManifold 2434;
BA_ "SigType" SG_ 2566785022 EngExhstExhstGsTmpRightManifold "RANGE";
BA_ "SPN" SG_ 2566785022 EngExhstExhstGsTmpRightManifold 2433;
BA_ "SigType" SG_ 2565868542 SterableLiftAxleLoweringInhibit "DISCRETE";
BA_ "SPN" SG_ 2565868542 SterableLiftAxleLoweringInhibit 2922;
BA_ "SigType" SG_ 2565868542 AxleLocation "RANGE";
BA_ "SPN" SG_ 2565868542 AxleLocation 2928;
BA_ "SigType" SG_ 2565868542 TypeOfSteerTrans "DISCRETE";
BA_ "SPN" SG_ 2565868542 TypeOfSteerTrans 2926;
BA_ "SigType" SG_ 2565868542 TypeOfSteerForces "DISCRETE";
BA_ "SPN" SG_ 2565868542 TypeOfSteerForces 2925;
BA_ "SigType" SG_ 2565868542 SteerType "DISCRETE";
BA_ "SPN" SG_ 2565868542 SteerType 2924;
BA_ "SigType" SG_ 2565868542 StatusOfSteerAxle "DISCRETE";
BA_ "SPN" SG_ 2565868542 StatusOfSteerAxle 2923;
BA_ "SigType" SG_ 2565868542 ActualInnerWheelSteerAngle "RANGE";
BA_ "SPN" SG_ 2565868542 ActualInnerWheelSteerAngle 2927;
BA_ "SigType" SG_ 2633941758 TransOutputRetarder "DISCRETE";
BA_ "SPN" SG_ 2633941758 TransOutputRetarder 748;
BA_ "SigType" SG_ 2565865726 RetarderSelectionNonEng "RANGE";
BA_ "SPN" SG_ 2565865726 RetarderSelectionNonEng 1716;
BA_ "SigType" SG_ 2565865726 ActlMxAvlblRtarderPercentTorque "RANGE";
BA_ "SPN" SG_ 2565865726 ActlMxAvlblRtarderPercentTorque 1717;
BA_ "SigType" SG_ 2565865726 DrvrsDmandRetarderPercentTorque "RANGE";
BA_ "SPN" SG_ 2565865726 DrvrsDmandRetarderPercentTorque 1715;
BA_ "SigType" SG_ 2565865726 SrcAddrssOfCtrllngDvcFrRtrdrCtrl "RANGE";
BA_ "SPN" SG_ 2565865726 SrcAddrssOfCtrllngDvcFrRtrdrCtrl 1480;
BA_ "SigType" SG_ 2565865726 RetarderRqingBrakeLight "DISCRETE";
BA_ "SPN" SG_ 2565865726 RetarderRqingBrakeLight 1667;
BA_ "SigType" SG_ 2565865726 EngCoolantLoadIncrease "DISCRETE";
BA_ "SPN" SG_ 2565865726 EngCoolantLoadIncrease 1082;
BA_ "SigType" SG_ 2565865726 IntendedRetarderPercentTorque "RANGE";
BA_ "SPN" SG_ 2565865726 IntendedRetarderPercentTorque 1085;
BA_ "SigType" SG_ 2565865726 ActualRetarderPercentTorque "RANGE";
BA_ "SPN" SG_ 2565865726 ActualRetarderPercentTorque 520;
BA_ "SigType" SG_ 2565865726 RetarderEnableShiftAssistSwitch "DISCRETE";
BA_ "SPN" SG_ 2565865726 RetarderEnableShiftAssistSwitch 572;
BA_ "SigType" SG_ 2565865726 RetarderEnableBrakeAssistSwitch "DISCRETE";
BA_ "SPN" SG_ 2565865726 RetarderEnableBrakeAssistSwitch 571;
BA_ "SigType" SG_ 2565865726 RetarderTorqueMode "DISCRETE";
BA_ "SPN" SG_ 2565865726 RetarderTorqueMode 900;
BA_ "SigType" SG_ 2633932798 EngExhaustGasPort20Temp "RANGE";
BA_ "SPN" SG_ 2633932798 EngExhaustGasPort20Temp 1156;
BA_ "SigType" SG_ 2633932798 EngExhaustGasPort19Temp "RANGE";
BA_ "SPN" SG_ 2633932798 EngExhaustGasPort19Temp 1155;
BA_ "SigType" SG_ 2633932798 EngExhaustGasPort18Temp "RANGE";
BA_ "SPN" SG_ 2633932798 EngExhaustGasPort18Temp 1154;
BA_ "SigType" SG_ 2633932798 EngExhaustGasPort17Temp "RANGE";
BA_ "SPN" SG_ 2633932798 EngExhaustGasPort17Temp 1153;
BA_ "SigType" SG_ 2566824190 EngExhaustGasPort16Temp "RANGE";
BA_ "SPN" SG_ 2566824190 EngExhaustGasPort16Temp 1152;
BA_ "SigType" SG_ 2566824190 EngExhaustGasPort15Temp "RANGE";
BA_ "SPN" SG_ 2566824190 EngExhaustGasPort15Temp 1151;
BA_ "SigType" SG_ 2566824190 EngExhaustGasPort14Temp "RANGE";
BA_ "SPN" SG_ 2566824190 EngExhaustGasPort14Temp 1150;
BA_ "SigType" SG_ 2566824190 EngExhaustGasPort13Temp "RANGE";
BA_ "SPN" SG_ 2566824190 EngExhaustGasPort13Temp 1149;
BA_ "SigType" SG_ 2633933310 EngExhaustGasPort12Temp "RANGE";
BA_ "SPN" SG_ 2633933310 EngExhaustGasPort12Temp 1148;
BA_ "SigType" SG_ 2633933310 EngExhaustGasPort11Temp "RANGE";
BA_ "SPN" SG_ 2633933310 EngExhaustGasPort11Temp 1147;
BA_ "SigType" SG_ 2633933310 EngExhaustGasPort10Temp "RANGE";
BA_ "SPN" SG_ 2633933310 EngExhaustGasPort10Temp 1146;
BA_ "SigType" SG_ 2633933310 EngExhaustGasPort9Temp "RANGE";
BA_ "SPN" SG_ 2633933310 EngExhaustGasPort9Temp 1145;
BA_ "SigType" SG_ 2633933566 EngExhaustGasPort8Temp "RANGE";
BA_ "SPN" SG_ 2633933566 EngExhaustGasPort8Temp 1144;
BA_ "SigType" SG_ 2633933566 EngExhaustGasPort7Temp "RANGE";
BA_ "SPN" SG_ 2633933566 EngExhaustGasPort7Temp 1143;
BA_ "SigType" SG_ 2633933566 EngExhaustGasPort6Temp "RANGE";
BA_ "SPN" SG_ 2633933566 EngExhaustGasPort6Temp 1142;
BA_ "SigType" SG_ 2633933566 EngExhaustGasPort5Temp "RANGE";
BA_ "SPN" SG_ 2633933566 EngExhaustGasPort5Temp 1141;
BA_ "SigType" SG_ 2633933822 EngExhaustGasPort4Temp "RANGE";
BA_ "SPN" SG_ 2633933822 EngExhaustGasPort4Temp 1140;
BA_ "SigType" SG_ 2633933822 EngExhaustGasPort3Temp "RANGE";
BA_ "SPN" SG_ 2633933822 EngExhaustGasPort3Temp 1139;
BA_ "SigType" SG_ 2633933822 EngExhaustGasPort2Temp "RANGE";
BA_ "SPN" SG_ 2633933822 EngExhaustGasPort2Temp 1138;
BA_ "SigType" SG_ 2633933822 EngExhaustGasPort1Temp "RANGE";
BA_ "SPN" SG_ 2633933822 EngExhaustGasPort1Temp 1137;
BA_ "SigType" SG_ 2566776062 PayloadPercentage "RANGE";
BA_ "SPN" SG_ 2566776062 PayloadPercentage 2600;
BA_ "SigType" SG_ 2566771454 DataMemoryUsage "RANGE";
BA_ "SPN" SG_ 2566771454 DataMemoryUsage 2802;
BA_ "SigType" SG_ 2566771454 KeepAliveBatteryConsumption "RANGE";
BA_ "SPN" SG_ 2566771454 KeepAliveBatteryConsumption 2803;
BA_ "SigType" SG_ 2566775806 TravelVelocityCtrlPos "RANGE";
BA_ "SPN" SG_ 2566775806 TravelVelocityCtrlPos 2601;
BA_ "SigType" SG_ 2633935358 EngExhstGsOxygnSnsrClsdLpOprton "DISCRETE";
BA_ "SPN" SG_ 2633935358 EngExhstGsOxygnSnsrClsdLpOprton 1696;
BA_ "SigType" SG_ 2633935358 EngExhstGsOxygnSnsrFlngCrrction "RANGE";
BA_ "SPN" SG_ 2633935358 EngExhstGsOxygnSnsrFlngCrrction 1695;
BA_ "SigType" SG_ 2633935358 EngActualExhaustOxygen "RANGE";
BA_ "SPN" SG_ 2633935358 EngActualExhaustOxygen 1119;
BA_ "SigType" SG_ 2633935358 EngDesiredExhaustOxygen "RANGE";
BA_ "SPN" SG_ 2633935358 EngDesiredExhaustOxygen 1118;
BA_ "SigType" SG_ 2633935358 EngDesiredRatedExhaustOxygen "RANGE";
BA_ "SPN" SG_ 2633935358 EngDesiredRatedExhaustOxygen 1117;
BA_ "SigType" SG_ 2365447166 Jystck3GripXAxisDetentPosStatus "DISCRETE";
BA_ "SPN" SG_ 2365447166 Jystck3GripXAxisDetentPosStatus 2756;
BA_ "SigType" SG_ 2365447166 Jystck3GripYAxisDetentPosStatus "DISCRETE";
BA_ "SPN" SG_ 2365447166 Jystck3GripYAxisDetentPosStatus 2757;
BA_ "SigType" SG_ 2365447166 Jystck3ThetaAxisDetentPosStatus "DISCRETE";
BA_ "SPN" SG_ 2365447166 Jystck3ThetaAxisDetentPosStatus 2758;
BA_ "SigType" SG_ 2365447166 Joystick3ThetaAxisPos "RANGE";
BA_ "SPN" SG_ 2365447166 Joystick3ThetaAxisPos 2738;
BA_ "SigType" SG_ 2365447166 Jystck3ThtAxsClckwsPstvPsStatus "DISCRETE";
BA_ "SPN" SG_ 2365447166 Jystck3ThtAxsClckwsPstvPsStatus 2743;
BA_ "SigType" SG_ 2365447166 Jystck3ThtAxsCntrClckwsNgtvPsStt "DISCRETE";
BA_ "SPN" SG_ 2365447166 Jystck3ThtAxsCntrClckwsNgtvPsStt 2748;
BA_ "SigType" SG_ 2365447166 Jystck3ThtaAxisNeutralPosStatus "DISCRETE";
BA_ "SPN" SG_ 2365447166 Jystck3ThtaAxisNeutralPosStatus 2753;
BA_ "SigType" SG_ 2365447166 Joystick3GripYAxisPos "RANGE";
BA_ "SPN" SG_ 2365447166 Joystick3GripYAxisPos 2737;
BA_ "SigType" SG_ 2365447166 Jystck3GrpYAxsLvrFrwrdPstvPsStts "DISCRETE";
BA_ "SPN" SG_ 2365447166 Jystck3GrpYAxsLvrFrwrdPstvPsStts 2742;
BA_ "SigType" SG_ 2365447166 Jystck3GrpYAxsLvrBckNgtvPsSttus "DISCRETE";
BA_ "SPN" SG_ 2365447166 Jystck3GrpYAxsLvrBckNgtvPsSttus 2747;
BA_ "SigType" SG_ 2365447166 Jystck3GrpYAxisNeutralPosStatus "DISCRETE";
BA_ "SPN" SG_ 2365447166 Jystck3GrpYAxisNeutralPosStatus 2752;
BA_ "SigType" SG_ 2365447166 Joystick3GripXAxisPos "RANGE";
BA_ "SPN" SG_ 2365447166 Joystick3GripXAxisPos 2736;
BA_ "SigType" SG_ 2365447166 Jystck3GrpXAxsLvrRghtPstvPsStts "DISCRETE";
BA_ "SPN" SG_ 2365447166 Jystck3GrpXAxsLvrRghtPstvPsStts 2741;
BA_ "SigType" SG_ 2365447166 Jystck3GrpXAxsLvrLftNgtvPsSttus "DISCRETE";
BA_ "SPN" SG_ 2365447166 Jystck3GrpXAxsLvrLftNgtvPsSttus 2746;
BA_ "SigType" SG_ 2365447166 Jystck3GrpXAxisNeutralPosStatus "DISCRETE";
BA_ "SPN" SG_ 2365447166 Jystck3GrpXAxisNeutralPosStatus 2751;
BA_ "SigType" SG_ 2365446654 Jystck2GripXAxisDetentPosStatus "DISCRETE";
BA_ "SPN" SG_ 2365446654 Jystck2GripXAxisDetentPosStatus 2719;
BA_ "SigType" SG_ 2365446654 Jystck2GripYAxisDetentPosStatus "DISCRETE";
BA_ "SPN" SG_ 2365446654 Jystck2GripYAxisDetentPosStatus 2720;
BA_ "SigType" SG_ 2365446654 Jystck2ThetaAxisDetentPosStatus "DISCRETE";
BA_ "SPN" SG_ 2365446654 Jystck2ThetaAxisDetentPosStatus 2721;
BA_ "SigType" SG_ 2365446654 Joystick2ThetaAxisPos "RANGE";
BA_ "SPN" SG_ 2365446654 Joystick2ThetaAxisPos 2701;
BA_ "SigType" SG_ 2365446654 Jystck2ThtAxsClckwsPstvPsStatus "DISCRETE";
BA_ "SPN" SG_ 2365446654 Jystck2ThtAxsClckwsPstvPsStatus 2706;
BA_ "SigType" SG_ 2365446654 Jystck2ThtAxsCntrClckwsNgtvPsStt "DISCRETE";
BA_ "SPN" SG_ 2365446654 Jystck2ThtAxsCntrClckwsNgtvPsStt 2711;
BA_ "SigType" SG_ 2365446654 Jystck2ThtaAxisNeutralPosStatus "DISCRETE";
BA_ "SPN" SG_ 2365446654 Jystck2ThtaAxisNeutralPosStatus 2716;
BA_ "SigType" SG_ 2365446654 Joystick2GripYAxisPos "RANGE";
BA_ "SPN" SG_ 2365446654 Joystick2GripYAxisPos 2700;
BA_ "SigType" SG_ 2365446654 Jystck2GrpYAxsLvrFrwrdPstvPsStts "DISCRETE";
BA_ "SPN" SG_ 2365446654 Jystck2GrpYAxsLvrFrwrdPstvPsStts 2705;
BA_ "SigType" SG_ 2365446654 Jystck2GrpYAxsLvrBckNgtvPsSttus "DISCRETE";
BA_ "SPN" SG_ 2365446654 Jystck2GrpYAxsLvrBckNgtvPsSttus 2710;
BA_ "SigType" SG_ 2365446654 Jystck2GrpYAxisNeutralPosStatus "DISCRETE";
BA_ "SPN" SG_ 2365446654 Jystck2GrpYAxisNeutralPosStatus 2715;
BA_ "SigType" SG_ 2365446654 Joystick2GripXAxisPos "RANGE";
BA_ "SPN" SG_ 2365446654 Joystick2GripXAxisPos 2699;
BA_ "SigType" SG_ 2365446654 Jystck2GrpXAxsLvrRghtPstvPsStts "DISCRETE";
BA_ "SPN" SG_ 2365446654 Jystck2GrpXAxsLvrRghtPstvPsStts 2704;
BA_ "SigType" SG_ 2365446654 Jystck2GrpXAxsLvrLftNgtvPsSttus "DISCRETE";
BA_ "SPN" SG_ 2365446654 Jystck2GrpXAxsLvrLftNgtvPsSttus 2709;
BA_ "SigType" SG_ 2365446654 Jystck2GrpXAxisNeutralPosStatus "DISCRETE";
BA_ "SPN" SG_ 2365446654 Jystck2GrpXAxisNeutralPosStatus 2714;
BA_ "SigType" SG_ 2365446142 Jystck1GripXAxisDetentPosStatus "DISCRETE";
BA_ "SPN" SG_ 2365446142 Jystck1GripXAxisDetentPosStatus 2682;
BA_ "SigType" SG_ 2365446142 Jystck1GripYAxisDetentPosStatus "DISCRETE";
BA_ "SPN" SG_ 2365446142 Jystck1GripYAxisDetentPosStatus 2683;
BA_ "SigType" SG_ 2365446142 Jystck1ThetaAxisDetentPosStatus "DISCRETE";
BA_ "SPN" SG_ 2365446142 Jystck1ThetaAxisDetentPosStatus 2684;
BA_ "SigType" SG_ 2365446142 Joystick1ThetaAxisPos "RANGE";
BA_ "SPN" SG_ 2365446142 Joystick1ThetaAxisPos 2664;
BA_ "SigType" SG_ 2365446142 Jystck1ThtAxsClckwsPstvPsStatus "DISCRETE";
BA_ "SPN" SG_ 2365446142 Jystck1ThtAxsClckwsPstvPsStatus 2669;
BA_ "SigType" SG_ 2365446142 Jystck1ThtAxsCntrClckwsNgtvPsStt "DISCRETE";
BA_ "SPN" SG_ 2365446142 Jystck1ThtAxsCntrClckwsNgtvPsStt 2674;
BA_ "SigType" SG_ 2365446142 Jystck1ThtaAxisNeutralPosStatus "DISCRETE";
BA_ "SPN" SG_ 2365446142 Jystck1ThtaAxisNeutralPosStatus 2679;
BA_ "SigType" SG_ 2365446142 Joystick1GripYAxisPos "RANGE";
BA_ "SPN" SG_ 2365446142 Joystick1GripYAxisPos 2663;
BA_ "SigType" SG_ 2365446142 Jystck1GrpYAxsLvrFrwrdPstvPsStts "DISCRETE";
BA_ "SPN" SG_ 2365446142 Jystck1GrpYAxsLvrFrwrdPstvPsStts 2668;
BA_ "SigType" SG_ 2365446142 Jystck1GrpYAxsLvrBckNgtvPsSttus "DISCRETE";
BA_ "SPN" SG_ 2365446142 Jystck1GrpYAxsLvrBckNgtvPsSttus 2673;
BA_ "SigType" SG_ 2365446142 Jystck1GrpYAxisNeutralPosStatus "DISCRETE";
BA_ "SPN" SG_ 2365446142 Jystck1GrpYAxisNeutralPosStatus 2678;
BA_ "SigType" SG_ 2365446142 Joystick1GripXAxisPos "RANGE";
BA_ "SPN" SG_ 2365446142 Joystick1GripXAxisPos 2662;
BA_ "SigType" SG_ 2365446142 Jystck1GrpXAxsLvrRghtPstvPsStts "DISCRETE";
BA_ "SPN" SG_ 2365446142 Jystck1GrpXAxsLvrRghtPstvPsStts 2667;
BA_ "SigType" SG_ 2365446142 Jystck1GrpXAxsLvrLftNgtvPsSttus "DISCRETE";
BA_ "SPN" SG_ 2365446142 Jystck1GrpXAxsLvrLftNgtvPsSttus 2672;
BA_ "SigType" SG_ 2365446142 Jystck1GrpXAxisNeutralPosStatus "DISCRETE";
BA_ "SPN" SG_ 2365446142 Jystck1GrpXAxisNeutralPosStatus 2677;
BA_ "SigType" SG_ 2633929470 EngFuelRackPos "RANGE";
BA_ "SPN" SG_ 2633929470 EngFuelRackPos 1210;
BA_ "SigType" SG_ 2633929470 InstantaneousEstBrakePower "RANGE";
BA_ "SPN" SG_ 2633929470 InstantaneousEstBrakePower 1242;
BA_ "SigType" SG_ 2633929470 EngMassFlow "RANGE";
BA_ "SPN" SG_ 2633929470 EngMassFlow 1241;
BA_ "SigType" SG_ 2633929470 EngExhaustGasPress "RANGE";
BA_ "SPN" SG_ 2633929470 EngExhaustGasPress 1209;
BA_ "SigType" SG_ 2633929470 EngPrefilterOilPress "RANGE";
BA_ "SPN" SG_ 2633929470 EngPrefilterOilPress 1208;
BA_ "SigType" SG_ 2633937406 TotalECURunTime "RANGE";
BA_ "SPN" SG_ 2633937406 TotalECURunTime 1033;
BA_ "SigType" SG_ 2633937406 TotalECUDistance "RANGE";
BA_ "SPN" SG_ 2633937406 TotalECUDistance 1032;
BA_ "SigType" SG_ 2364541694 EngInletAirMassFlowRate "RANGE";
BA_ "SPN" SG_ 2364541694 EngInletAirMassFlowRate 132;
BA_ "SigType" SG_ 2364541694 EngExhstGsRcrcltionMassFlowRate "RANGE";
BA_ "SPN" SG_ 2364541694 EngExhstGsRcrcltionMassFlowRate 2659;
BA_ "SigType" SG_ 2566810366 EngFuelFilterSucSideDiffPress "RANGE";
BA_ "SPN" SG_ 2566810366 EngFuelFilterSucSideDiffPress 1382;
BA_ "SigType" SG_ 2566810366 EngFuelSupplyPumpInletPress "RANGE";
BA_ "SPN" SG_ 2566810366 EngFuelSupplyPumpInletPress 1381;
BA_ "SigType" SG_ 2566810366 EngOilLevelRemoteReservoir "RANGE";
BA_ "SPN" SG_ 2566810366 EngOilLevelRemoteReservoir 1380;
BA_ "SigType" SG_ 2566767102 EngExhstGsRcrculationInletPress "RANGE";
BA_ "SPN" SG_ 2566767102 EngExhstGsRcrculationInletPress 3358;
BA_ "SigType" SG_ 2566767102 EngIntkVlvActtionSystemOilPress "RANGE";
BA_ "SPN" SG_ 2566767102 EngIntkVlvActtionSystemOilPress 2948;
BA_ "SigType" SG_ 2566839294 EngInjectorMeteringRail2Press "RANGE";
BA_ "SPN" SG_ 2566839294 EngInjectorMeteringRail2Press 1349;
BA_ "SigType" SG_ 2566839294 EngInjectorTimingRail1Press "RANGE";
BA_ "SPN" SG_ 2566839294 EngInjectorTimingRail1Press 156;
BA_ "SigType" SG_ 2566839294 EngInjectorMeteringRail1Press "RANGE";
BA_ "SPN" SG_ 2566839294 EngInjectorMeteringRail1Press 157;
BA_ "SigType" SG_ 2566839294 EngInjectionCtrlPress "RANGE";
BA_ "SPN" SG_ 2566839294 EngInjectionCtrlPress 164;
BA_ "SigType" SG_ 2566844414 EngCoolantLevel "RANGE";
BA_ "SPN" SG_ 2566844414 EngCoolantLevel 111;
BA_ "SigType" SG_ 2566844414 EngCoolantPress "RANGE";
BA_ "SPN" SG_ 2566844414 EngCoolantPress 109;
BA_ "SigType" SG_ 2566844414 EngCrankcasePress "RANGE";
BA_ "SPN" SG_ 2566844414 EngCrankcasePress 101;
BA_ "SigType" SG_ 2566844414 EngOilPress "RANGE";
BA_ "SPN" SG_ 2566844414 EngOilPress 100;
BA_ "SigType" SG_ 2566844414 EngOilLevel "RANGE";
BA_ "SPN" SG_ 2566844414 EngOilLevel 98;
BA_ "SigType" SG_ 2566844414 EngExCrankcaseBlowbyPress "RANGE";
BA_ "SPN" SG_ 2566844414 EngExCrankcaseBlowbyPress 22;
BA_ "SigType" SG_ 2566844414 EngFuelDeliveryPress "RANGE";
BA_ "SPN" SG_ 2566844414 EngFuelDeliveryPress 94;
BA_ "SigType" SG_ 2633929726 TurningGearEngaged "DISCRETE";
BA_ "SPN" SG_ 2633929726 TurningGearEngaged 1206;
BA_ "SigType" SG_ 2633929726 SafetyWireStatus "DISCRETE";
BA_ "SPN" SG_ 2633929726 SafetyWireStatus 1205;
BA_ "SigType" SG_ 2633929726 ElectricalLoad "RANGE";
BA_ "SPN" SG_ 2633929726 ElectricalLoad 1204;
BA_ "SigType" SG_ 2566772222 EngVrblGometryTurbo1ActuatorPos "RANGE";
BA_ "SPN" SG_ 2566772222 EngVrblGometryTurbo1ActuatorPos 2795;
BA_ "SigType" SG_ 2566772222 EngVrblGmtryTrbArCtrlShtffValve "DISCRETE";
BA_ "SPN" SG_ 2566772222 EngVrblGmtryTrbArCtrlShtffValve 2792;
BA_ "SigType" SG_ 2566772222 EngExhstGsRcirculationValveCtrl "RANGE";
BA_ "SPN" SG_ 2566772222 EngExhstGsRcirculationValveCtrl 2791;
BA_ "SigType" SG_ 2566772222 EngTrb1ClcltedTurbineOutletTemp "RANGE";
BA_ "SPN" SG_ 2566772222 EngTrb1ClcltedTurbineOutletTemp 2790;
BA_ "SigType" SG_ 2566772222 EngTrb1ClclatedTurbineInletTemp "RANGE";
BA_ "SPN" SG_ 2566772222 EngTrb1ClclatedTurbineInletTemp 2789;
BA_ "SigType" SG_ 2633940734 EngRatedSpeed "RANGE";
BA_ "SPN" SG_ 2633940734 EngRatedSpeed 189;
BA_ "SigType" SG_ 2633940734 EngRatedPower "RANGE";
BA_ "SPN" SG_ 2633940734 EngRatedPower 166;
BA_ "SigType" SG_ 2566840318 ExhaustGasMass "RANGE";
BA_ "SPN" SG_ 2566840318 ExhaustGasMass 3236;
BA_ "SPN" SG_ 2566840318 AftrTrtmntIntakeDewPointMessage 3237;
BA_ "SPN" SG_ 2566840318 AftrTrtmntExhustDewPointMessage 3238;
BA_ "SigType" SG_ 2566840318 EstEngPrsticLossesPercentTorque "RANGE";
BA_ "SPN" SG_ 2566840318 EstEngPrsticLossesPercentTorque 2978;
BA_ "SigType" SG_ 2566840318 EngsDsrdOprtngSpdAsymmtryAdjstmn "RANGE";
BA_ "SPN" SG_ 2566840318 EngsDsrdOprtngSpdAsymmtryAdjstmn 519;
BA_ "SigType" SG_ 2566840318 EngsDesiredOperatingSpeed "RANGE";
BA_ "SPN" SG_ 2566840318 EngsDesiredOperatingSpeed 515;
BA_ "SigType" SG_ 2566840318 NominalFrictionPercentTorque "RANGE";
BA_ "SPN" SG_ 2566840318 NominalFrictionPercentTorque 514;
VAL_ 2348941054 TrnsShftSlctorDisplayModeSwitch 3 "NotAvailable" 2 "Error" 1 "On" 0 "Off" ;
VAL_ 2348941054 TransMode4 3 "TakeNoAction" 2 "Reserved" 1 "Enable" 0 "Disable" ;
VAL_ 2348941054 TransMode3 3 "TakeNoAction" 2 "Reserved" 1 "Enable" 0 "Disable" ;
VAL_ 2348941054 TransMode2 3 "TakeNoAction" 2 "Reserved" 1 "Enable" 0 "Disable" ;
VAL_ 2348941054 TransMode1 3 "TakeNoAction" 2 "Reserved" 1 "Enable" 0 "Disable" ;
VAL_ 2348941054 DisengageDiffLockRqCentralRear 2 "Reserved" 3 "TakeNoAction" 1 "DisengageDiffLock" 0 "EngageDiffLock" ;
VAL_ 2348941054 DisengageDiffLockRqCentralFront 2 "Reserved" 3 "TakeNoAction" 1 "DisengageDiffLock" 0 "EngageDiffLock" ;
VAL_ 2348941054 DisengageDiffLockRqCentral 2 "Reserved" 3 "TakeNoAction" 1 "DisengageDiffLock" 0 "EngageDiffLock" ;
VAL_ 2348941054 DisengageDiffLockRqRearAxle2 2 "Reserved" 3 "TakeNoAction" 1 "DisengageDiffLock" 0 "EngageDiffLock" ;
VAL_ 2348941054 DisengageDiffLockRqRearAxle1 2 "Reserved" 3 "TakeNoAction" 1 "DisengageDiffLock" 0 "EngageDiffLock" ;
VAL_ 2348941054 DisengageDiffLockRqFrontAxle2 2 "Reserved" 3 "TakeNoAction" 1 "DisengageDiffLock" 0 "EngageDiffLock" ;
VAL_ 2348941054 DisengageDiffLockRqFrontAxle1 2 "Reserved" 3 "TakeNoAction" 1 "DisengageDiffLock" 0 "EngageDiffLock" ;
VAL_ 2348941054 TransRqedGear 61 "Reserved" 222 "NeutralSelectorPos" 223 "ReverseSelectorPos" 224 "PsUnknownAnd_OrNoButtonsPressed" 225 "PrssOfMmntryBttnTRslctCrrentPos" 226 "BtwnRvrsAndPrkShiftSelectorPoss" 227 "BtwnNtrlAndRvrsShftSelectorPoss" 228 "BtwnDrvAndNtrlShiftSelectorPoss" 229 "BtwnD1AndDriveShiftSelectorPoss" 230 "BetweenD2AndD1ShiftSelectorPoss" 231 "BetweenD3AndD2ShiftSelectorPoss" 232 "BetweenD4AndD3ShiftSelectorPoss" 233 "BetweenD5AndD4ShiftSelectorPoss" 234 "BetweenD6AndD5ShiftSelectorPoss" 235 "BetweenD7AndD6ShiftSelectorPoss" 236 "BtwnTwoForwardShiftSelectorPoss" 237 "BtwnTwoReverseShiftSelectorPoss" 238 "BetweenTwoShiftSelectorPoss" 239 "D77thFrwrdSlctrPsRfrncdFrmDrive" 240 "D66thFrwrdSlctrPsRfrncdFrmDrive" 241 "D55thFrwrdSlctrPsRfrncdFrmDrive" 242 "D44thFrwrdSlctrPsRfrncdFrmDrive" 243 "D33rdFrwrdSlctrPsRfrncdFrmDrive" 244 "D22ndFrwrdSlctrPsRfrncdFrmDrive" 245 "D11stFrwrdSlctrPsRfrncdFrmDrive" 246 "Downshift2GearsFromCurrentPos" 247 "Downshift1GearFromCurrentPos" 248 "Upshift2GearsFromCurrentPos" 249 "Upshift1GearFromCurrentPos" 250 "ForwardLowPos" 251 "ParkPos" 252 "ForwardDrivePos" 253 "HoldCurrentGear" ;
VAL_ 2348941054 DisengageDrivelineRq 2 "Reserved" 3 "TakeNoAction" 1 "DisengageDriveline" 0 "AllowDrivelineEngagement" ;
VAL_ 2348941054 TorqueConverterLockupDisableRq 2 "Reserved" 3 "TakeNoAction" 1 "DisableTorqueConvertorLockup" 0 "AllowTorqueConvertorLockup" ;
VAL_ 2348941054 TransGearShiftInhibitRq 2 "Reserved" 3 "TakeNoAction" 1 "GearShiftsAreInhibited" 0 "GearShiftsAreAllowed" ;
VAL_ 2566841598 EngOverspeedTest 3 "NotAvailable" 2 "Reserved" 1 "EngOverspeedTestActive" 0 "EngOverspeedTestNotActive" ;
VAL_ 2566841598 EngAirShutoffCmdStatus 0 "ArShtffDsbldNtAttmptngTShtffEng" 3 "NotAvailable" 2 "Reserved" 1 "ArShtffEnbldAttmptngTShtffEngAr" ;
VAL_ 2566841598 EngAlarmOutputCmdStatus 3 "NotAvailable" 2 "Reserved" 1 "EngAlarmOutputCmdActive" 0 "EngAlarmOutputCmdNotActive" ;
VAL_ 2566841598 EngAlarmAcknowledge 3 "NotAvailable" 2 "Error" 1 "EngAlarmAcknowledgeActive" 0 "EngAlarmAcknowledgeNotActive" ;
VAL_ 2566841598 EngProtectionSystemConfig 3 "NotAvailable" 2 "Error" 1 "EnabledInCalib" 0 "DisabledInCalib" ;
VAL_ 2566841598 EngProtectionSystemTimerState 3 "NotAvailable" 2 "Error" 1 "Active" 0 "Inactive" ;
VAL_ 2566841598 EngPrtectionSystemTimerOverride 3 "NotAvailable" 2 "Error" 1 "Active" 0 "Inactive" ;
VAL_ 2566841598 EngPrtctnSystmApprchingShutdown 3 "NotAvailable" 2 "Error" 1 "Approaching" 0 "NotApproaching" ;
VAL_ 2566841598 EngPrtctionSystemHasShutdownEng 0 "No" ;
VAL_ 2566841598 EngWaitToStartLamp 3 "NotAvailable" 2 "Error" 1 "On" 0 "Off" ;
VAL_ 2566841598 RefrigerantHighPressSwitch 3 "NotAvailable" 2 "Error" 1 "PrssTHghCmprssrCltchMyBDsngaged" 0 "PressNormal" ;
VAL_ 2566841598 RefrigerantLowPressSwitch 3 "NotAvailable" 2 "Error" 1 "PrssTLwCmprssrCltchMyBDsengaged" 0 "PressNormal" ;
VAL_ 2566841598 A_CHighPressFanSwitch 3 "NotAvailable" 2 "Error" 1 "PressHighFanMayBeEngaged" 0 "PressNormal" ;
VAL_ 2566841598 EngIdleShutdownTimerFunction 3 "NotAvailable" 2 "Error" 1 "EnabledInCalib" 0 "DisabledInCalib" ;
VAL_ 2566841598 EngIdleShutdownTimerState 3 "NotAvailable" 2 "Error" 1 "Active" 0 "Inactive" ;
VAL_ 2566841598 EngIdleShutdownTimerOverride 3 "NotAvailable" 2 "Error" 1 "Active" 0 "Inactive" ;
VAL_ 2566841598 EngIdleShutdownDriverAlertMode 3 "NotAvailable" 2 "Error" 1 "Active" 0 "Inactive" ;
VAL_ 2566841598 EngIdleShutdownHasShutdownEng 1 "Yes" 0 "No" ;
VAL_ 2631859966 EngBuildHoursReset 2 "Reserved" 3 "TakeNoAction" 1 "Reset" 0 "DoNotReset" ;
VAL_ 2631859966 TripGroup2Proprietary 2 "Reserved" 3 "NotApplicable" 1 "Reset" 0 "TakeNoAction" ;
VAL_ 2631859966 TripGroup1 2 "Reserved" 3 "NotApplicable" 1 "Reset" 0 "TakeNoAction" ;
VAL_ 2566840830 RetarderLocation 15 "NotAvailable" 14 "Other" 6 "1101NotDefined" 5 "Trailer" 4 "Driveline" 3 "TransOutput" 2 "TransInput" 1 "EngExhaustBrake" 0 "EngCompressionReleaseBrake" ;
VAL_ 2566840830 RetarderType 15 "NotAvailable" 14 "Other" 5 "1101NotDefined" 4 "Exhaust" 3 "CompressionRelease" 2 "CooledFriction" 1 "Hyd" 0 "Electric_Magnetic" ;
VAL_ 2566844670 OperatorPTOMemorySelectSwitch 3 "notAvailable" 2 "error" 1 "PTOSetSpeedMemory2Selected" 0 "PTOSetSpeedMemory1Selected" ;
VAL_ 2566844670 EngPTOAccelerateSwitch 3 "NotAvailable" 2 "Error" 1 "On" 0 "Off" ;
VAL_ 2566844670 EngPTOResumeSwitch 3 "NotAvailable" 2 "Error" 1 "On" 0 "Off" ;
VAL_ 2566844670 EngPTOCoast_DecelerateSwitch 3 "NotAvailable" 2 "Error" 1 "On" 0 "Off" ;
VAL_ 2566844670 EngPTOSetSwitch 3 "NotAvailable" 2 "Error" 1 "On" 0 "Off" ;
VAL_ 2566844670 EngRmtPTOVriableSpeedCtrlSwitch 3 "NotAvailable" 2 "Error" 1 "On" 0 "Off" ;
VAL_ 2566844670 EngRmtPTOPrprgrmmdSpdCtrlSwitch 3 "NotAvailable" 2 "Error" 1 "On" 0 "Off" ;
VAL_ 2566844670 EngPTOEnableSwitch 3 "NotAvailable" 2 "Error" 1 "On" 0 "Off" ;
VAL_ 2566844670 RmtPTOPrprgrmmdSpeedCtrlSwitch2 3 "NotAvailable" 2 "Error" 1 "On" 0 "Off" ;
VAL_ 2566844670 AuxInputIgnoreSwitch 3 "NotAvailable" 2 "Error" 1 "On" 0 "Off" ;
VAL_ 2566770174 RearWasherFunction 7 "NotAvailable" 4 "110Reserved" 3 "High" 2 "Medium" 1 "Low" 0 "Off" ;
VAL_ 2566770174 FrontOperatorWasherSwitch 7 "NotAvailable" 4 "110Reserved" 3 "High" 2 "Medium" 1 "Low" 0 "Off" ;
VAL_ 2566770174 FrontNonoperatorWasherSwitch 7 "NotAvailable" 4 "110Reserved" 3 "High" 2 "Medium" 1 "Low" 0 "Off" ;
VAL_ 2566770174 RearWiperSwitch 7 "1110Reserved" 6 "Mist" 5 "Delayed2" 4 "Delayed1" 2 "Medium" 15 "NotAvailable" 3 "High" 1 "Low" 0 "Off" ;
VAL_ 2566770174 FrontOperatorWiperSwitch 7 "1110Reserved" 6 "Mist" 5 "Delayed2" 4 "Delayed1" 2 "Medium" 15 "NotAvailable" 3 "High" 1 "Low" 0 "Off" ;
VAL_ 2566770174 FrontNonoperatorWiperSwitch 7 "1110Reserved" 6 "Mist" 5 "Delayed2" 4 "Delayed1" 2 "Medium" 15 "NotAvailable" 3 "High" 1 "Low" 0 "Off" ;
VAL_ 2566769662 EngAltDroopAuxInputSelect 15 "NotAvailable" 14 "ErrorCondition" 1 "thr1101OnOfAltDrpSttng1Thrgh13I" 0 "NormalDroopSettingIsSelected" ;
VAL_ 2566769662 EngAltDroopRemoteAccelSelect 15 "NotAvailable" 14 "ErrorCondition" 1 "thr1101OnOfAltDrpSttng1Thrgh13I" 0 "NormalDroopSettingIsSelected" ;
VAL_ 2566769662 EngAltDroopAccel2Select 15 "NotAvailable" 14 "ErrorCondition" 1 "thr1101OnOfAltDrpSttng1Thrgh13I" 0 "NormalDroopSettingIsSelected" ;
VAL_ 2566769662 EngAltDroopAccel1Select 15 "NotAvailable" 14 "ErrorCondition" 1 "thr1101OnOfAltDrpSttng1Thrgh13I" 0 "NormalDroopSettingIsSelected" ;
VAL_ 2566769662 EngAltRatingSelect 1 "IndctsThtAltPwrFling1IsSelected" 0 "IndctsThtMxPwrFuelingIsSelected" ;
VAL_ 2566769662 EngAltLowIdleSwitch 3 "NotAvailableUnused" 2 "Error" 1 "AltLowIdlePointIsSelected" 0 "DefaultLowIdlePointIsSelected" ;
VAL_ 2566769662 EngSynchronizationSwitch 3 "NotAvailableUnused" 2 "Error" 1 "FunctionalityIsEnabled" 0 "FunctionalityIsDisabled" ;
VAL_ 2566769662 EngAuxGovernorSwitch 2 "ErrorCondition" 1 "AuxGovernorIsEnabled" 0 "AuxGovernorIsDisabled" ;
VAL_ 2566768638 EngAltDroopAuxInputSelectState 14 "SAEReserved" 1 "thr1101CtrlSttIsOnOfAltDrpSttng" 0 "CtrlStateIsNormalDroopSetting" ;
VAL_ 2566768638 EngAltDrpRemoteAccelSelectState 15 "NotAvailable" 14 "SAEReserved" 1 "thr1101CtrlSttIsOnOfAltDrpSttng" 0 "CtrlStateIsNormalDroopSetting" ;
VAL_ 2566768638 EngAltDroopAccel2SelectState 15 "NotAvailable" 14 "SAEReserved" 1 "thr1101CtrlsSttIsOnOfAltDrpSttn" 0 "CtrlsStateIsNormalDroopSetting" ;
VAL_ 2566768638 EngAltDroopAccel1SelectState 15 "NotAvailable" 14 "SAEReserved" 1 "thr1101CtrlSttIsOnOfAltDrpSttng" 0 "CtrlStateIsNormalDroopSetting" ;
VAL_ 2566768638 EngAltRatingSelectState 1 "CtrlStateIsAltPowerFueling1" 0 "CtrlStateIsMaxPowerFueling" ;
VAL_ 2566768638 EngAltLowIdleSelectState 3 "NotAvailable" 2 "SAEReserved" 1 "AltIdleState" 0 "NormalIdleState" ;
VAL_ 2566768638 EngMultiUnitSyncState 3 "NotAvailable" 2 "SAEReserved" 1 "CtrlStateIsFunctionalityEnabled" 0 "CtrlStteIsFunctionalityDisabled" ;
VAL_ 2566768638 EngAuxGovernorState 3 "NotAvailable" 2 "SAEReserved" 1 "CtrlStateIsAuxGovernorEnabled" 0 "CtrlStateIsAuxGovernorDisabled" ;
VAL_ 2365443326 HighLowBeamSwitch 3 "NotAvailable" 2 "Error" 1 "HighBeamSelected" 0 "LowBeamSelected" ;
VAL_ 2365443326 HazardLightSwitch 3 "NotAvailable" 2 "Error" 1 "HazardLampsToBeFlashing" 0 "HazardLampsToBeOff" ;
VAL_ 2365443326 TurnSignalSwitch 2 "RightTurnToBeFlashing" 15 "NotAvailable" 14 "Error" 3 "1101Reserved" 1 "LeftTurnToBeFlashing" 0 "NoTurnBeingSignaled" ;
VAL_ 2365443326 MainLightSwitch 9 "1101Reserved" 8 "DlydOffPsByWhchThOprtrSlctsThtA" 4 "0111Reserved" 2 "HdlghtOnPsByWhchThOprtrSlctsTht" 15 "NotAvailable" 14 "Error" 3 "HdlghtAndPrkOnPsByWhchThOprtrSl" 1 "PrkOnPsByWhchThOprtrSlctsThtThP" 0 "OffPsByWhchThOprtrSlctsThtNnOfT" ;
VAL_ 2365443326 WorkLightSwitch 5 "1101Reserved" 4 "WrkLghtCmbntn4OnPsByWhchThOprtr" 2 "WrkLghtCmbntn2OnPsByWhchThOprtr" 15 "NotAvailable" 14 "Error" 3 "WrkLghtCmbntn3OnPsByWhchThOprtr" 1 "WrkLghtCmbntn1OnPsByWhchThOprtr" 0 "OffPsByWhchThOprtrSlctsThtNnOfT" ;
VAL_ 2566802686 BlackOutWorkLampSelect 3 "NotSupported" 2 "Reserved" 1 "On" 0 "Off" ;
VAL_ 2566802686 NightVisionIlluminatorSelect 3 "NotSupported" 2 "Reserved" 1 "On" 0 "Off" ;
VAL_ 2566802686 BlackOutBrake_StopLampSelect 3 "NotSupported" 2 "Reserved" 1 "On" 0 "Off" ;
VAL_ 2566802686 ConvoyDrivingLampSelect 3 "NotSupported" 2 "Reserved" 1 "On" 0 "Off" ;
VAL_ 2566802686 ConvoyLampSelect 3 "NotSupported" 2 "Reserved" 1 "On" 0 "Off" ;
VAL_ 2566802686 FrontBlackOutMarkerLampSelect 3 "NotSupported" 2 "Reserved" 1 "On" 0 "Off" ;
VAL_ 2566802686 RearBlackOutMarkerSelect 3 "NotSupported" 2 "Reserved" 1 "On" 0 "Off" ;
VAL_ 2566774014 SlowVesselModeStatus 3 "TakeNoAction" 2 "Reserved" 1 "SlowVesselModeIsACTIVE" 0 "SlowVesselModeIsOFF" ;
VAL_ 2566774014 TrollingModeStatus 3 "TakeNoAction" 2 "Reserved" 1 "TrollingModeIsACTIVE" 0 "TrollingModeIsOFF" ;
VAL_ 2566774014 EngThrttlSynchrnztionModeStatus 15 "TakeNoAction" 5 "1110Reserved" 4 "SynchronizedMaster" 3 "SynchronizedStarboard" 2 "SynchronizedPort" 1 "SynchronizedCenter" 0 "NotSynchronized" ;
VAL_ 2432595710 DisplayDeadbands 15 "NotAvailable" 3 "1110Reserved" 2 "Wide_24mm" 1 "Standard_12mm" 0 "Narrow_45mm" ;
VAL_ 2432595710 LEDPatternCtrl 15 "NotAvailable" 3 "1110Reserved" 2 "7Channel" 1 "Offset" 0 "5Channel" ;
VAL_ 2432595710 LEDDisplayDeadbandCtrl 15 "NotAvailableNotApplicable" 5 "1110Reserved" 4 "_1Mm" 3 "_5Mm" 2 "_24Mm" 1 "_12Mm" 0 "_45Mm" ;
VAL_ 2432595710 LEDDisplayModeCtrl 15 "NotAvailableNotApplicable" 3 "1110Reserved" 2 "CenterOnGradeDisplayMode2" 1 "OffsetOnGradeDisplayMode" 0 "CenterOnGradeDisplayMode1" ;
VAL_ 2432595710 LEDDisplayData1 32 "LowCoarseLEDOn" 16 "LowFineLEDOn" 8 "OngradeLEDOn" 4 "HighFineLEDOn" 2 "HighCoarseLEDOn" ;
VAL_ 2365486590 LaserReceiverType 1 "LinearLaserReceiver" 0 "Reserved" ;
VAL_ 2365485566 LaserTracerInformation 32 "Curb" 16 "Stringline" 8 "PreviousPass" 4 "ValidTarget" 2 "LaserIsReady" 1 "LaserPowerIsOn" ;
VAL_ 2365485566 LEDDisplayData2 64 "RightLEDOn" 32 "LeftLEDOn" 16 "DownLEDOn" 8 "UpLEDOn" 4 "OngradeCLEDOn" 2 "OngradeBLEDOn" 1 "OngradeALEDOn" ;
VAL_ 2364542462 SdshftDsrdBldOffsetOperatorCtrl 15 "NotInstalled" 14 "ErrorIndicator" 4 "1101Reserved" 3 "AutomaticOperatorCtrlRq" 2 "ManualOperatorCtrlRq" 0 "NoOperatorCtrlRq" 1 "MomentaryOperatorCtrlRq" ;
VAL_ 2364542462 SdshftBldCtrlMdeOperatorControl 15 "NotInstalled" 14 "ErrorIndicator" 4 "1101Reserved" 3 "AutomaticOperatorCtrlRq" 2 "ManualOperatorCtrlRq" 0 "NoOperatorCtrlRq" 1 "OprtrCtrlSttCnBRdInTwWysOnMthdU" ;
VAL_ 2364542462 RghtDsrdBladeOffsetOperatorCtrl 15 "NotInstalled" 14 "ErrorIndicator" 3 "1101Reserved" 2 "DecrementOperatorCtrlRq" 0 "NoOperatorCtrlRq" 1 "OprtrCtrlSttCnBRdInTwWysOnMthdU" ;
VAL_ 2364542462 RghtBldeCtrlModeOperatorControl 15 "NotInstalled" 14 "ErrorIndicator" 3 "AutomaticOperatorCtrlRq" 2 "ManualOperatorCtrlRq" 0 "NoChange" 1 "MomentaryOperatorCtrlRq" ;
VAL_ 2364542462 LftDsredBladeOffsetOperatorCtrl 15 "NotInstalled" 14 "ErrorIndicator" 3 "1101Reserved" 2 "DecrementOperatorCtrlRq" 0 "NoOperatorCtrlRq" 1 "OprtrCtrlSttCnBRdInTwWysOnMthdU" ;
VAL_ 2364542462 LftBladeCtrlModeOperatorControl 15 "NotInstalled" 14 "ErrorIndicator" 12 "1101Reserved" 3 "AutomaticOperatorCtrlRq" 2 "ManualOperatorCtrlRq" 0 "NoChange" 1 "OprtrCtrlSttCnBRdInTwWysOnMthdU" ;
VAL_ 2364542462 BladeAutoModeCmd 15 "NotSupported" 14 "ErrorIndicator" 4 "AutoNotAllowed" 3 "SrvcMdAtAllwdOnlyDrngSrvceModes" 2 "SspndAtTmprarilySuspendAutoMode" 1 "ActvtyAllwsAtMstDtctOprtrBfrAtA" 0 "AutoAllowed" ;
VAL_ 2364542462 DesiredGradeOffsetSwitch 15 "NotInstalled" 14 "ErrorIndicator" 2 "DecrementButtonPressed" 0 "NoButtonPressed" 1 "SwtchSttCnBRdInTwWysOnMthdUssTh" ;
VAL_ 2364542462 BladeCtrlModeSwitch 15 "NotInstalled" 14 "ErrorIndicator" 3 "AutomaticButtonPressed" 2 "ManualButtonPressed" 0 "NoButtonPressed" 1 "SwtchSttCnBRdInTwWysOnMthdUssTh" ;
VAL_ 2633883646 FrontWheelDriveActuatorStatus 3 "NotAvailable" 2 "Error" 1 "FrontWheelDriveActuatorEngaged" 0 "FrntWhelDriveActuatorNotEngaged" ;
VAL_ 2633880062 FMSstandardRqsSupported 3 "DontCare" 2 "Reserved" 1 "OnRqModeIsSupported" 0 "OnRqModeIsNotSupported" ;
VAL_ 2633880062 FMSstandardDiagnosticsSupported 3 "DontCare" 2 "Reserved" 1 "DiagnosticsIsSupported" 0 "DiagnosticsIsNotSupported" ;
VAL_ 2566806526 LnDprtureIndicationEnableStatus 3 "NotUsed" 2 "Reserved" 1 "LaneDepartureIndicationEnabled" 0 "LaneDepartureIndicationDisabled" ;
VAL_ 2566806526 LaneTrackingStatusLeftSide 3 "DontCare_TakeNoAction" 2 "Reserved" 1 "TrackingLeftSide" 0 "NotTrackingLeftSide" ;
VAL_ 2566806526 LaneTrackingStatusRightSide 3 "DontCare_TakeNoAction" 2 "Reserved" 1 "TrackingRightSide" 0 "NotTrackingRightSide" ;
VAL_ 2431649790 LaneDepartureImminentLeftSide 3 "NotUsed" 2 "Reserved" 1 "Imminent" 0 "NotImminent" ;
VAL_ 2431649790 LaneDepartureImminentRightSide 3 "NotUsed" 2 "Reserved" 1 "Imminent" 0 "NotImminent" ;
VAL_ 2633929214 EngFuelLeakage2 3 "NotAvailable" 2 "Error" 1 "LeakageDetected" 0 "NoLeakageDetected" ;
VAL_ 2633929214 EngFuelLeakage1 3 "NotAvailable" 2 "Error" 1 "LeakageDetected" 0 "NoLeakageDetected" ;
VAL_ 2566831614 FanDriveState 15 "NotAvailable" 14 "Other" 13 "EngBrake" 12 "Timer" 11 "A_CSystem" 10 "TransRetarder" 9 "ManualCtrl" 8 "NotDefined" 7 "DefaultOperation" 6 "ExcessiveHydOilTemp" 5 "ExcessiveTransOilTemp" 4 "ExcessiveEngCoolantTemp" 3 "ExcessiveEngOilTemp" 2 "ExcessiveEngAirTemp" 1 "EngSystemGeneral" 0 "FanOff" ;
VAL_ 2566820094 EngTorqueLimitFeature 7 "NotAvailable" 5 "110Reserved" 4 "CurrentTorqueRating" 3 "PreviousTorqueRating" 2 "FirstTorqueRating" 1 "HighestTorqueRating" 0 "Reserved" ;
VAL_ 2566820094 TorqueLimitingFeatureStatus 3 "NotAvailable" 2 "Error" 1 "Enabled" 0 "Disabled" ;
VAL_ 2566802174 TransMode1Indicator 3 "NotAvailable" 2 "Error" 1 "TransMode1Active" 0 "TransMode1NotActive" ;
VAL_ 2566802174 TransMode2Indicator 3 "NotAvailable" 2 "Error" 1 "TransMode2Active" 0 "TransMode2NotActive" ;
VAL_ 2566802174 TransMode3Indicator 3 "NotAvailable" 2 "Error" 1 "TransMode3Active" 0 "TransMode3NotActive" ;
VAL_ 2566802174 TransMode4Indicator 3 "NotAvailable" 2 "Error" 1 "TransMode4Active" 0 "TransMode4NotActive" ;
VAL_ 2566802174 TransShiftInhibitIndicator 3 "TakeNoAction" 2 "Reserved" 1 "ActiveShiftIsInhibited" 0 "InactiveShiftIsNotInhibited" ;
VAL_ 2566802174 TransEngCrankEnable 3 "NotAvailable" 2 "Error" 1 "CrnkngEnbldEngCrnkngIsAllwdByTr" 0 "CrnkngDsbldEngCrnkngIsPrhbtdByT" ;
VAL_ 2566802174 ActiveShiftConsoleIndicator 3 "NotAvailable" 2 "Reserved" 1 "SecondShiftConsoleIsActive" 0 "PrimaryShiftConsoleIsActive" ;
VAL_ 2566802174 TransReadyForBrakeRelease 3 "DontCare" 2 "Reserved" 1 "TransReadyForBrakeRelease" 0 "TransNotReadyForBrakeRelease" ;
VAL_ 2566802174 TransRqedRangeDisplayFlashState 3 "TakeNoAction" 2 "Reserved" 1 "ActvTrnsRqdRngDsplyShldBFlshing" 0 "InctvTrnsRqdRngDsplyShldNtBFlsh" ;
VAL_ 2566802174 TransRqedRangeDisplayBlankState 3 "TakeNoAction" 2 "Reserved" 1 "ActvTrnsRqdRngDsplyShldBBlanked" 0 "InctvTrnsRqdRngDsplyShldNtBBlnk" ;
VAL_ 2633942014 TransForwardDirectionSwitch 3 "NotAvailable" 2 "Error" 1 "On" 0 "Off" ;
VAL_ 2633942014 TransNeutralSwitch 3 "NotAvailable" 2 "Error" 1 "On" 0 "Off" ;
VAL_ 2633942014 TransReverseDirectionSwitch 3 "NotAvailable" 2 "Error" 1 "On" 0 "Off" ;
VAL_ 2633942014 TransLowRangeSenseSwitch 3 "NotAvailable" 2 "Error" 1 "On" 0 "Off" ;
VAL_ 2633942014 TransHighRangeSenseSwitch 3 "NotAvailable" 2 "Error" 1 "On" 0 "Off" ;
VAL_ 2633943038 TransInertiaBrakeActuator 3 "NotAvailable" 2 "Error" 1 "On" 0 "Off" ;
VAL_ 2633943038 TransDefuelActuator 3 "NotAvailable" 2 "Error" 1 "On" 0 "Off" ;
VAL_ 2633943038 TransLockupClutchActuator 3 "NotAvailable" 2 "Error" 1 "On" 0 "Off" ;
VAL_ 2633943038 TransClutchActuator 3 "NotAvailable" 2 "Error" 1 "On" 0 "Off" ;
VAL_ 2633943038 TransSplitterIndirectActuator 3 "NotAvailable" 2 "Error" 1 "On" 0 "Off" ;
VAL_ 2633943038 TransSplitterDirectActuator 3 "NotAvailable" 2 "Error" 1 "On" 0 "Off" ;
VAL_ 2633943038 TransRangeLowActuator 3 "NotAvailable" 2 "Error" 1 "On" 0 "Off" ;
VAL_ 2633943038 TransRangeHighActuator 3 "NotAvailable" 2 "Error" 1 "On" 0 "Off" ;
VAL_ 2633943038 TransShiftFingerGearActuator2 3 "NotAvailable" 2 "Error" 1 "On" 0 "Off" ;
VAL_ 2633943038 TransShiftFingerRailActuator2 3 "NotAvailable" 2 "Error" 1 "On" 0 "Off" ;
VAL_ 2633943038 TransShiftFingerGearActuator1 3 "NotAvailable" 2 "Error" 1 "On" 0 "Off" ;
VAL_ 2633943038 TransShiftFingerRailActuator1 3 "NotAvailable" 2 "Error" 1 "On" 0 "Off" ;
VAL_ 2633943038 TrnsShftFngrCenterRailIndicator 3 "NotAvailable" 2 "Error" 1 "On" 0 "Off" ;
VAL_ 2633943038 TrnsShftFngrEngagementIndicator 3 "NotAvailable" 2 "Error" 1 "On" 0 "Off" ;
VAL_ 2633943038 TrnsShiftFingerNeutralIndicator 3 "NotAvailable" 2 "Error" 1 "On" 0 "Off" ;
VAL_ 2364539646 ProgressiveShiftDisable 2 "Reserved" 3 "TakeNoAction" 1 "ProgressiveShiftIsDisabled" 0 "ProgressiveShiftIsNotDisabled" ;
VAL_ 2364539646 EngMomentaryOverspeedEnable 2 "Reserved" 3 "TakeNoAction" 1 "MomentaryEngOverspeedIsEnabled" 0 "MomentaryEngOverspeedIsDisabled" ;
VAL_ 2364539646 TransShiftInProcess 3 "NotAvailable" 2 "Error" 1 "ShiftInProcess" 0 "ShiftIsNotInProcess" ;
VAL_ 2364539646 TorqueConverterLockupEngaged 3 "NotAvailable" 2 "Error" 1 "TorqueConverterLockupEngaged" 0 "TorqueConverterLockupDisengaged" ;
VAL_ 2364539646 TransDrivelineEngaged 3 "NotAvailable" 2 "Error" 1 "DrivelineEngaged" 0 "DrivelineDisengaged" ;
VAL_ 2565868542 SterableLiftAxleLoweringInhibit 3 "NotAvailable" 2 "Reserved" 1 "LoweringInhibited" 0 "LoweringAllowed" ;
VAL_ 2565868542 TypeOfSteerTrans 15 "NotAvailable" 4 "1110ReservedForSAEAssignment" 3 "HybrdStrTrnsAStrngTrnsmssnInWhc" 2 "PrlyElctrcStrTrnsAStrngTrnsmssn" 1 "PrlyHydStrTrnsAStrngTrnsmssnInW" 0 "PrlyMchStrTrnsAStrngTrnsmssnInW" ;
VAL_ 2565868542 TypeOfSteerForces 15 "NotAvailable" 4 "1110ReservedForSAEAssignment" 3 "SlfTrckngStrEqpmntASystmDsgndTC" 2 "FllPwrStrEqpmntStrngFrcsArPrvdd" 1 "PwrAssstdStrEqpmntStrngFrcsRslt" 0 "MnlStrEqpmntStrngFrcsRsltSllyFr" ;
VAL_ 2565868542 SteerType 15 "NotAvailable" 2 "1110ReservedForAssignmentBySAE" 1 "AxStrEqpmntASystmInWhchWhlsOnAx" 0 "MnStrSystmStrngEqpmntOfAVhclWhc" ;
VAL_ 2565868542 StatusOfSteerAxle 15 "NotAvailable" 6 "1110ReservedForSAEAssignment" 5 "AxleSteerInSpecialMode" 4 "AxleNotActiveBecauseOfAnError" 3 "AxleCenteredBecauseOfAnError" 2 "AxleCentered" 1 "AxleSteerActive" 0 "AxleSteerNotActive" ;
VAL_ 2633941758 TransOutputRetarder 3 "NotAvailable" 2 "Error" 1 "On" 0 "Off" ;
VAL_ 2565865726 EngCoolantLoadIncrease 3 "NotAvailable" 2 "Error" 1 "CoolantLoadIncreasePossible" 0 "NoCoolantLoadIncrease" ;
VAL_ 2565865726 RetarderEnableShiftAssistSwitch 3 "NotAvailable" 2 "Error" 1 "RetarderShiftAssistEnabled" 0 "RetarderShiftAssistDisabled" ;
VAL_ 2565865726 RetarderEnableBrakeAssistSwitch 3 "NotAvailable" 2 "Error" 1 "RetarderBrakeAssistEnabled" 0 "RetarderBrakeAssistDisabled" ;
VAL_ 2633935358 EngExhstGsOxygnSnsrClsdLpOprton 3 "DontCare_TakeNoAction" 2 "Reserved" 1 "CmdToEnableFunction" 0 "CmdToDisableFunction" ;
VAL_ 2365447166 Jystck3GripXAxisDetentPosStatus 3 "NotAvailable" 2 "ErrorIndicator" 1 "InDetentPos" 0 "NotInDetentPos" ;
VAL_ 2365447166 Jystck3GripYAxisDetentPosStatus 3 "NotAvailable" 2 "ErrorIndicator" 1 "InDetentPos" 0 "NotInDetentPos" ;
VAL_ 2365447166 Jystck3ThetaAxisDetentPosStatus 3 "NotAvailable" 2 "ErrorIndicator" 1 "InDetentPos" 0 "NotInDetentPos" ;
VAL_ 2365447166 Jystck3ThtAxsClckwsPstvPsStatus 3 "NotAvailable" 2 "ErrorIndicator" 1 "OnPositiveSideOfNeutral" 0 "NotOnPositiveSideOfNeutral" ;
VAL_ 2365447166 Jystck3ThtAxsCntrClckwsNgtvPsStt 3 "NotAvailable" 2 "ErrorIndicator" 1 "OnNegativeSideOfNeutral" 0 "NotOnNegativeSideOfNeutral" ;
VAL_ 2365447166 Jystck3ThtaAxisNeutralPosStatus 3 "NotAvailable" 2 "ErrorIndicator" 1 "InNeutralPos" 0 "NotInNeutralPos" ;
VAL_ 2365447166 Jystck3GrpYAxsLvrFrwrdPstvPsStts 3 "NotAvailable" 2 "ErrorIndicator" 1 "OnPositiveSideOfNeutral" 0 "NotOnPositiveSideOfNeutral" ;
VAL_ 2365447166 Jystck3GrpYAxsLvrBckNgtvPsSttus 3 "NotAvailable" 2 "ErrorIndicator" 1 "OnNegativeSideOfNeutral" 0 "NotOnNegativeSideOfNeutral" ;
VAL_ 2365447166 Jystck3GrpYAxisNeutralPosStatus 3 "NotAvailable" 2 "ErrorIndicator" 1 "InNeutralPos" 0 "NotInNeutralPos" ;
VAL_ 2365447166 Jystck3GrpXAxsLvrRghtPstvPsStts 3 "NotAvailable" 2 "ErrorIndicator" 1 "OnPositiveSideOfNeutral" 0 "NotOnPositiveSideOfNeutral" ;
VAL_ 2365447166 Jystck3GrpXAxsLvrLftNgtvPsSttus 3 "NotAvailable" 2 "ErrorIndicator" 1 "OnNegativeSideOfNeutral" 0 "NotOnNegativeSideOfNeutral" ;
VAL_ 2365447166 Jystck3GrpXAxisNeutralPosStatus 3 "NotAvailable" 2 "ErrorIndicator" 1 "OnNegativeSideOfNeutral" 0 "NotOnNegativeSideOfNeutral" ;
VAL_ 2365446654 Jystck2GripXAxisDetentPosStatus 3 "NotAvailable" 2 "ErrorIndicator" 1 "InDetentPos" 0 "NotInDetentPos" ;
VAL_ 2365446654 Jystck2GripYAxisDetentPosStatus 3 "NotAvailable" 2 "ErrorIndicator" 1 "InDetentPos" 0 "NotInDetentPos" ;
VAL_ 2365446654 Jystck2ThetaAxisDetentPosStatus 3 "NotAvailable" 2 "ErrorIndicator" 1 "InDetentPos" 0 "NotInDetentPos" ;
VAL_ 2365446654 Jystck2ThtAxsClckwsPstvPsStatus 3 "NotAvailable" 2 "ErrorIndicator" 1 "OnPositiveSideOfNeutral" 0 "NotOnPositiveSideOfNeutral" ;
VAL_ 2365446654 Jystck2ThtAxsCntrClckwsNgtvPsStt 3 "NotAvailable" 2 "ErrorIndicator" 1 "OnNegativeSideOfNeutral" 0 "NotOnNegativeSideOfNeutral" ;
VAL_ 2365446654 Jystck2ThtaAxisNeutralPosStatus 3 "NotAvailable" 2 "ErrorIndicator" 1 "InNeutralPos" 0 "NotInNeutralPos" ;
VAL_ 2365446654 Jystck2GrpYAxsLvrFrwrdPstvPsStts 3 "NotAvailable" 2 "ErrorIndicator" 1 "OnPositiveSideOfNeutral" 0 "NotOnPositiveSideOfNeutral" ;
VAL_ 2365446654 Jystck2GrpYAxsLvrBckNgtvPsSttus 3 "NotAvailable" 2 "ErrorIndicator" 1 "OnNegativeSideOfNeutral" 0 "NotOnNegativeSideOfNeutral" ;
VAL_ 2365446654 Jystck2GrpYAxisNeutralPosStatus 3 "NotAvailable" 2 "ErrorIndicator" 1 "InNeutralPos" 0 "NotInNeutralPos" ;
VAL_ 2365446654 Jystck2GrpXAxsLvrRghtPstvPsStts 3 "NotAvailable" 2 "ErrorIndicator" 1 "OnPositiveSideOfNeutral" 0 "NotOnPositiveSideOfNeutral" ;
VAL_ 2365446654 Jystck2GrpXAxsLvrLftNgtvPsSttus 3 "NotAvailable" 2 "ErrorIndicator" 1 "OnNegativeSideOfNeutral" 0 "NotOnNegativeSideOfNeutral" ;
VAL_ 2365446654 Jystck2GrpXAxisNeutralPosStatus 3 "NotAvailable" 2 "ErrorIndicator" 1 "OnNegativeSideOfNeutral" 0 "NotOnNegativeSideOfNeutral" ;
VAL_ 2365446142 Jystck1GripXAxisDetentPosStatus 3 "NotAvailable" 2 "ErrorIndicator" 1 "InDetentPos" 0 "NotInDetentPos" ;
VAL_ 2365446142 Jystck1GripYAxisDetentPosStatus 3 "NotAvailable" 2 "ErrorIndicator" 1 "InDetentPos" 0 "NotInDetentPos" ;
VAL_ 2365446142 Jystck1ThetaAxisDetentPosStatus 3 "NotAvailable" 2 "ErrorIndicator" 1 "InDetentPos" 0 "NotInDetentPos" ;
VAL_ 2365446142 Jystck1ThtAxsClckwsPstvPsStatus 3 "NotAvailable" 2 "ErrorIndicator" 1 "OnPositiveSideOfNeutral" 0 "NotOnPositiveSideOfNeutral" ;
VAL_ 2365446142 Jystck1ThtAxsCntrClckwsNgtvPsStt 3 "NotAvailable" 2 "ErrorIndicator" 1 "OnNegativeSideOfNeutral" 0 "NotOnNegativeSideOfNeutral" ;
VAL_ 2365446142 Jystck1ThtaAxisNeutralPosStatus 3 "NotAvailable" 2 "ErrorIndicator" 1 "InNeutralPos" 0 "NotInNeutralPos" ;
VAL_ 2365446142 Jystck1GrpYAxsLvrFrwrdPstvPsStts 3 "NotAvailable" 2 "ErrorIndicator" 1 "OnPositiveSideOfNeutral" 0 "NotOnPositiveSideOfNeutral" ;
VAL_ 2365446142 Jystck1GrpYAxsLvrBckNgtvPsSttus 3 "NotAvailable" 2 "ErrorIndicator" 1 "OnNegativeSideOfNeutral" 0 "NotOnNegativeSideOfNeutral" ;
VAL_ 2365446142 Jystck1GrpYAxisNeutralPosStatus 3 "NotAvailable" 2 "ErrorIndicator" 1 "InNeutralPos" 0 "NotInNeutralPos" ;
VAL_ 2365446142 Jystck1GrpXAxsLvrRghtPstvPsStts 3 "NotAvailable" 2 "ErrorIndicator" 1 "OnPositiveSideOfNeutral" 0 "NotOnPositiveSideOfNeutral" ;
VAL_ 2365446142 Jystck1GrpXAxsLvrLftNgtvPsSttus 3 "NotAvailable" 2 "ErrorIndicator" 1 "OnNegativeSideOfNeutral" 0 "NotOnNegativeSideOfNeutral" ;
VAL_ 2365446142 Jystck1GrpXAxisNeutralPosStatus 3 "NotAvailable" 2 "ErrorIndicator" 1 "InNeutralPos" 0 "NotInNeutralPos" ;
VAL_ 2633929726 TurningGearEngaged 1 "TurningGearIsEngaged" 0 "TurningGearIsNotEngaged" ;
VAL_ 2633929726 SafetyWireStatus 3 "NotAvailable" 2 "Error" 1 "SafetyWireHasBeenActivated" 0 "SafetyWireHasNotBeenActivated" ;
VAL_ 2566772222 EngVrblGmtryTrbArCtrlShtffValve 3 "NotAvailable" 2 "Reserved" 1 "VGTAirCtrlShutoffValveIsOn" 0 "VGTAirCtrlShutoffValveIsOff" ;
